VERSION "ae3c"

NS_ :

BS_:

BU_: Brightloop_Can_Loader ECU HVHV DCDC

BO_ 2147487747 BL1_Node3Status: 8 HVHV
 SG_ BPath1AcModeActivated m0 : 63|1@1+ (1,0) [0|1] ""  ECU
 SG_ BPath1AcUfpError m0 : 62|1@1+ (1,0) [0|1] ""  ECU
 SG_ BPath1AcOfpError m0 : 61|1@1+ (1,0) [0|1] ""  ECU
 SG_ NPath1AcFunctionMode m0 : 58|3@1+ (1,0) [0|7] ""  ECU
 SG_ BPath1FlgCapaError m0 : 57|1@1+ (1,0) [0|1] ""  ECU
 SG_ BPath2FlgCapaError m1 : 57|1@1+ (1,0) [0|1] ""  ECU
 SG_ BPath1ErrVAuxCell m0 : 56|1@1+ (1,0) [0|1] ""  ECU
 SG_ BPath2ErrVAuxCell m1 : 56|1@1+ (1,0) [0|1] ""  ECU
 SG_ IPath1Unbalance m0 : 48|8@1+ (0.25,0) [0|63.75] "A"  ECU
 SG_ IPath2Unbalance m1 : 48|8@1+ (0.25,0) [0|63.75] "A"  ECU
 SG_ BPath1RcpWarning m0 : 47|1@1+ (1,0) [0|1] ""  ECU
 SG_ BPath2RcpWarning m1 : 47|1@1+ (1,0) [0|1] ""  ECU
 SG_ BPath1OcpError m0 : 46|1@1+ (1,0) [0|1] ""  ECU
 SG_ BPath2OcpError m1 : 46|1@1+ (1,0) [0|1] ""  ECU
 SG_ BPath1OtpError m0 : 45|1@1+ (1,0) [0|1] ""  ECU
 SG_ BPath2OtpError m1 : 45|1@1+ (1,0) [0|1] ""  ECU
 SG_ BPath1SideBUvpError m0 : 44|1@1+ (1,0) [0|1] ""  ECU
 SG_ BPath2SideBUvpError m1 : 44|1@1+ (1,0) [0|1] ""  ECU
 SG_ BPath1SideAUvpError m0 : 43|1@1+ (1,0) [0|1] ""  ECU
 SG_ BPath2SideAUvpError m1 : 43|1@1+ (1,0) [0|1] ""  ECU
 SG_ BPath1SideBOvpError m0 : 42|1@1+ (1,0) [0|1] ""  ECU
 SG_ BPath2SideBOvpError m1 : 42|1@1+ (1,0) [0|1] ""  ECU
 SG_ BPath1SideAOvpError m0 : 41|1@1+ (1,0) [0|1] ""  ECU
 SG_ BPath2SideAOvpError m1 : 41|1@1+ (1,0) [0|1] ""  ECU
 SG_ BPath1Requested m0 : 40|1@1+ (1,0) [0|1] ""  ECU
 SG_ BPath2Requested m1 : 40|1@1+ (1,0) [0|1] ""  ECU
 SG_ NPath1CurrentSideSelected m0 : 38|2@1+ (1,0) [0|3] ""  ECU
 SG_ NPath2CurrentSideSelected m1 : 38|2@1+ (1,0) [0|3] ""  ECU
 SG_ NPath1VoltageSideSelected m0 : 36|2@1+ (1,0) [0|3] ""  ECU
 SG_ NPath2VoltageSideSelected m1 : 36|2@1+ (1,0) [0|3] ""  ECU
 SG_ NPath1State m0 : 32|4@1+ (1,0) [0|15] ""  ECU
 SG_ NPath2State m1 : 32|4@1+ (1,0) [0|15] ""  ECU
 SG_ NMultiplexer M : 29|3@1+ (1,0) [0|7] ""  ECU
 SG_ BXcpError : 28|1@1+ (1,0) [0|1] ""  ECU
 SG_ NCellHwErrorFlags : 20|8@1+ (1,0) [0|255] ""  ECU
 SG_ BSyncInputSignal : 18|1@1+ (1,0) [0|0] ""  ECU
 SG_ BSyncRequested : 17|1@1+ (1,0) [0|0] ""  ECU
 SG_ BInternalTemperatureError : 16|1@1+ (1,0) [0|1] ""  ECU
 SG_ BConfigSettingsError : 15|1@1+ (1,0) [0|1] ""  ECU
 SG_ BAuxSupplyError : 14|1@1+ (1,0) [0|1] ""  ECU
 SG_ BCanTimeoutError : 13|1@1+ (1,0) [0|1] ""  ECU
 SG_ BAuxIsoEnabled : 12|1@1+ (1,0) [0|1] ""  ECU
 SG_ BSafetyDischargeEnabled : 11|1@1+ (1,0) [0|1] ""  ECU
 SG_ BFaultSignal : 10|1@1+ (1,0) [0|1] ""  ECU
 SG_ BEnableSignal : 9|1@1+ (1,0) [0|1] ""  ECU
 SG_ BSafetyDischargeStatus : 8|1@1+ (1,0) [0|1] ""  ECU
 SG_ BSyncStatus : 7|1@1+ (1,0) [0|1] ""  ECU
 SG_ BReadConfigAndSettingsRequested : 6|1@1+ (1,0) [0|1] ""  ECU
 SG_ BSwResetModuleRequested : 5|1@1+ (1,0) [0|1] ""  ECU
 SG_ BSafetyDischargeRequested : 4|1@1+ (1,0) [0|1] ""  ECU
 SG_ NModuleState : 0|4@1+ (1,0) [0|15] ""  ECU

BO_ 2147489411 BL1_Node3Setpoints2Value: 6 HVHV
 SG_ IqPath1AcLimitLo m9 : 38|10@1+ (0.5,-256) [-256|255.5] "A"  ECU
 SG_ IqPath1AcLimitHi m9 : 28|10@1+ (0.5,-256) [-256|255.5] "A"  ECU
 SG_ PPath2LimitLo m2 : 24|16@1+ (100,-3000000) [-3000000|3553500] "W"  ECU
 SG_ IqPath1AcSetpoint m13 : 18|10@1+ (0.5,-256) [-256|255.5] "A"  ECU
 SG_ IdPath1AcLimitLo m9 : 18|10@1+ (0.5,-256) [-256|255.5] "A"  ECU
 SG_ IdPath1AcSetpoint m13 : 8|10@1+ (0.5,-256) [-256|255.5] "A"  ECU
 SG_ IdPath1AcLimitHi m9 : 8|10@1+ (0.5,-256) [-256|255.5] "A"  ECU
 SG_ PPath2LimitHi m2 : 8|16@1+ (100,-3000000) [-3000000|3553500] "W"  ECU
 SG_ NMultiplexer M : 0|5@1+ (1,0) [0|31] ""  ECU

BO_ 2147489347 BL1_Node3Setpoints1Value: 7 HVHV
 SG_ NPath1AcFunctionMode m9 : 50|3@1+ (1,0) [0|7] ""  ECU
 SG_ NPath2CurrentSideSelected m2 : 42|2@1+ (1,0) [0|3] ""  ECU
 SG_ NPath2VoltageSideSelected m2 : 40|2@1+ (1,0) [0|3] ""  ECU
 SG_ NPath1AcFrequencySetpoint m9 : 38|12@1+ (0.25,0) [0|1023.75] "Hz"  ECU
 SG_ IPath2LimitLo m2 : 28|12@1+ (0.5,-1000) [-1000|1047.5] "A"  ECU
 SG_ VqPath1AcSetpoint m9 : 27|11@1+ (1,-1024) [-1024|1023] "V"  ECU
 SG_ VdPath1AcSetpoint m9 : 16|11@1+ (1,-1024) [-1024|1023] "V"  ECU
 SG_ IPath2LimitHi m2 : 16|12@1+ (0.5,-1000) [-1000|1047.5] "A"  ECU
 SG_ VDcPath1AcSetpoint m9 : 4|12@1+ (1,0) [0|4095] "V"  ECU
 SG_ VPath2Setpoint m2 : 4|12@1+ (1,0) [0|4095] "V"  ECU
 SG_ NMultiplexer M : 0|4@1+ (1,0) [0|15] ""  ECU

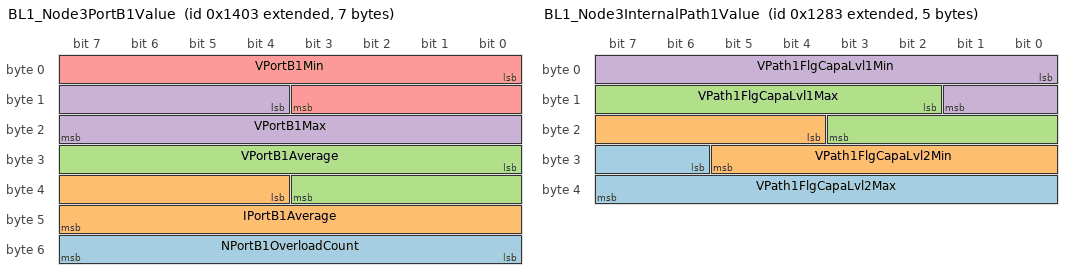
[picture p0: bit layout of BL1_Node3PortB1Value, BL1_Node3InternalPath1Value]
BO_ 2147488771 BL1_Node3PortB1Value: 7 HVHV
 SG_ NPortB1OverloadCount : 48|8@1+ (1,0) [0|255] ""  ECU
 SG_ IPortB1Average : 36|12@1+ (0.25,-500) [-500|523.75] "A"  ECU
 SG_ VPortB1Average : 24|12@1+ (1,0) [0|4095] "V"  ECU
 SG_ VPortB1Max : 12|12@1+ (1,0) [0|4095] "V"  ECU
 SG_ VPortB1Min : 0|12@1+ (1,0) [0|4095] "V"  ECU

BO_ 2147487875 BL1_Node3PortA1Value: 8 HVHV
 SG_ NMultiplexer M : 56|8@1+ (1,0) [0|255] ""  ECU
 SG_ IqPhAPortA1RMS m3 : 42|12@1+ (0.125,-256) [-256|255.875] "A"  ECU
 SG_ IqPortA1RMS m1 : 36|12@1+ (0.125,-256) [-256|255.875] "A"  ECU
 SG_ NFrequencyPortA1 m2 : 36|16@1+ (0.0125,0) [0|819.1875] "Hz"  ECU
 SG_ IqPhCPortA1RMS m4 : 36|12@1+ (0.125,-256) [-256|255.875] "A"  ECU
 SG_ IdPhAPortA1RMS m3 : 30|12@1+ (0.125,-256) [-256|255.875] "A"  ECU
 SG_ IdPortA1RMS m1 : 24|12@1+ (0.125,-256) [-256|255.875] "A"  ECU
 SG_ VphCPortA1Peak m2 : 24|12@1+ (0.5,0) [0|2047.5] "V"  ECU
 SG_ IdPhCPortA1RMS m4 : 24|12@1+ (0.125,-256) [-256|255.875] "A"  ECU
 SG_ IphCPortA1Peak m3 : 20|10@1+ (0.25,0) [0|255.75] "A"  ECU
 SG_ VqPortA1RMS m1 : 12|12@1+ (0.5,-1024) [-1024|1023.5] "V"  ECU
 SG_ VphBPortA1Peak m2 : 12|12@1+ (0.5,0) [0|2047.5] "V"  ECU
 SG_ IqPhBPortA1RMS m4 : 12|12@1+ (0.125,-256) [-256|255.875] "A"  ECU
 SG_ IphBPortA1Peak m3 : 10|10@1+ (0.25,0) [0|255.75] "A"  ECU
 SG_ VdPortA1RMS m1 : 0|12@1+ (0.5,-1024) [-1024|1023.5] "V"  ECU
 SG_ VphAPortA1Peak m2 : 0|12@1+ (0.5,0) [0|2047.5] "V"  ECU
 SG_ IphAPortA1Peak m3 : 0|10@1+ (0.25,0) [0|255.75] "A"  ECU
 SG_ IdPhBPortA1RMS m4 : 0|12@1+ (0.125,-256) [-256|255.875] "A"  ECU

BO_ 2147487939 BL1_Node3PortA2Value: 8 HVHV
 SG_ NMultiplexer M : 56|8@1+ (1,0) [0|255] ""  ECU
 SG_ NPortA2OverloadCount m0 : 48|8@1+ (1,0) [0|255] ""  ECU
 SG_ IPortA2Average m0 : 36|12@1+ (0.25,-500) [-500|523.75] "A"  ECU
 SG_ VPortA2Average m0 : 24|12@1+ (1,0) [0|4095] "V"  ECU
 SG_ VPortA2Max m0 : 12|12@1+ (1,0) [0|4095] "V"  ECU
 SG_ VPortA2Min m0 : 0|12@1+ (1,0) [0|4095] "V"  ECU

BO_ 2147488387 BL1_Node3InternalPath1Value: 5 HVHV
 SG_ VPath1FlgCapaLvl2Max : 30|10@1+ (2,0) [0|2046] "V"  ECU
 SG_ VPath1FlgCapaLvl2Min : 20|10@1+ (2,0) [0|2046] "V"  ECU
 SG_ VPath1FlgCapaLvl1Max : 10|10@1+ (2,0) [0|2046] "V"  ECU
 SG_ VPath1FlgCapaLvl1Min : 0|10@1+ (2,0) [0|2046] "V"  ECU

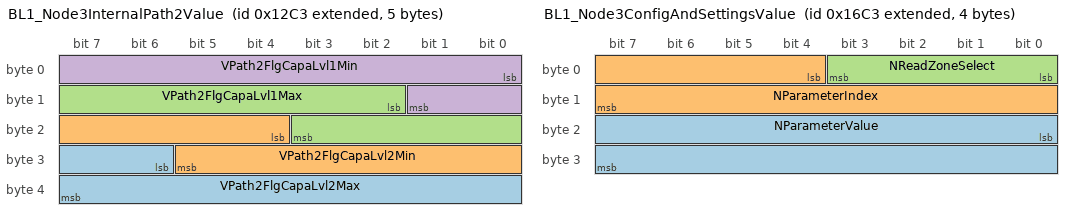
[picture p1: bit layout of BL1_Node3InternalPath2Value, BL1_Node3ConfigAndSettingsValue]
BO_ 2147488451 BL1_Node3InternalPath2Value: 5 HVHV
 SG_ VPath2FlgCapaLvl2Max : 30|10@1+ (2,0) [0|2046] "V"  ECU
 SG_ VPath2FlgCapaLvl2Min : 20|10@1+ (2,0) [0|2046] "V"  ECU
 SG_ VPath2FlgCapaLvl1Max : 10|10@1+ (2,0) [0|2046] "V"  ECU
 SG_ VPath2FlgCapaLvl1Min : 0|10@1+ (2,0) [0|2046] "V"  ECU

BO_ 2147487811 BL1_Node3GlobalValue: 7 HVHV
 SG_ NCellOtpErrorFlags m0 : 48|8@1+ (1,0) [0|255] ""  ECU
 SG_ TCell3N2 m1 : 48|8@1+ (1,-40) [-40|215] "°C"  ECU
 SG_ VAuxCell4N2 m9 : 48|8@1+ (0.15,0) [0|38.25] "V"  ECU
 SG_ TCell3N1 m1 : 40|8@1+ (1,-40) [-40|215] "°C"  ECU
 SG_ TInternal m3 : 40|8@1+ (1,-40) [-40|215] "°C"  ECU
 SG_ NBootloaderId m4 : 40|16@1+ (1,0) [0|65535] ""  ECU
 SG_ NApplicationId m5 : 40|16@1+ (1,0) [0|65535] ""  ECU
 SG_ VAuxCell3N2 m9 : 40|8@1+ (0.15,0) [0|38.25] "V"  ECU
 SG_ NSyncNodeCount m0 : 39|5@1+ (1,0) [0|31] ""  ECU
 SG_ NSyncNodeRank m0 : 34|5@1+ (1,0) [0|31] ""  ECU
 SG_ NReleaseMode m0 : 32|2@1+ (1,0) [0|3] ""  ECU
 SG_ TCell2N2 m1 : 32|8@1+ (1,-40) [-40|215] "°C"  ECU
 SG_ NCellVAuxErrorFlags m7 : 32|8@1+ (1,0) [0|65535] ""  ECU
 SG_ VAuxCell4N1 m8 : 32|8@1+ (0.15,0) [0|38.25] "V"  ECU
 SG_ VAuxCell2N2 m9 : 32|8@1+ (0.15,0) [0|38.25] "V"  ECU
 SG_ VAuxCell4N3 m10 : 32|8@1+ (0.15,0) [0|38.25] "V"  ECU
 SG_ TCell4N3 m11 : 32|8@1+ (1,-40) [-40|215] "°C"  ECU
 SG_ VAux3Measured m0 : 24|8@1+ (0.01,0) [0|2.55] "V"  ECU
 SG_ TCell2N1 m1 : 24|8@1+ (1,-40) [-40|215] "°C"  ECU
 SG_ NConfigCrc m4 : 24|16@1+ (1,0) [0|65535] ""  ECU
 SG_ NSettingsCrc m5 : 24|16@1+ (1,0) [0|65535] ""  ECU
 SG_ NSerial m6 : 24|32@1+ (1,0) [0|4294967295] ""  ECU
 SG_ VAuxCell3N1 m8 : 24|8@1+ (0.15,0) [0|38.25] "V"  ECU
 SG_ VAuxCell1N2 m9 : 24|8@1+ (0.15,0) [0|38.25] "V"  ECU
 SG_ VAuxCell3N3 m10 : 24|8@1+ (0.15,0) [0|38.25] "V"  ECU
 SG_ TCell3N3 m11 : 24|8@1+ (1,-40) [-40|215] "°C"  ECU
 SG_ VAux2Measured m0 : 16|8@1+ (0.02,0) [0|5.1] "V"  ECU
 SG_ TCell1N2 m1 : 16|8@1+ (1,-40) [-40|215] "°C"  ECU
 SG_ TCell4N2 m2 : 16|8@1+ (1,-40) [-40|215] "°C"  ECU
 SG_ NCellXcpErrorFlags m7 : 16|16@1+ (1,0) [0|65535] ""  ECU
 SG_ VAuxCell2N1 m8 : 16|8@1+ (0.15,0) [0|38.25] "V"  ECU
 SG_ VAuxCell2N3 m10 : 16|8@1+ (0.15,0) [0|38.25] "V"  ECU
 SG_ TCell2N3 m11 : 16|8@1+ (1,-40) [-40|215] "°C"  ECU
 SG_ VAux1Measured m0 : 8|8@1+ (0.15,0) [0|38.25] "V"  ECU
 SG_ TCell1N1 m1 : 8|8@1+ (1,-40) [-40|215] "°C"  ECU
 SG_ TCell4N1 m2 : 8|8@1+ (1,-40) [-40|215] "°C"  ECU
 SG_ NConfigVersion m4 : 8|16@1+ (1,0) [0|65535] ""  ECU
 SG_ NSettingsVersion m5 : 8|16@1+ (1,0) [0|65535] ""  ECU
 SG_ NChecksum m6 : 8|16@1+ (1,0) [0|65535] ""  ECU
 SG_ NCellSwOcpErrorFlags m7 : 8|8@1+ (1,0) [0|255] ""  ECU
 SG_ VAuxCell1N1 m8 : 8|8@1+ (0.15,0) [0|38.25] "V"  ECU
 SG_ VAuxCell1N3 m10 : 8|8@1+ (0.15,0) [0|38.25] "V"  ECU
 SG_ TCell1N3 m11 : 8|8@1+ (1,-40) [-40|215] "°C"  ECU
 SG_ NMultiplexer M : 0|8@1+ (1,0) [0|255] ""  ECU

BO_ 2147489475 BL1_Node3ConfigAndSettingsValue: 4 HVHV
 SG_ NParameterValue : 16|16@1+ (1,0) [0|0] ""  ECU
 SG_ NParameterIndex : 4|12@1+ (1,0) [0|0] ""  ECU
 SG_ NReadZoneSelect : 0|4@1+ (1,0) [0|0] ""  ECU

BO_ 2147489410 BL1_Node2Setpoints2Value: 6 HVHV
 SG_ PPath2LimitLo m2 : 24|16@1+ (100,-3000000) [-3000000|3553500] "W"  ECU
 SG_ PPath2LimitHi m2 : 8|16@1+ (100,-3000000) [-3000000|3553500] "W"  ECU
 SG_ NMultiplexer M : 0|5@1+ (1,0) [0|31] ""  ECU

BO_ 2147489346 BL1_Node2Setpoints1Value: 7 HVHV
 SG_ NPath2CurrentSideSelected m2 : 42|2@1+ (1,0) [0|3] ""  ECU
 SG_ NPath2VoltageSideSelected m2 : 40|2@1+ (1,0) [0|3] ""  ECU
 SG_ IPath2LimitLo m2 : 28|12@1+ (0.5,-1000) [-1000|1047.5] "A"  ECU
 SG_ IPath2LimitHi m2 : 16|12@1+ (0.5,-1000) [-1000|1047.5] "A"  ECU
 SG_ VPath2Setpoint m2 : 4|12@1+ (1,0) [0|4095] "V"  ECU
 SG_ NMultiplexer M : 0|4@1+ (1,0) [0|15] ""  ECU

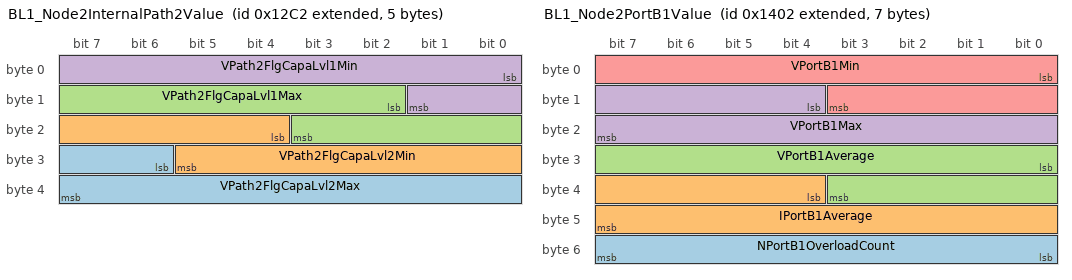
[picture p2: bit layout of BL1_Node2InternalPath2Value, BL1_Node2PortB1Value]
BO_ 2147488450 BL1_Node2InternalPath2Value: 5 HVHV
 SG_ VPath2FlgCapaLvl2Max : 30|10@1+ (2,0) [0|2046] "V"  ECU
 SG_ VPath2FlgCapaLvl2Min : 20|10@1+ (2,0) [0|2046] "V"  ECU
 SG_ VPath2FlgCapaLvl1Max : 10|10@1+ (2,0) [0|2046] "V"  ECU
 SG_ VPath2FlgCapaLvl1Min : 0|10@1+ (2,0) [0|2046] "V"  ECU

BO_ 2147488770 BL1_Node2PortB1Value: 7 HVHV
 SG_ NPortB1OverloadCount : 48|8@1+ (1,0) [0|255] ""  ECU
 SG_ IPortB1Average : 36|12@1+ (0.25,-500) [-500|523.75] "A"  ECU
 SG_ VPortB1Average : 24|12@1+ (1,0) [0|4095] "V"  ECU
 SG_ VPortB1Max : 12|12@1+ (1,0) [0|4095] "V"  ECU
 SG_ VPortB1Min : 0|12@1+ (1,0) [0|4095] "V"  ECU

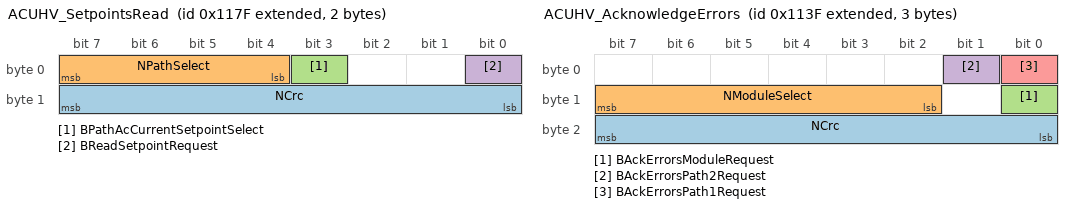
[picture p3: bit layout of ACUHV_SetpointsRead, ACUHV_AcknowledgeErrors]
BO_ 2147488127 ACUHV_SetpointsRead: 2 ECU
 SG_ NCrc : 8|8@1+ (1,0) [0|255] ""  HVHV
 SG_ NPathSelect : 4|4@1+ (1,0) [0|15] ""  HVHV
 SG_ BPathAcCurrentSetpointSelect : 3|1@1+ (1,0) [0|1] ""  HVHV
 SG_ BReadSetpointRequest : 0|1@1+ (1,0) [0|1] ""  HVHV

BO_ 2147488063 ACUHV_AcknowledgeErrors: 3 ECU
 SG_ NCrc : 16|8@1+ (1,0) [0|255] ""  HVHV
 SG_ NModuleSelect M : 10|6@1+ (1,0) [0|63] ""  HVHV
 SG_ BAckErrorsModuleRequest : 8|1@1+ (1,0) [0|1] ""  HVHV
 SG_ BAckErrorsPath2Request : 1|1@1+ (1,0) [0|1] ""  HVHV
 SG_ BAckErrorsPath1Request : 0|1@1+ (1,0) [0|1] ""  HVHV

BO_ 2147487999 ACUHV_DcSetpoints2Write: 7 ECU
 SG_ NCrc : 48|8@1+ (1,0) [0|255] ""  HVHV
 SG_ NModuleSelect M : 40|6@1+ (1,0) [0|63] ""  HVHV
 SG_ BL1_PPath2LimitLo m2 : 24|16@1+ (100,-3000000) [-3000000|3553500] "W"  HVHV
 SG_ BL2_PPath2LimitLo m2 : 24|16@1+ (100,-3000000) [-3000000|3553500] "W"  HVHV
 SG_ BL3_PPath2LimitLo m2 : 24|16@1+ (100,-3000000) [-3000000|3553500] "W"  HVHV
 SG_ BL4_PPath2LimitLo m2 : 24|16@1+ (100,-3000000) [-3000000|3553500] "W"  HVHV
 SG_ BL1_PPath2LimitHi m2 : 8|16@1+ (100,-3000000) [-3000000|3553500] "W"  HVHV
 SG_ BL2_PPath2LimitHi m2 : 8|16@1+ (100,-3000000) [-3000000|3553500] "W"  HVHV
 SG_ BL3_PPath2LimitHi m2 : 8|16@1+ (100,-3000000) [-3000000|3553500] "W"  HVHV
 SG_ BL4_PPath2LimitHi m2 : 8|16@1+ (100,-3000000) [-3000000|3553500] "W"  HVHV
 SG_ BL1_NMultiplexer m1M : 0|4@1+ (1,0) [0|15] ""  HVHV
 SG_ BL2_NMultiplexer m2M : 0|4@1+ (1,0) [0|15] ""  HVHV
 SG_ BL3_NMultiplexer m3M : 0|4@1+ (1,0) [0|15] ""  HVHV
 SG_ BL4_NMultiplexer m4M : 0|4@1+ (1,0) [0|15] ""  HVHV

BO_ 2147488191 ACUHV_AcSetpoints1Write: 8 ECU
 SG_ NCrc : 56|8@1+ (1,0) [0|255] ""  HVHV
 SG_ NModuleSelect M : 50|6@1+ (1,0) [0|63] ""  HVHV
 SG_ BL1_NPath1AcFrequencySetpoint m1 : 38|12@1+ (0.25,0) [0|1023.75] "Hz"  HVHV
 SG_ BL2_NPath1AcFrequencySetpoint m1 : 38|12@1+ (0.25,0) [0|1023.75] "Hz"  HVHV
 SG_ BL3_NPath1AcFrequencySetpoint m1 : 38|12@1+ (0.25,0) [0|1023.75] "Hz"  HVHV
 SG_ BL4_NPath1AcFrequencySetpoint m1 : 38|12@1+ (0.25,0) [0|1023.75] "Hz"  HVHV
 SG_ BL1_VqPath1AcSetpoint m1 : 27|11@1+ (1,-1024) [-1024|1023] "V"  HVHV
 SG_ BL2_VqPath1AcSetpoint m1 : 27|11@1+ (1,-1024) [-1024|1023] "V"  HVHV
 SG_ BL3_VqPath1AcSetpoint m1 : 27|11@1+ (1,-1024) [-1024|1023] "V"  HVHV
 SG_ BL4_VqPath1AcSetpoint m1 : 27|11@1+ (1,-1024) [-1024|1023] "V"  HVHV
 SG_ BL1_VdPath1AcSetpoint m1 : 16|11@1+ (1,-1024) [-1024|1023] "V"  HVHV
 SG_ BL2_VdPath1AcSetpoint m1 : 16|11@1+ (1,-1024) [-1024|1023] "V"  HVHV
 SG_ BL3_VdPath1AcSetpoint m1 : 16|11@1+ (1,-1024) [-1024|1023] "V"  HVHV
 SG_ BL4_VdPath1AcSetpoint m1 : 16|11@1+ (1,-1024) [-1024|1023] "V"  HVHV
 SG_ BL1_VDcPath1AcSetpoint m1 : 4|12@1+ (1,0) [0|4095] "V"  HVHV
 SG_ BL2_VDcPath1AcSetpoint m1 : 4|12@1+ (1,0) [0|4095] "V"  HVHV
 SG_ BL3_VDcPath1AcSetpoint m1 : 4|12@1+ (1,0) [0|4095] "V"  HVHV
 SG_ BL4_VDcPath1AcSetpoint m1 : 4|12@1+ (1,0) [0|4095] "V"  HVHV
 SG_ BL1_NMultiplexer m1M : 0|4@1+ (1,0) [0|15] ""  HVHV
 SG_ BL2_NMultiplexer m2M : 0|4@1+ (1,0) [0|15] ""  HVHV
 SG_ BL3_NMultiplexer m3M : 0|4@1+ (1,0) [0|15] ""  HVHV
 SG_ BL4_NMultiplexer m4M : 0|4@1+ (1,0) [0|15] ""  HVHV

BO_ 2147488255 ACUHV_AcSetpoints2Write: 8 ECU
 SG_ NCrc : 56|8@1+ (1,0) [0|255] ""  HVHV
 SG_ NModuleSelect M : 48|6@1+ (1,0) [0|63] ""  HVHV
 SG_ BL1_IqPath1AcLimitLo m1 : 38|10@1+ (0.5,-256) [-256|255.5] "A"  HVHV
 SG_ BL2_IqPath1AcLimitLo m1 : 38|10@1+ (0.5,-256) [-256|255.5] "A"  HVHV
 SG_ BL3_IqPath1AcLimitLo m1 : 38|10@1+ (0.5,-256) [-256|255.5] "A"  HVHV
 SG_ BL4_IqPath1AcLimitLo m1 : 38|10@1+ (0.5,-256) [-256|255.5] "A"  HVHV
 SG_ BL1_IqPath1AcLimitHi m1 : 28|10@1+ (0.5,-256) [-256|255.5] "A"  HVHV
 SG_ BL2_IqPath1AcLimitHi m1 : 28|10@1+ (0.5,-256) [-256|255.5] "A"  HVHV
 SG_ BL3_IqPath1AcLimitHi m1 : 28|10@1+ (0.5,-256) [-256|255.5] "A"  HVHV
 SG_ BL4_IqPath1AcLimitHi m1 : 28|10@1+ (0.5,-256) [-256|255.5] "A"  HVHV
 SG_ BL1_IqPath1AcSetpoint m5 : 18|10@1+ (0.5,-256) [-256|255.5] "A"  HVHV
 SG_ BL1_IdPath1AcLimitLo m1 : 18|10@1+ (0.5,-256) [-256|255.5] "A"  HVHV
 SG_ BL2_IdPath1AcLimitLo m1 : 18|10@1+ (0.5,-256) [-256|255.5] "A"  HVHV
 SG_ BL2_IqPath1AcSetpoint m5 : 18|10@1+ (0.5,-256) [-256|255.5] "A"  HVHV
 SG_ BL3_IqPath1AcSetpoint m5 : 18|10@1+ (0.5,-256) [-256|255.5] "A"  HVHV
 SG_ BL3_IdPath1AcLimitLo m1 : 18|10@1+ (0.5,-256) [-256|255.5] "A"  HVHV
 SG_ BL4_IqPath1AcSetpoint m5 : 18|10@1+ (0.5,-256) [-256|255.5] "A"  HVHV
 SG_ BL4_IdPath1AcLimitLo m1 : 18|10@1+ (0.5,-256) [-256|255.5] "A"  HVHV
 SG_ BL1_IdPath1AcSetpoint m5 : 8|10@1+ (0.5,-256) [-256|255.5] "A"  HVHV
 SG_ BL1_IdPath1AcLimitHi m1 : 8|10@1+ (0.5,-256) [-256|255.5] "A"  HVHV
 SG_ BL2_IdPath1AcLimitHi m1 : 8|10@1+ (0.5,-256) [-256|255.5] "A"  HVHV
 SG_ BL2_IdPath1AcSetpoint m5 : 8|10@1+ (0.5,-256) [-256|255.5] "A"  HVHV
 SG_ BL3_IdPath1AcSetpoint m5 : 8|10@1+ (0.5,-256) [-256|255.5] "A"  HVHV
 SG_ BL3_IdPath1AcLimitHi m1 : 8|10@1+ (0.5,-256) [-256|255.5] "A"  HVHV
 SG_ BL4_IdPath1AcSetpoint m5 : 8|10@1+ (0.5,-256) [-256|255.5] "A"  HVHV
 SG_ BL4_IdPath1AcLimitHi m1 : 8|10@1+ (0.5,-256) [-256|255.5] "A"  HVHV
 SG_ BL1_NPath1AcFunctionMode m1 : 4|3@1+ (1,0) [0|7] ""  HVHV
 SG_ BL2_NPath1AcFunctionMode m1 : 4|3@1+ (1,0) [0|7] ""  HVHV
 SG_ BL3_NPath1AcFunctionMode m1 : 4|3@1+ (1,0) [0|7] ""  HVHV
 SG_ BL4_NPath1AcFunctionMode m1 : 4|3@1+ (1,0) [0|7] ""  HVHV
 SG_ BL1_NMultiplexer m1M : 0|4@1+ (1,0) [0|15] ""  HVHV
 SG_ BL2_NMultiplexer m2M : 0|4@1+ (1,0) [0|15] ""  HVHV
 SG_ BL3_NMultiplexer m3M : 0|4@1+ (1,0) [0|15] ""  HVHV
 SG_ BL4_NMultiplexer m4M : 0|4@1+ (1,0) [0|15] ""  HVHV

BO_ 2147487938 BL1_Node2PortA2Value: 8 HVHV
 SG_ NMultiplexer M : 56|8@1+ (1,0) [0|255] ""  ECU
 SG_ NPortA2OverloadCount m0 : 48|8@1+ (1,0) [0|255] ""  ECU
 SG_ IPortA2Average m0 : 36|12@1+ (0.25,-500) [-500|523.75] "A"  ECU
 SG_ VPortA2Average m0 : 24|12@1+ (1,0) [0|4095] "V"  ECU
 SG_ VPortA2Max m0 : 12|12@1+ (1,0) [0|4095] "V"  ECU
 SG_ VPortA2Min m0 : 0|12@1+ (1,0) [0|4095] "V"  ECU

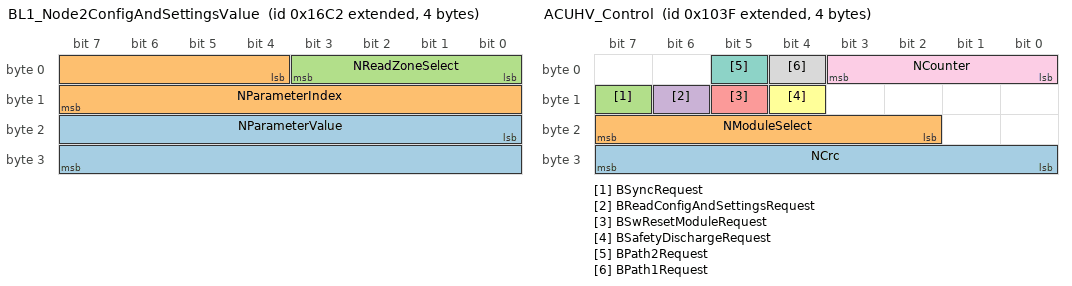
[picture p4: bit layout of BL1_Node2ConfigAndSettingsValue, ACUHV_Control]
BO_ 2147489474 BL1_Node2ConfigAndSettingsValue: 4 HVHV
 SG_ NParameterValue : 16|16@1+ (1,0) [0|0] ""  ECU
 SG_ NParameterIndex : 4|12@1+ (1,0) [0|0] ""  ECU
 SG_ NReadZoneSelect : 0|4@1+ (1,0) [0|0] ""  ECU

BO_ 2147487810 BL1_Node2GlobalValue: 7 HVHV
 SG_ NCellOtpErrorFlags m0 : 48|8@1+ (1,0) [0|255] ""  ECU
 SG_ TCell3N2 m1 : 48|8@1+ (1,-40) [-40|215] "°C"  ECU
 SG_ VAuxCell4N2 m9 : 48|8@1+ (0.15,0) [0|38.25] "V"  ECU
 SG_ TCell3N1 m1 : 40|8@1+ (1,-40) [-40|215] "°C"  ECU
 SG_ TInternal m3 : 40|8@1+ (1,-40) [-40|215] "°C"  ECU
 SG_ NBootloaderId m4 : 40|16@1+ (1,0) [0|65535] ""  ECU
 SG_ NApplicationId m5 : 40|16@1+ (1,0) [0|65535] ""  ECU
 SG_ VAuxCell3N2 m9 : 40|8@1+ (0.15,0) [0|38.25] "V"  ECU
 SG_ NSyncNodeCount m0 : 39|5@1+ (1,0) [0|31] ""  ECU
 SG_ NSyncNodeRank m0 : 34|5@1+ (1,0) [0|31] ""  ECU
 SG_ NReleaseMode m0 : 32|2@1+ (1,0) [0|3] ""  ECU
 SG_ TCell2N2 m1 : 32|8@1+ (1,-40) [-40|215] "°C"  ECU
 SG_ NCellVAuxErrorFlags m7 : 32|8@1+ (1,0) [0|65535] ""  ECU
 SG_ VAuxCell4N1 m8 : 32|8@1+ (0.15,0) [0|38.25] "V"  ECU
 SG_ VAuxCell2N2 m9 : 32|8@1+ (0.15,0) [0|38.25] "V"  ECU
 SG_ VAuxCell4N3 m10 : 32|8@1+ (0.15,0) [0|38.25] "V"  ECU
 SG_ TCell4N3 m11 : 32|8@1+ (1,-40) [-40|215] "°C"  ECU
 SG_ VAux3Measured m0 : 24|8@1+ (0.01,0) [0|2.55] "V"  ECU
 SG_ TCell2N1 m1 : 24|8@1+ (1,-40) [-40|215] "°C"  ECU
 SG_ NConfigCrc m4 : 24|16@1+ (1,0) [0|65535] ""  ECU
 SG_ NSettingsCrc m5 : 24|16@1+ (1,0) [0|65535] ""  ECU
 SG_ NSerial m6 : 24|32@1+ (1,0) [0|4294967295] ""  ECU
 SG_ VAuxCell3N1 m8 : 24|8@1+ (0.15,0) [0|38.25] "V"  ECU
 SG_ VAuxCell1N2 m9 : 24|8@1+ (0.15,0) [0|38.25] "V"  ECU
 SG_ VAuxCell3N3 m10 : 24|8@1+ (0.15,0) [0|38.25] "V"  ECU
 SG_ TCell3N3 m11 : 24|8@1+ (1,-40) [-40|215] "°C"  ECU
 SG_ VAux2Measured m0 : 16|8@1+ (0.02,0) [0|5.1] "V"  ECU
 SG_ TCell1N2 m1 : 16|8@1+ (1,-40) [-40|215] "°C"  ECU
 SG_ TCell4N2 m2 : 16|8@1+ (1,-40) [-40|215] "°C"  ECU
 SG_ NCellXcpErrorFlags m7 : 16|16@1+ (1,0) [0|65535] ""  ECU
 SG_ VAuxCell2N1 m8 : 16|8@1+ (0.15,0) [0|38.25] "V"  ECU
 SG_ VAuxCell2N3 m10 : 16|8@1+ (0.15,0) [0|38.25] "V"  ECU
 SG_ TCell2N3 m11 : 16|8@1+ (1,-40) [-40|215] "°C"  ECU
 SG_ VAux1Measured m0 : 8|8@1+ (0.15,0) [0|38.25] "V"  ECU
 SG_ TCell1N1 m1 : 8|8@1+ (1,-40) [-40|215] "°C"  ECU
 SG_ TCell4N1 m2 : 8|8@1+ (1,-40) [-40|215] "°C"  ECU
 SG_ NConfigVersion m4 : 8|16@1+ (1,0) [0|65535] ""  ECU
 SG_ NSettingsVersion m5 : 8|16@1+ (1,0) [0|65535] ""  ECU
 SG_ NChecksum m6 : 8|16@1+ (1,0) [0|65535] ""  ECU
 SG_ NCellSwOcpErrorFlags m7 : 8|8@1+ (1,0) [0|255] ""  ECU
 SG_ VAuxCell1N1 m8 : 8|8@1+ (0.15,0) [0|38.25] "V"  ECU
 SG_ VAuxCell1N3 m10 : 8|8@1+ (0.15,0) [0|38.25] "V"  ECU
 SG_ TCell1N3 m11 : 8|8@1+ (1,-40) [-40|215] "°C"  ECU
 SG_ NMultiplexer M : 0|8@1+ (1,0) [0|255] ""  ECU

BO_ 2147487746 BL1_Node2Status: 8 HVHV
 SG_ BPath2FlgCapaError m1 : 57|1@1+ (1,0) [0|1] ""  ECU
 SG_ BPath2ErrVAuxCell m1 : 56|1@1+ (1,0) [0|1] ""  ECU
 SG_ IPath2Unbalance m1 : 48|8@1+ (0.25,0) [0|63.75] "A"  ECU
 SG_ BPath2RcpWarning m1 : 47|1@1+ (1,0) [0|1] ""  ECU
 SG_ BPath2OcpError m1 : 46|1@1+ (1,0) [0|1] ""  ECU
 SG_ BPath2OtpError m1 : 45|1@1+ (1,0) [0|1] ""  ECU
 SG_ BPath2SideBUvpError m1 : 44|1@1+ (1,0) [0|1] ""  ECU
 SG_ BPath2SideAUvpError m1 : 43|1@1+ (1,0) [0|1] ""  ECU
 SG_ BPath2SideBOvpError m1 : 42|1@1+ (1,0) [0|1] ""  ECU
 SG_ BPath2SideAOvpError m1 : 41|1@1+ (1,0) [0|1] ""  ECU
 SG_ BPath2Requested m1 : 40|1@1+ (1,0) [0|1] ""  ECU
 SG_ NPath2CurrentSideSelected m1 : 38|2@1+ (1,0) [0|3] ""  ECU
 SG_ NPath2VoltageSideSelected m1 : 36|2@1+ (1,0) [0|3] ""  ECU
 SG_ NPath2State m1 : 32|4@1+ (1,0) [0|15] ""  ECU
 SG_ NMultiplexer M : 29|3@1+ (1,0) [0|7] ""  ECU
 SG_ BXcpError : 28|1@1+ (1,0) [0|1] ""  ECU
 SG_ NCellHwErrorFlags : 20|8@1+ (1,0) [0|255] ""  ECU
 SG_ BSyncInputSignal : 18|1@1+ (1,0) [0|0] ""  ECU
 SG_ BSyncRequested : 17|1@1+ (1,0) [0|0] ""  ECU
 SG_ BInternalTemperatureError : 16|1@1+ (1,0) [0|1] ""  ECU
 SG_ BConfigSettingsError : 15|1@1+ (1,0) [0|1] ""  ECU
 SG_ BAuxSupplyError : 14|1@1+ (1,0) [0|1] ""  ECU
 SG_ BCanTimeoutError : 13|1@1+ (1,0) [0|1] ""  ECU
 SG_ BAuxIsoEnabled : 12|1@1+ (1,0) [0|1] ""  ECU
 SG_ BSafetyDischargeEnabled : 11|1@1+ (1,0) [0|1] ""  ECU
 SG_ BFaultSignal : 10|1@1+ (1,0) [0|1] ""  ECU
 SG_ BEnableSignal : 9|1@1+ (1,0) [0|1] ""  ECU
 SG_ BSafetyDischargeStatus : 8|1@1+ (1,0) [0|1] ""  ECU
 SG_ BSyncStatus : 7|1@1+ (1,0) [0|1] ""  ECU
 SG_ BReadConfigAndSettingsRequested : 6|1@1+ (1,0) [0|1] ""  ECU
 SG_ BSwResetModuleRequested : 5|1@1+ (1,0) [0|1] ""  ECU
 SG_ BSafetyDischargeRequested : 4|1@1+ (1,0) [0|1] ""  ECU
 SG_ NModuleState : 0|4@1+ (1,0) [0|15] ""  ECU

BO_ 2147487935 ACUHV_DcSetpoints1Write: 8 ECU
 SG_ NCrc : 56|8@1+ (1,0) [0|255] ""  HVHV
 SG_ NModuleSelect M : 48|6@1+ (1,0) [0|63] ""  HVHV
 SG_ BL1_NPath2CurrentSideSelect m2 : 42|2@1+ (1,0) [0|3] ""  HVHV
 SG_ BL2_NPath2CurrentSideSelect m2 : 42|2@1+ (1,0) [0|3] ""  HVHV
 SG_ BL3_NPath2CurrentSideSelect m2 : 42|2@1+ (1,0) [0|3] ""  HVHV
 SG_ BL4_NPath2CurrentSideSelect m2 : 42|2@1+ (1,0) [0|3] ""  HVHV
 SG_ BL1_NPath2VoltageSideSelect m2 : 40|2@1+ (1,0) [0|3] ""  HVHV
 SG_ BL2_NPath2VoltageSideSelect m2 : 40|2@1+ (1,0) [0|3] ""  HVHV
 SG_ BL3_NPath2VoltageSideSelect m2 : 40|2@1+ (1,0) [0|3] ""  HVHV
 SG_ BL4_NPath2VoltageSideSelect m2 : 40|2@1+ (1,0) [0|3] ""  HVHV
 SG_ BL1_IPath2LimitLo m2 : 28|12@1+ (0.5,-1000) [-1000|1047.5] "A"  HVHV
 SG_ BL2_IPath2LimitLo m2 : 28|12@1+ (0.5,-1000) [-1000|1047.5] "A"  HVHV
 SG_ BL3_IPath2LimitLo m2 : 28|12@1+ (0.5,-1000) [-1000|1047.5] "A"  HVHV
 SG_ BL4_IPath2LimitLo m2 : 28|12@1+ (0.5,-1000) [-1000|1047.5] "A"  HVHV
 SG_ BL1_IPath2LimitHi m2 : 16|12@1+ (0.5,-1000) [-1000|1047.5] "A"  HVHV
 SG_ BL2_IPath2LimitHi m2 : 16|12@1+ (0.5,-1000) [-1000|1047.5] "A"  HVHV
 SG_ BL3_IPath2LimitHi m2 : 16|12@1+ (0.5,-1000) [-1000|1047.5] "A"  HVHV
 SG_ BL4_IPath2LimitHi m2 : 16|12@1+ (0.5,-1000) [-1000|1047.5] "A"  HVHV
 SG_ BL1_VPath2Setpoint m2 : 4|12@1+ (1,0) [0|4095] "V"  HVHV
 SG_ BL2_VPath2Setpoint m2 : 4|12@1+ (1,0) [0|4095] "V"  HVHV
 SG_ BL3_VPath2Setpoint m2 : 4|12@1+ (1,0) [0|4095] "V"  HVHV
 SG_ BL4_VPath2Setpoint m2 : 4|12@1+ (1,0) [0|4095] "V"  HVHV
 SG_ BL1_NMultiplexer m1M : 0|4@1+ (1,0) [0|15] ""  HVHV
 SG_ BL2_NMultiplexer m2M : 0|4@1+ (1,0) [0|15] ""  HVHV
 SG_ BL3_NMultiplexer m3M : 0|4@1+ (1,0) [0|15] ""  HVHV
 SG_ BL4_NMultiplexer m4M : 0|4@1+ (1,0) [0|15] ""  HVHV

BO_ 2147487807 ACUHV_Control: 4 ECU
 SG_ NCrc : 24|8@1+ (1,0) [0|255] ""  HVHV
 SG_ NModuleSelect M : 18|6@1+ (1,0) [0|63] ""  HVHV
 SG_ BSyncRequest : 15|1@1+ (1,0) [0|1] ""  HVHV
 SG_ BReadConfigAndSettingsRequest : 14|1@1+ (1,0) [0|1] ""  HVHV
 SG_ BSwResetModuleRequest : 13|1@1+ (1,0) [0|1] ""  HVHV
 SG_ BSafetyDischargeRequest : 12|1@1+ (1,0) [0|1] ""  HVHV
 SG_ BPath2Request : 5|1@1+ (1,0) [0|1] ""  HVHV
 SG_ BPath1Request : 4|1@1+ (1,0) [0|1] ""  HVHV
 SG_ NCounter : 0|4@1+ (1,0) [0|15] ""  HVHV

BO_ 2147487749 BL2_Node5Status: 8 HVHV
 SG_ BPath1AcModeActivated m0 : 63|1@1+ (1,0) [0|1] ""  ECU
 SG_ BPath1AcUfpError m0 : 62|1@1+ (1,0) [0|1] ""  ECU
 SG_ BPath1AcOfpError m0 : 61|1@1+ (1,0) [0|1] ""  ECU
 SG_ NPath1AcFunctionMode m0 : 58|3@1+ (1,0) [0|7] ""  ECU
 SG_ BPath2FlgCapaError m1 : 57|1@1+ (1,0) [0|1] ""  ECU
 SG_ BPath1FlgCapaError m0 : 57|1@1+ (1,0) [0|1] ""  ECU
 SG_ BPath2ErrVAuxCell m1 : 56|1@1+ (1,0) [0|1] ""  ECU
 SG_ BPath1ErrVAuxCell m0 : 56|1@1+ (1,0) [0|1] ""  ECU
 SG_ IPath2Unbalance m1 : 48|8@1+ (0.25,0) [0|63.75] "A"  ECU
 SG_ IPath1Unbalance m0 : 48|8@1+ (0.25,0) [0|63.75] "A"  ECU
 SG_ BPath2RcpWarning m1 : 47|1@1+ (1,0) [0|1] ""  ECU
 SG_ BPath1RcpWarning m0 : 47|1@1+ (1,0) [0|1] ""  ECU
 SG_ BPath2OcpError m1 : 46|1@1+ (1,0) [0|1] ""  ECU
 SG_ BPath1OcpError m0 : 46|1@1+ (1,0) [0|1] ""  ECU
 SG_ BPath2OtpError m1 : 45|1@1+ (1,0) [0|1] ""  ECU
 SG_ BPath1OtpError m0 : 45|1@1+ (1,0) [0|1] ""  ECU
 SG_ BPath2SideBUvpError m1 : 44|1@1+ (1,0) [0|1] ""  ECU
 SG_ BPath1SideBUvpError m0 : 44|1@1+ (1,0) [0|1] ""  ECU
 SG_ BPath2SideAUvpError m1 : 43|1@1+ (1,0) [0|1] ""  ECU
 SG_ BPath1SideAUvpError m0 : 43|1@1+ (1,0) [0|1] ""  ECU
 SG_ BPath2SideBOvpError m1 : 42|1@1+ (1,0) [0|1] ""  ECU
 SG_ BPath1SideBOvpError m0 : 42|1@1+ (1,0) [0|1] ""  ECU
 SG_ BPath2SideAOvpError m1 : 41|1@1+ (1,0) [0|1] ""  ECU
 SG_ BPath1SideAOvpError m0 : 41|1@1+ (1,0) [0|1] ""  ECU
 SG_ BPath2Requested m1 : 40|1@1+ (1,0) [0|1] ""  ECU
 SG_ BPath1Requested m0 : 40|1@1+ (1,0) [0|1] ""  ECU
 SG_ NPath2CurrentSideSelected m1 : 38|2@1+ (1,0) [0|3] ""  ECU
 SG_ NPath1CurrentSideSelected m0 : 38|2@1+ (1,0) [0|3] ""  ECU
 SG_ NPath2VoltageSideSelected m1 : 36|2@1+ (1,0) [0|3] ""  ECU
 SG_ NPath1VoltageSideSelected m0 : 36|2@1+ (1,0) [0|3] ""  ECU
 SG_ NPath2State m1 : 32|4@1+ (1,0) [0|15] ""  ECU
 SG_ NPath1State m0 : 32|4@1+ (1,0) [0|15] ""  ECU
 SG_ NMultiplexer M : 29|3@1+ (1,0) [0|7] ""  ECU
 SG_ BXcpError : 28|1@1+ (1,0) [0|1] ""  ECU
 SG_ NCellHwErrorFlags : 20|8@1+ (1,0) [0|255] ""  ECU
 SG_ BSyncInputSignal : 18|1@1+ (1,0) [0|0] ""  ECU
 SG_ BSyncRequested : 17|1@1+ (1,0) [0|0] ""  ECU
 SG_ BInternalTemperatureError : 16|1@1+ (1,0) [0|1] ""  ECU
 SG_ BConfigSettingsError : 15|1@1+ (1,0) [0|1] ""  ECU
 SG_ BAuxSupplyError : 14|1@1+ (1,0) [0|1] ""  ECU
 SG_ BCanTimeoutError : 13|1@1+ (1,0) [0|1] ""  ECU
 SG_ BAuxIsoEnabled : 12|1@1+ (1,0) [0|1] ""  ECU
 SG_ BSafetyDischargeEnabled : 11|1@1+ (1,0) [0|1] ""  ECU
 SG_ BFaultSignal : 10|1@1+ (1,0) [0|1] ""  ECU
 SG_ BEnableSignal : 9|1@1+ (1,0) [0|1] ""  ECU
 SG_ BSafetyDischargeStatus : 8|1@1+ (1,0) [0|1] ""  ECU
 SG_ BSyncStatus : 7|1@1+ (1,0) [0|1] ""  ECU
 SG_ BReadConfigAndSettingsRequested : 6|1@1+ (1,0) [0|1] ""  ECU
 SG_ BSwResetModuleRequested : 5|1@1+ (1,0) [0|1] ""  ECU
 SG_ BSafetyDischargeRequested : 4|1@1+ (1,0) [0|1] ""  ECU
 SG_ NModuleState : 0|4@1+ (1,0) [0|15] ""  ECU

BO_ 2147489413 BL2_Node5Setpoints2Value: 6 HVHV
 SG_ IqPath1AcLimitLo m9 : 38|10@1+ (0.5,-256) [-256|255.5] "A"  ECU
 SG_ IqPath1AcLimitHi m9 : 28|10@1+ (0.5,-256) [-256|255.5] "A"  ECU
 SG_ PPath2LimitLo m2 : 24|16@1+ (100,-3000000) [-3000000|3553500] "W"  ECU
 SG_ IdPath1AcLimitLo m9 : 18|10@1+ (0.5,-256) [-256|255.5] "A"  ECU
 SG_ IqPath1AcSetpoint m13 : 18|10@1+ (0.5,-256) [-256|255.5] "A"  ECU
 SG_ PPath2LimitHi m2 : 8|16@1+ (100,-3000000) [-3000000|3553500] "W"  ECU
 SG_ IdPath1AcLimitHi m9 : 8|10@1+ (0.5,-256) [-256|255.5] "A"  ECU
 SG_ IdPath1AcSetpoint m13 : 8|10@1+ (0.5,-256) [-256|255.5] "A"  ECU
 SG_ NMultiplexer M : 0|5@1+ (1,0) [0|31] ""  ECU

BO_ 2147489349 BL2_Node5Setpoints1Value: 7 HVHV
 SG_ NPath1AcFunctionMode m9 : 50|3@1+ (1,0) [0|7] ""  ECU
 SG_ NPath2CurrentSideSelected m2 : 42|2@1+ (1,0) [0|3] ""  ECU
 SG_ NPath2VoltageSideSelected m2 : 40|2@1+ (1,0) [0|3] ""  ECU
 SG_ NPath1AcFrequencySetpoint m9 : 38|12@1+ (0.25,0) [0|1023.75] "Hz"  ECU
 SG_ IPath2LimitLo m2 : 28|12@1+ (0.5,-1000) [-1000|1047.5] "A"  ECU
 SG_ VqPath1AcSetpoint m9 : 27|11@1+ (1,-1024) [-1024|1023] "V"  ECU
 SG_ IPath2LimitHi m2 : 16|12@1+ (0.5,-1000) [-1000|1047.5] "A"  ECU
 SG_ VdPath1AcSetpoint m9 : 16|11@1+ (1,-1024) [-1024|1023] "V"  ECU
 SG_ VPath2Setpoint m2 : 4|12@1+ (1,0) [0|4095] "V"  ECU
 SG_ VDcPath1AcSetpoint m9 : 4|12@1+ (1,0) [0|4095] "V"  ECU
 SG_ NMultiplexer M : 0|4@1+ (1,0) [0|15] ""  ECU

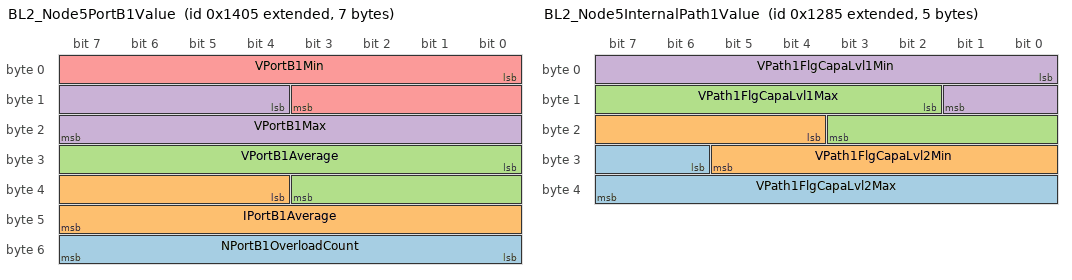
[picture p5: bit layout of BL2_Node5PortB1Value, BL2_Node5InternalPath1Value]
BO_ 2147488773 BL2_Node5PortB1Value: 7 HVHV
 SG_ NPortB1OverloadCount : 48|8@1+ (1,0) [0|255] ""  ECU
 SG_ IPortB1Average : 36|12@1+ (0.25,-500) [-500|523.75] "A"  ECU
 SG_ VPortB1Average : 24|12@1+ (1,0) [0|4095] "V"  ECU
 SG_ VPortB1Max : 12|12@1+ (1,0) [0|4095] "V"  ECU
 SG_ VPortB1Min : 0|12@1+ (1,0) [0|4095] "V"  ECU

BO_ 2147487877 BL2_Node5PortA1Value: 8 HVHV
 SG_ NMultiplexer M : 56|8@1+ (1,0) [0|255] ""  ECU
 SG_ IqPhAPortA1RMS m3 : 42|12@1+ (0.125,-256) [-256|255.875] "A"  ECU
 SG_ IqPhCPortA1RMS m4 : 36|12@1+ (0.125,-256) [-256|255.875] "A"  ECU
 SG_ NFrequencyPortA1 m2 : 36|16@1+ (0.0125,0) [0|819.1875] "Hz"  ECU
 SG_ IqPortA1RMS m1 : 36|12@1+ (0.125,-256) [-256|255.875] "A"  ECU
 SG_ IdPhAPortA1RMS m3 : 30|12@1+ (0.125,-256) [-256|255.875] "A"  ECU
 SG_ IdPhCPortA1RMS m4 : 24|12@1+ (0.125,-256) [-256|255.875] "A"  ECU
 SG_ VphCPortA1Peak m2 : 24|12@1+ (0.5,0) [0|2047.5] "V"  ECU
 SG_ IdPortA1RMS m1 : 24|12@1+ (0.125,-256) [-256|255.875] "A"  ECU
 SG_ IphCPortA1Peak m3 : 20|10@1+ (0.25,0) [0|255.75] "A"  ECU
 SG_ IqPhBPortA1RMS m4 : 12|12@1+ (0.125,-256) [-256|255.875] "A"  ECU
 SG_ VphBPortA1Peak m2 : 12|12@1+ (0.5,0) [0|2047.5] "V"  ECU
 SG_ VqPortA1RMS m1 : 12|12@1+ (0.5,-1024) [-1024|1023.5] "V"  ECU
 SG_ IphBPortA1Peak m3 : 10|10@1+ (0.25,0) [0|255.75] "A"  ECU
 SG_ IdPhBPortA1RMS m4 : 0|12@1+ (0.125,-256) [-256|255.875] "A"  ECU
 SG_ IphAPortA1Peak m3 : 0|10@1+ (0.25,0) [0|255.75] "A"  ECU
 SG_ VphAPortA1Peak m2 : 0|12@1+ (0.5,0) [0|2047.5] "V"  ECU
 SG_ VdPortA1RMS m1 : 0|12@1+ (0.5,-1024) [-1024|1023.5] "V"  ECU

BO_ 2147487941 BL2_Node5PortA2Value: 8 HVHV
 SG_ NMultiplexer M : 56|8@1+ (1,0) [0|255] ""  ECU
 SG_ NPortA2OverloadCount m0 : 48|8@1+ (1,0) [0|255] ""  ECU
 SG_ IPortA2Average m0 : 36|12@1+ (0.25,-500) [-500|523.75] "A"  ECU
 SG_ VPortA2Average m0 : 24|12@1+ (1,0) [0|4095] "V"  ECU
 SG_ VPortA2Max m0 : 12|12@1+ (1,0) [0|4095] "V"  ECU
 SG_ VPortA2Min m0 : 0|12@1+ (1,0) [0|4095] "V"  ECU

BO_ 2147488389 BL2_Node5InternalPath1Value: 5 HVHV
 SG_ VPath1FlgCapaLvl2Max : 30|10@1+ (2,0) [0|2046] "V"  ECU
 SG_ VPath1FlgCapaLvl2Min : 20|10@1+ (2,0) [0|2046] "V"  ECU
 SG_ VPath1FlgCapaLvl1Max : 10|10@1+ (2,0) [0|2046] "V"  ECU
 SG_ VPath1FlgCapaLvl1Min : 0|10@1+ (2,0) [0|2046] "V"  ECU

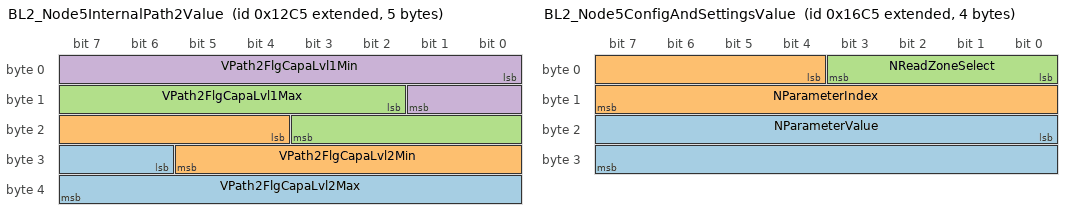
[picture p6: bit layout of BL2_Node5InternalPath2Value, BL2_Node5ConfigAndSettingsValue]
BO_ 2147488453 BL2_Node5InternalPath2Value: 5 HVHV
 SG_ VPath2FlgCapaLvl2Max : 30|10@1+ (2,0) [0|2046] "V"  ECU
 SG_ VPath2FlgCapaLvl2Min : 20|10@1+ (2,0) [0|2046] "V"  ECU
 SG_ VPath2FlgCapaLvl1Max : 10|10@1+ (2,0) [0|2046] "V"  ECU
 SG_ VPath2FlgCapaLvl1Min : 0|10@1+ (2,0) [0|2046] "V"  ECU

BO_ 2147487813 BL2_Node5GlobalValue: 7 HVHV
 SG_ VAuxCell4N2 m9 : 48|8@1+ (0.15,0) [0|38.25] "V"  ECU
 SG_ TCell3N2 m1 : 48|8@1+ (1,-40) [-40|215] "°C"  ECU
 SG_ NCellOtpErrorFlags m0 : 48|8@1+ (1,0) [0|255] ""  ECU
 SG_ VAuxCell3N2 m9 : 40|8@1+ (0.15,0) [0|38.25] "V"  ECU
 SG_ NApplicationId m5 : 40|16@1+ (1,0) [0|65535] ""  ECU
 SG_ NBootloaderId m4 : 40|16@1+ (1,0) [0|65535] ""  ECU
 SG_ TInternal m3 : 40|8@1+ (1,-40) [-40|215] "°C"  ECU
 SG_ TCell3N1 m1 : 40|8@1+ (1,-40) [-40|215] "°C"  ECU
 SG_ NSyncNodeCount m0 : 39|5@1+ (1,0) [0|31] ""  ECU
 SG_ NSyncNodeRank m0 : 34|5@1+ (1,0) [0|31] ""  ECU
 SG_ TCell4N3 m11 : 32|8@1+ (1,-40) [-40|215] "°C"  ECU
 SG_ VAuxCell4N3 m10 : 32|8@1+ (0.15,0) [0|38.25] "V"  ECU
 SG_ VAuxCell2N2 m9 : 32|8@1+ (0.15,0) [0|38.25] "V"  ECU
 SG_ VAuxCell4N1 m8 : 32|8@1+ (0.15,0) [0|38.25] "V"  ECU
 SG_ NCellVAuxErrorFlags m7 : 32|8@1+ (1,0) [0|65535] ""  ECU
 SG_ TCell2N2 m1 : 32|8@1+ (1,-40) [-40|215] "°C"  ECU
 SG_ NReleaseMode m0 : 32|2@1+ (1,0) [0|3] ""  ECU
 SG_ TCell3N3 m11 : 24|8@1+ (1,-40) [-40|215] "°C"  ECU
 SG_ VAuxCell3N3 m10 : 24|8@1+ (0.15,0) [0|38.25] "V"  ECU
 SG_ VAuxCell1N2 m9 : 24|8@1+ (0.15,0) [0|38.25] "V"  ECU
 SG_ VAuxCell3N1 m8 : 24|8@1+ (0.15,0) [0|38.25] "V"  ECU
 SG_ NSerial m6 : 24|32@1+ (1,0) [0|4294967295] ""  ECU
 SG_ NSettingsCrc m5 : 24|16@1+ (1,0) [0|65535] ""  ECU
 SG_ NConfigCrc m4 : 24|16@1+ (1,0) [0|65535] ""  ECU
 SG_ TCell2N1 m1 : 24|8@1+ (1,-40) [-40|215] "°C"  ECU
 SG_ VAux3Measured m0 : 24|8@1+ (0.01,0) [0|2.55] "V"  ECU
 SG_ TCell2N3 m11 : 16|8@1+ (1,-40) [-40|215] "°C"  ECU
 SG_ VAuxCell2N3 m10 : 16|8@1+ (0.15,0) [0|38.25] "V"  ECU
 SG_ VAuxCell2N1 m8 : 16|8@1+ (0.15,0) [0|38.25] "V"  ECU
 SG_ NCellXcpErrorFlags m7 : 16|16@1+ (1,0) [0|65535] ""  ECU
 SG_ TCell4N2 m2 : 16|8@1+ (1,-40) [-40|215] "°C"  ECU
 SG_ TCell1N2 m1 : 16|8@1+ (1,-40) [-40|215] "°C"  ECU
 SG_ VAux2Measured m0 : 16|8@1+ (0.02,0) [0|5.1] "V"  ECU
 SG_ TCell1N3 m11 : 8|8@1+ (1,-40) [-40|215] "°C"  ECU
 SG_ VAuxCell1N3 m10 : 8|8@1+ (0.15,0) [0|38.25] "V"  ECU
 SG_ VAuxCell1N1 m8 : 8|8@1+ (0.15,0) [0|38.25] "V"  ECU
 SG_ NCellSwOcpErrorFlags m7 : 8|8@1+ (1,0) [0|255] ""  ECU
 SG_ NChecksum m6 : 8|16@1+ (1,0) [0|65535] ""  ECU
 SG_ NSettingsVersion m5 : 8|16@1+ (1,0) [0|65535] ""  ECU
 SG_ NConfigVersion m4 : 8|16@1+ (1,0) [0|65535] ""  ECU
 SG_ TCell4N1 m2 : 8|8@1+ (1,-40) [-40|215] "°C"  ECU
 SG_ TCell1N1 m1 : 8|8@1+ (1,-40) [-40|215] "°C"  ECU
 SG_ VAux1Measured m0 : 8|8@1+ (0.15,0) [0|38.25] "V"  ECU
 SG_ NMultiplexer M : 0|8@1+ (1,0) [0|255] ""  ECU

BO_ 2147489477 BL2_Node5ConfigAndSettingsValue: 4 HVHV
 SG_ NParameterValue : 16|16@1+ (1,0) [0|0] ""  ECU
 SG_ NParameterIndex : 4|12@1+ (1,0) [0|0] ""  ECU
 SG_ NReadZoneSelect : 0|4@1+ (1,0) [0|0] ""  ECU

BO_ 2147489412 BL2_Node4Setpoints2Value: 6 HVHV
 SG_ IqPath1AcLimitLo m9 : 38|10@1+ (0.5,-256) [-256|255.5] "A"  ECU
 SG_ IqPath1AcLimitHi m9 : 28|10@1+ (0.5,-256) [-256|255.5] "A"  ECU
 SG_ PPath2LimitLo m2 : 24|16@1+ (100,-3000000) [-3000000|3553500] "W"  ECU
 SG_ IdPath1AcLimitLo m9 : 18|10@1+ (0.5,-256) [-256|255.5] "A"  ECU
 SG_ IqPath1AcSetpoint m13 : 18|10@1+ (0.5,-256) [-256|255.5] "A"  ECU
 SG_ PPath2LimitHi m2 : 8|16@1+ (100,-3000000) [-3000000|3553500] "W"  ECU
 SG_ IdPath1AcLimitHi m9 : 8|10@1+ (0.5,-256) [-256|255.5] "A"  ECU
 SG_ IdPath1AcSetpoint m13 : 8|10@1+ (0.5,-256) [-256|255.5] "A"  ECU
 SG_ NMultiplexer M : 0|5@1+ (1,0) [0|31] ""  ECU

BO_ 2147489348 BL2_Node4Setpoints1Value: 7 HVHV
 SG_ NPath1AcFunctionMode m9 : 50|3@1+ (1,0) [0|7] ""  ECU
 SG_ NPath2CurrentSideSelected m2 : 42|2@1+ (1,0) [0|3] ""  ECU
 SG_ NPath2VoltageSideSelected m2 : 40|2@1+ (1,0) [0|3] ""  ECU
 SG_ NPath1AcFrequencySetpoint m9 : 38|12@1+ (0.25,0) [0|1023.75] "Hz"  ECU
 SG_ IPath2LimitLo m2 : 28|12@1+ (0.5,-1000) [-1000|1047.5] "A"  ECU
 SG_ VqPath1AcSetpoint m9 : 27|11@1+ (1,-1024) [-1024|1023] "V"  ECU
 SG_ IPath2LimitHi m2 : 16|12@1+ (0.5,-1000) [-1000|1047.5] "A"  ECU
 SG_ VdPath1AcSetpoint m9 : 16|11@1+ (1,-1024) [-1024|1023] "V"  ECU
 SG_ VPath2Setpoint m2 : 4|12@1+ (1,0) [0|4095] "V"  ECU
 SG_ VDcPath1AcSetpoint m9 : 4|12@1+ (1,0) [0|4095] "V"  ECU
 SG_ NMultiplexer M : 0|4@1+ (1,0) [0|15] ""  ECU

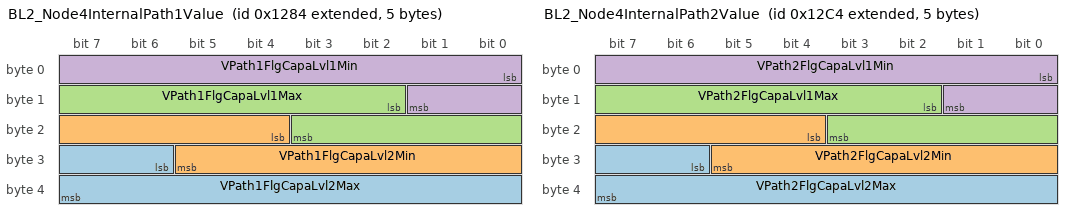
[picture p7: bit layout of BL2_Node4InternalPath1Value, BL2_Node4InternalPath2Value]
BO_ 2147488388 BL2_Node4InternalPath1Value: 5 HVHV
 SG_ VPath1FlgCapaLvl2Max : 30|10@1+ (2,0) [0|2046] "V"  ECU
 SG_ VPath1FlgCapaLvl2Min : 20|10@1+ (2,0) [0|2046] "V"  ECU
 SG_ VPath1FlgCapaLvl1Max : 10|10@1+ (2,0) [0|2046] "V"  ECU
 SG_ VPath1FlgCapaLvl1Min : 0|10@1+ (2,0) [0|2046] "V"  ECU

BO_ 2147488452 BL2_Node4InternalPath2Value: 5 HVHV
 SG_ VPath2FlgCapaLvl2Max : 30|10@1+ (2,0) [0|2046] "V"  ECU
 SG_ VPath2FlgCapaLvl2Min : 20|10@1+ (2,0) [0|2046] "V"  ECU
 SG_ VPath2FlgCapaLvl1Max : 10|10@1+ (2,0) [0|2046] "V"  ECU
 SG_ VPath2FlgCapaLvl1Min : 0|10@1+ (2,0) [0|2046] "V"  ECU

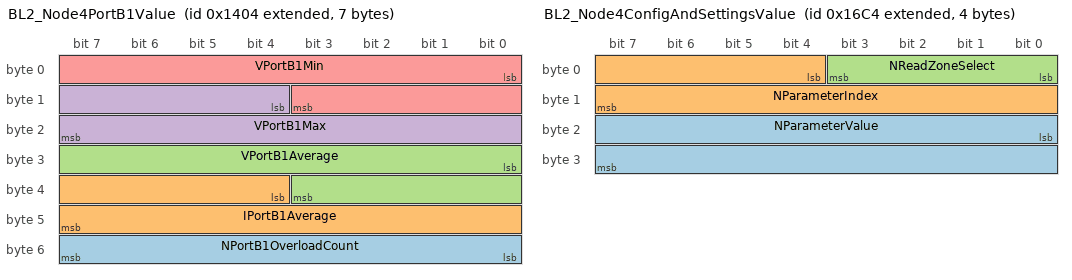
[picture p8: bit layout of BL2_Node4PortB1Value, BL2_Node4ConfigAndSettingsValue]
BO_ 2147488772 BL2_Node4PortB1Value: 7 HVHV
 SG_ NPortB1OverloadCount : 48|8@1+ (1,0) [0|255] ""  ECU
 SG_ IPortB1Average : 36|12@1+ (0.25,-500) [-500|523.75] "A"  ECU
 SG_ VPortB1Average : 24|12@1+ (1,0) [0|4095] "V"  ECU
 SG_ VPortB1Max : 12|12@1+ (1,0) [0|4095] "V"  ECU
 SG_ VPortB1Min : 0|12@1+ (1,0) [0|4095] "V"  ECU

BO_ 2147487876 BL2_Node4PortA1Value: 8 HVHV
 SG_ NMultiplexer M : 56|8@1+ (1,0) [0|255] ""  ECU
 SG_ IqPhAPortA1RMS m3 : 42|12@1+ (0.125,-256) [-256|255.875] "A"  ECU
 SG_ IqPhCPortA1RMS m4 : 36|12@1+ (0.125,-256) [-256|255.875] "A"  ECU
 SG_ NFrequencyPortA1 m2 : 36|16@1+ (0.0125,0) [0|819.1875] "Hz"  ECU
 SG_ IqPortA1RMS m1 : 36|12@1+ (0.125,-256) [-256|255.875] "A"  ECU
 SG_ IdPhAPortA1RMS m3 : 30|12@1+ (0.125,-256) [-256|255.875] "A"  ECU
 SG_ IdPhCPortA1RMS m4 : 24|12@1+ (0.125,-256) [-256|255.875] "A"  ECU
 SG_ VphCPortA1Peak m2 : 24|12@1+ (0.5,0) [0|2047.5] "V"  ECU
 SG_ IdPortA1RMS m1 : 24|12@1+ (0.125,-256) [-256|255.875] "A"  ECU
 SG_ IphCPortA1Peak m3 : 20|10@1+ (0.25,0) [0|255.75] "A"  ECU
 SG_ IqPhBPortA1RMS m4 : 12|12@1+ (0.125,-256) [-256|255.875] "A"  ECU
 SG_ VphBPortA1Peak m2 : 12|12@1+ (0.5,0) [0|2047.5] "V"  ECU
 SG_ VqPortA1RMS m1 : 12|12@1+ (0.5,-1024) [-1024|1023.5] "V"  ECU
 SG_ IphBPortA1Peak m3 : 10|10@1+ (0.25,0) [0|255.75] "A"  ECU
 SG_ IdPhBPortA1RMS m4 : 0|12@1+ (0.125,-256) [-256|255.875] "A"  ECU
 SG_ IphAPortA1Peak m3 : 0|10@1+ (0.25,0) [0|255.75] "A"  ECU
 SG_ VphAPortA1Peak m2 : 0|12@1+ (0.5,0) [0|2047.5] "V"  ECU
 SG_ VdPortA1RMS m1 : 0|12@1+ (0.5,-1024) [-1024|1023.5] "V"  ECU

BO_ 2147487940 BL2_Node4PortA2Value: 8 HVHV
 SG_ NMultiplexer M : 56|8@1+ (1,0) [0|255] ""  ECU
 SG_ NPortA2OverloadCount m0 : 48|8@1+ (1,0) [0|255] ""  ECU
 SG_ IPortA2Average m0 : 36|12@1+ (0.25,-500) [-500|523.75] "A"  ECU
 SG_ VPortA2Average m0 : 24|12@1+ (1,0) [0|4095] "V"  ECU
 SG_ VPortA2Max m0 : 12|12@1+ (1,0) [0|4095] "V"  ECU
 SG_ VPortA2Min m0 : 0|12@1+ (1,0) [0|4095] "V"  ECU

BO_ 2147489476 BL2_Node4ConfigAndSettingsValue: 4 HVHV
 SG_ NParameterValue : 16|16@1+ (1,0) [0|0] ""  ECU
 SG_ NParameterIndex : 4|12@1+ (1,0) [0|0] ""  ECU
 SG_ NReadZoneSelect : 0|4@1+ (1,0) [0|0] ""  ECU

BO_ 2147487812 BL2_Node4GlobalValue: 7 HVHV
 SG_ VAuxCell4N2 m9 : 48|8@1+ (0.15,0) [0|38.25] "V"  ECU
 SG_ TCell3N2 m1 : 48|8@1+ (1,-40) [-40|215] "°C"  ECU
 SG_ NCellOtpErrorFlags m0 : 48|8@1+ (1,0) [0|255] ""  ECU
 SG_ VAuxCell3N2 m9 : 40|8@1+ (0.15,0) [0|38.25] "V"  ECU
 SG_ NApplicationId m5 : 40|16@1+ (1,0) [0|65535] ""  ECU
 SG_ NBootloaderId m4 : 40|16@1+ (1,0) [0|65535] ""  ECU
 SG_ TInternal m3 : 40|8@1+ (1,-40) [-40|215] "°C"  ECU
 SG_ TCell3N1 m1 : 40|8@1+ (1,-40) [-40|215] "°C"  ECU
 SG_ NSyncNodeCount m0 : 39|5@1+ (1,0) [0|31] ""  ECU
 SG_ NSyncNodeRank m0 : 34|5@1+ (1,0) [0|31] ""  ECU
 SG_ TCell4N3 m11 : 32|8@1+ (1,-40) [-40|215] "°C"  ECU
 SG_ VAuxCell4N3 m10 : 32|8@1+ (0.15,0) [0|38.25] "V"  ECU
 SG_ VAuxCell2N2 m9 : 32|8@1+ (0.15,0) [0|38.25] "V"  ECU
 SG_ VAuxCell4N1 m8 : 32|8@1+ (0.15,0) [0|38.25] "V"  ECU
 SG_ NCellVAuxErrorFlags m7 : 32|8@1+ (1,0) [0|65535] ""  ECU
 SG_ TCell2N2 m1 : 32|8@1+ (1,-40) [-40|215] "°C"  ECU
 SG_ NReleaseMode m0 : 32|2@1+ (1,0) [0|3] ""  ECU
 SG_ TCell3N3 m11 : 24|8@1+ (1,-40) [-40|215] "°C"  ECU
 SG_ VAuxCell3N3 m10 : 24|8@1+ (0.15,0) [0|38.25] "V"  ECU
 SG_ VAuxCell1N2 m9 : 24|8@1+ (0.15,0) [0|38.25] "V"  ECU
 SG_ VAuxCell3N1 m8 : 24|8@1+ (0.15,0) [0|38.25] "V"  ECU
 SG_ NSerial m6 : 24|32@1+ (1,0) [0|4294967295] ""  ECU
 SG_ NSettingsCrc m5 : 24|16@1+ (1,0) [0|65535] ""  ECU
 SG_ NConfigCrc m4 : 24|16@1+ (1,0) [0|65535] ""  ECU
 SG_ TCell2N1 m1 : 24|8@1+ (1,-40) [-40|215] "°C"  ECU
 SG_ VAux3Measured m0 : 24|8@1+ (0.01,0) [0|2.55] "V"  ECU
 SG_ TCell2N3 m11 : 16|8@1+ (1,-40) [-40|215] "°C"  ECU
 SG_ VAuxCell2N3 m10 : 16|8@1+ (0.15,0) [0|38.25] "V"  ECU
 SG_ VAuxCell2N1 m8 : 16|8@1+ (0.15,0) [0|38.25] "V"  ECU
 SG_ NCellXcpErrorFlags m7 : 16|16@1+ (1,0) [0|65535] ""  ECU
 SG_ TCell4N2 m2 : 16|8@1+ (1,-40) [-40|215] "°C"  ECU
 SG_ TCell1N2 m1 : 16|8@1+ (1,-40) [-40|215] "°C"  ECU
 SG_ VAux2Measured m0 : 16|8@1+ (0.02,0) [0|5.1] "V"  ECU
 SG_ TCell1N3 m11 : 8|8@1+ (1,-40) [-40|215] "°C"  ECU
 SG_ VAuxCell1N3 m10 : 8|8@1+ (0.15,0) [0|38.25] "V"  ECU
 SG_ VAuxCell1N1 m8 : 8|8@1+ (0.15,0) [0|38.25] "V"  ECU
 SG_ NCellSwOcpErrorFlags m7 : 8|8@1+ (1,0) [0|255] ""  ECU
 SG_ NChecksum m6 : 8|16@1+ (1,0) [0|65535] ""  ECU
 SG_ NSettingsVersion m5 : 8|16@1+ (1,0) [0|65535] ""  ECU
 SG_ NConfigVersion m4 : 8|16@1+ (1,0) [0|65535] ""  ECU
 SG_ TCell4N1 m2 : 8|8@1+ (1,-40) [-40|215] "°C"  ECU
 SG_ TCell1N1 m1 : 8|8@1+ (1,-40) [-40|215] "°C"  ECU
 SG_ VAux1Measured m0 : 8|8@1+ (0.15,0) [0|38.25] "V"  ECU
 SG_ NMultiplexer M : 0|8@1+ (1,0) [0|255] ""  ECU

BO_ 2147487748 BL2_Node4Status: 8 HVHV
 SG_ BPath1AcModeActivated m0 : 63|1@1+ (1,0) [0|1] ""  ECU
 SG_ BPath1AcUfpError m0 : 62|1@1+ (1,0) [0|1] ""  ECU
 SG_ BPath1AcOfpError m0 : 61|1@1+ (1,0) [0|1] ""  ECU
 SG_ NPath1AcFunctionMode m0 : 58|3@1+ (1,0) [0|7] ""  ECU
 SG_ BPath2FlgCapaError m1 : 57|1@1+ (1,0) [0|1] ""  ECU
 SG_ BPath1FlgCapaError m0 : 57|1@1+ (1,0) [0|1] ""  ECU
 SG_ BPath2ErrVAuxCell m1 : 56|1@1+ (1,0) [0|1] ""  ECU
 SG_ BPath1ErrVAuxCell m0 : 56|1@1+ (1,0) [0|1] ""  ECU
 SG_ IPath2Unbalance m1 : 48|8@1+ (0.25,0) [0|63.75] "A"  ECU
 SG_ IPath1Unbalance m0 : 48|8@1+ (0.25,0) [0|63.75] "A"  ECU
 SG_ BPath2RcpWarning m1 : 47|1@1+ (1,0) [0|1] ""  ECU
 SG_ BPath1RcpWarning m0 : 47|1@1+ (1,0) [0|1] ""  ECU
 SG_ BPath2OcpError m1 : 46|1@1+ (1,0) [0|1] ""  ECU
 SG_ BPath1OcpError m0 : 46|1@1+ (1,0) [0|1] ""  ECU
 SG_ BPath2OtpError m1 : 45|1@1+ (1,0) [0|1] ""  ECU
 SG_ BPath1OtpError m0 : 45|1@1+ (1,0) [0|1] ""  ECU
 SG_ BPath2SideBUvpError m1 : 44|1@1+ (1,0) [0|1] ""  ECU
 SG_ BPath1SideBUvpError m0 : 44|1@1+ (1,0) [0|1] ""  ECU
 SG_ BPath2SideAUvpError m1 : 43|1@1+ (1,0) [0|1] ""  ECU
 SG_ BPath1SideAUvpError m0 : 43|1@1+ (1,0) [0|1] ""  ECU
 SG_ BPath2SideBOvpError m1 : 42|1@1+ (1,0) [0|1] ""  ECU
 SG_ BPath1SideBOvpError m0 : 42|1@1+ (1,0) [0|1] ""  ECU
 SG_ BPath2SideAOvpError m1 : 41|1@1+ (1,0) [0|1] ""  ECU
 SG_ BPath1SideAOvpError m0 : 41|1@1+ (1,0) [0|1] ""  ECU
 SG_ BPath2Requested m1 : 40|1@1+ (1,0) [0|1] ""  ECU
 SG_ BPath1Requested m0 : 40|1@1+ (1,0) [0|1] ""  ECU
 SG_ NPath2CurrentSideSelected m1 : 38|2@1+ (1,0) [0|3] ""  ECU
 SG_ NPath1CurrentSideSelected m0 : 38|2@1+ (1,0) [0|3] ""  ECU
 SG_ NPath2VoltageSideSelected m1 : 36|2@1+ (1,0) [0|3] ""  ECU
 SG_ NPath1VoltageSideSelected m0 : 36|2@1+ (1,0) [0|3] ""  ECU
 SG_ NPath2State m1 : 32|4@1+ (1,0) [0|15] ""  ECU
 SG_ NPath1State m0 : 32|4@1+ (1,0) [0|15] ""  ECU
 SG_ NMultiplexer M : 29|3@1+ (1,0) [0|7] ""  ECU
 SG_ BXcpError : 28|1@1+ (1,0) [0|1] ""  ECU
 SG_ NCellHwErrorFlags : 20|8@1+ (1,0) [0|255] ""  ECU
 SG_ BSyncInputSignal : 18|1@1+ (1,0) [0|0] ""  ECU
 SG_ BSyncRequested : 17|1@1+ (1,0) [0|0] ""  ECU
 SG_ BInternalTemperatureError : 16|1@1+ (1,0) [0|1] ""  ECU
 SG_ BConfigSettingsError : 15|1@1+ (1,0) [0|1] ""  ECU
 SG_ BAuxSupplyError : 14|1@1+ (1,0) [0|1] ""  ECU
 SG_ BCanTimeoutError : 13|1@1+ (1,0) [0|1] ""  ECU
 SG_ BAuxIsoEnabled : 12|1@1+ (1,0) [0|1] ""  ECU
 SG_ BSafetyDischargeEnabled : 11|1@1+ (1,0) [0|1] ""  ECU
 SG_ BFaultSignal : 10|1@1+ (1,0) [0|1] ""  ECU
 SG_ BEnableSignal : 9|1@1+ (1,0) [0|1] ""  ECU
 SG_ BSafetyDischargeStatus : 8|1@1+ (1,0) [0|1] ""  ECU
 SG_ BSyncStatus : 7|1@1+ (1,0) [0|1] ""  ECU
 SG_ BReadConfigAndSettingsRequested : 6|1@1+ (1,0) [0|1] ""  ECU
 SG_ BSwResetModuleRequested : 5|1@1+ (1,0) [0|1] ""  ECU
 SG_ BSafetyDischargeRequested : 4|1@1+ (1,0) [0|1] ""  ECU
 SG_ NModuleState : 0|4@1+ (1,0) [0|15] ""  ECU

BO_ 2147487751 BL3_Node7Status: 8 HVHV
 SG_ BPath1AcModeActivated m0 : 63|1@1+ (1,0) [0|1] ""  ECU
 SG_ BPath1AcUfpError m0 : 62|1@1+ (1,0) [0|1] ""  ECU
 SG_ BPath1AcOfpError m0 : 61|1@1+ (1,0) [0|1] ""  ECU
 SG_ NPath1AcFunctionMode m0 : 58|3@1+ (1,0) [0|7] ""  ECU
 SG_ BPath1FlgCapaError m0 : 57|1@1+ (1,0) [0|1] ""  ECU
 SG_ BPath2FlgCapaError m1 : 57|1@1+ (1,0) [0|1] ""  ECU
 SG_ BPath1ErrVAuxCell m0 : 56|1@1+ (1,0) [0|1] ""  ECU
 SG_ BPath2ErrVAuxCell m1 : 56|1@1+ (1,0) [0|1] ""  ECU
 SG_ IPath1Unbalance m0 : 48|8@1+ (0.25,0) [0|63.75] "A"  ECU
 SG_ IPath2Unbalance m1 : 48|8@1+ (0.25,0) [0|63.75] "A"  ECU
 SG_ BPath1RcpWarning m0 : 47|1@1+ (1,0) [0|1] ""  ECU
 SG_ BPath2RcpWarning m1 : 47|1@1+ (1,0) [0|1] ""  ECU
 SG_ BPath1OcpError m0 : 46|1@1+ (1,0) [0|1] ""  ECU
 SG_ BPath2OcpError m1 : 46|1@1+ (1,0) [0|1] ""  ECU
 SG_ BPath1OtpError m0 : 45|1@1+ (1,0) [0|1] ""  ECU
 SG_ BPath2OtpError m1 : 45|1@1+ (1,0) [0|1] ""  ECU
 SG_ BPath1SideBUvpError m0 : 44|1@1+ (1,0) [0|1] ""  ECU
 SG_ BPath2SideBUvpError m1 : 44|1@1+ (1,0) [0|1] ""  ECU
 SG_ BPath1SideAUvpError m0 : 43|1@1+ (1,0) [0|1] ""  ECU
 SG_ BPath2SideAUvpError m1 : 43|1@1+ (1,0) [0|1] ""  ECU
 SG_ BPath1SideBOvpError m0 : 42|1@1+ (1,0) [0|1] ""  ECU
 SG_ BPath2SideBOvpError m1 : 42|1@1+ (1,0) [0|1] ""  ECU
 SG_ BPath1SideAOvpError m0 : 41|1@1+ (1,0) [0|1] ""  ECU
 SG_ BPath2SideAOvpError m1 : 41|1@1+ (1,0) [0|1] ""  ECU
 SG_ BPath1Requested m0 : 40|1@1+ (1,0) [0|1] ""  ECU
 SG_ BPath2Requested m1 : 40|1@1+ (1,0) [0|1] ""  ECU
 SG_ NPath1CurrentSideSelected m0 : 38|2@1+ (1,0) [0|3] ""  ECU
 SG_ NPath2CurrentSideSelected m1 : 38|2@1+ (1,0) [0|3] ""  ECU
 SG_ NPath1VoltageSideSelected m0 : 36|2@1+ (1,0) [0|3] ""  ECU
 SG_ NPath2VoltageSideSelected m1 : 36|2@1+ (1,0) [0|3] ""  ECU
 SG_ NPath1State m0 : 32|4@1+ (1,0) [0|15] ""  ECU
 SG_ NPath2State m1 : 32|4@1+ (1,0) [0|15] ""  ECU
 SG_ NMultiplexer M : 29|3@1+ (1,0) [0|7] ""  ECU
 SG_ BXcpError : 28|1@1+ (1,0) [0|1] ""  ECU
 SG_ NCellHwErrorFlags : 20|8@1+ (1,0) [0|255] ""  ECU
 SG_ BSyncInputSignal : 18|1@1+ (1,0) [0|0] ""  ECU
 SG_ BSyncRequested : 17|1@1+ (1,0) [0|0] ""  ECU
 SG_ BInternalTemperatureError : 16|1@1+ (1,0) [0|1] ""  ECU
 SG_ BConfigSettingsError : 15|1@1+ (1,0) [0|1] ""  ECU
 SG_ BAuxSupplyError : 14|1@1+ (1,0) [0|1] ""  ECU
 SG_ BCanTimeoutError : 13|1@1+ (1,0) [0|1] ""  ECU
 SG_ BAuxIsoEnabled : 12|1@1+ (1,0) [0|1] ""  ECU
 SG_ BSafetyDischargeEnabled : 11|1@1+ (1,0) [0|1] ""  ECU
 SG_ BFaultSignal : 10|1@1+ (1,0) [0|1] ""  ECU
 SG_ BEnableSignal : 9|1@1+ (1,0) [0|1] ""  ECU
 SG_ BSafetyDischargeStatus : 8|1@1+ (1,0) [0|1] ""  ECU
 SG_ BSyncStatus : 7|1@1+ (1,0) [0|1] ""  ECU
 SG_ BReadConfigAndSettingsRequested : 6|1@1+ (1,0) [0|1] ""  ECU
 SG_ BSwResetModuleRequested : 5|1@1+ (1,0) [0|1] ""  ECU
 SG_ BSafetyDischargeRequested : 4|1@1+ (1,0) [0|1] ""  ECU
 SG_ NModuleState : 0|4@1+ (1,0) [0|15] ""  ECU

BO_ 2147489415 BL3_Node7Setpoints2Value: 6 HVHV
 SG_ IqPath1AcLimitLo m9 : 38|10@1+ (0.5,-256) [-256|255.5] "A"  ECU
 SG_ IqPath1AcLimitHi m9 : 28|10@1+ (0.5,-256) [-256|255.5] "A"  ECU
 SG_ PPath2LimitLo m2 : 24|16@1+ (100,-3000000) [-3000000|3553500] "W"  ECU
 SG_ IqPath1AcSetpoint m13 : 18|10@1+ (0.5,-256) [-256|255.5] "A"  ECU
 SG_ IdPath1AcLimitLo m9 : 18|10@1+ (0.5,-256) [-256|255.5] "A"  ECU
 SG_ IdPath1AcSetpoint m13 : 8|10@1+ (0.5,-256) [-256|255.5] "A"  ECU
 SG_ IdPath1AcLimitHi m9 : 8|10@1+ (0.5,-256) [-256|255.5] "A"  ECU
 SG_ PPath2LimitHi m2 : 8|16@1+ (100,-3000000) [-3000000|3553500] "W"  ECU
 SG_ NMultiplexer M : 0|5@1+ (1,0) [0|31] ""  ECU

BO_ 2147489351 BL3_Node7Setpoints1Value: 7 HVHV
 SG_ NPath1AcFunctionMode m9 : 50|3@1+ (1,0) [0|7] ""  ECU
 SG_ NPath2CurrentSideSelected m2 : 42|2@1+ (1,0) [0|3] ""  ECU
 SG_ NPath2VoltageSideSelected m2 : 40|2@1+ (1,0) [0|3] ""  ECU
 SG_ NPath1AcFrequencySetpoint m9 : 38|12@1+ (0.25,0) [0|1023.75] "Hz"  ECU
 SG_ IPath2LimitLo m2 : 28|12@1+ (0.5,-1000) [-1000|1047.5] "A"  ECU
 SG_ VqPath1AcSetpoint m9 : 27|11@1+ (1,-1024) [-1024|1023] "V"  ECU
 SG_ VdPath1AcSetpoint m9 : 16|11@1+ (1,-1024) [-1024|1023] "V"  ECU
 SG_ IPath2LimitHi m2 : 16|12@1+ (0.5,-1000) [-1000|1047.5] "A"  ECU
 SG_ VDcPath1AcSetpoint m9 : 4|12@1+ (1,0) [0|4095] "V"  ECU
 SG_ VPath2Setpoint m2 : 4|12@1+ (1,0) [0|4095] "V"  ECU
 SG_ NMultiplexer M : 0|4@1+ (1,0) [0|15] ""  ECU

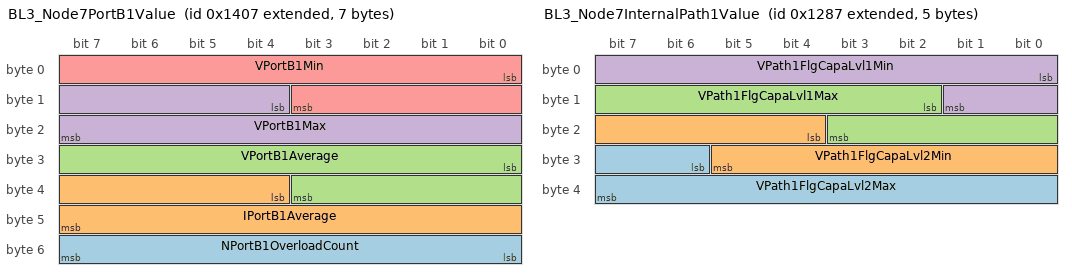
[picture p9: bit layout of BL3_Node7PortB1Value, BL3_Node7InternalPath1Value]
BO_ 2147488775 BL3_Node7PortB1Value: 7 HVHV
 SG_ NPortB1OverloadCount : 48|8@1+ (1,0) [0|255] ""  ECU
 SG_ IPortB1Average : 36|12@1+ (0.25,-500) [-500|523.75] "A"  ECU
 SG_ VPortB1Average : 24|12@1+ (1,0) [0|4095] "V"  ECU
 SG_ VPortB1Max : 12|12@1+ (1,0) [0|4095] "V"  ECU
 SG_ VPortB1Min : 0|12@1+ (1,0) [0|4095] "V"  ECU

BO_ 2147487879 BL3_Node7PortA1Value: 8 HVHV
 SG_ NMultiplexer M : 56|8@1+ (1,0) [0|255] ""  ECU
 SG_ IqPhAPortA1RMS m3 : 42|12@1+ (0.125,-256) [-256|255.875] "A"  ECU
 SG_ IqPortA1RMS m1 : 36|12@1+ (0.125,-256) [-256|255.875] "A"  ECU
 SG_ NFrequencyPortA1 m2 : 36|16@1+ (0.0125,0) [0|819.1875] "Hz"  ECU
 SG_ IqPhCPortA1RMS m4 : 36|12@1+ (0.125,-256) [-256|255.875] "A"  ECU
 SG_ IdPhAPortA1RMS m3 : 30|12@1+ (0.125,-256) [-256|255.875] "A"  ECU
 SG_ IdPortA1RMS m1 : 24|12@1+ (0.125,-256) [-256|255.875] "A"  ECU
 SG_ VphCPortA1Peak m2 : 24|12@1+ (0.5,0) [0|2047.5] "V"  ECU
 SG_ IdPhCPortA1RMS m4 : 24|12@1+ (0.125,-256) [-256|255.875] "A"  ECU
 SG_ IphCPortA1Peak m3 : 20|10@1+ (0.25,0) [0|255.75] "A"  ECU
 SG_ VqPortA1RMS m1 : 12|12@1+ (0.5,-1024) [-1024|1023.5] "V"  ECU
 SG_ VphBPortA1Peak m2 : 12|12@1+ (0.5,0) [0|2047.5] "V"  ECU
 SG_ IqPhBPortA1RMS m4 : 12|12@1+ (0.125,-256) [-256|255.875] "A"  ECU
 SG_ IphBPortA1Peak m3 : 10|10@1+ (0.25,0) [0|255.75] "A"  ECU
 SG_ VdPortA1RMS m1 : 0|12@1+ (0.5,-1024) [-1024|1023.5] "V"  ECU
 SG_ VphAPortA1Peak m2 : 0|12@1+ (0.5,0) [0|2047.5] "V"  ECU
 SG_ IphAPortA1Peak m3 : 0|10@1+ (0.25,0) [0|255.75] "A"  ECU
 SG_ IdPhBPortA1RMS m4 : 0|12@1+ (0.125,-256) [-256|255.875] "A"  ECU

BO_ 2147487943 BL3_Node7PortA2Value: 8 HVHV
 SG_ NMultiplexer M : 56|8@1+ (1,0) [0|255] ""  ECU
 SG_ NPortA2OverloadCount m0 : 48|8@1+ (1,0) [0|255] ""  ECU
 SG_ IPortA2Average m0 : 36|12@1+ (0.25,-500) [-500|523.75] "A"  ECU
 SG_ VPortA2Average m0 : 24|12@1+ (1,0) [0|4095] "V"  ECU
 SG_ VPortA2Max m0 : 12|12@1+ (1,0) [0|4095] "V"  ECU
 SG_ VPortA2Min m0 : 0|12@1+ (1,0) [0|4095] "V"  ECU

BO_ 2147488391 BL3_Node7InternalPath1Value: 5 HVHV
 SG_ VPath1FlgCapaLvl2Max : 30|10@1+ (2,0) [0|2046] "V"  ECU
 SG_ VPath1FlgCapaLvl2Min : 20|10@1+ (2,0) [0|2046] "V"  ECU
 SG_ VPath1FlgCapaLvl1Max : 10|10@1+ (2,0) [0|2046] "V"  ECU
 SG_ VPath1FlgCapaLvl1Min : 0|10@1+ (2,0) [0|2046] "V"  ECU

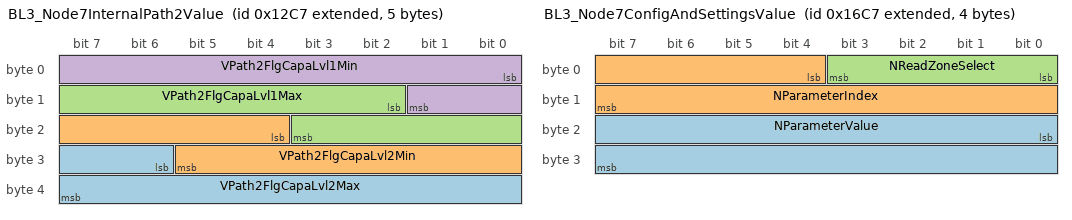
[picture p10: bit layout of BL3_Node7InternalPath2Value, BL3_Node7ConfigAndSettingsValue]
BO_ 2147488455 BL3_Node7InternalPath2Value: 5 HVHV
 SG_ VPath2FlgCapaLvl2Max : 30|10@1+ (2,0) [0|2046] "V"  ECU
 SG_ VPath2FlgCapaLvl2Min : 20|10@1+ (2,0) [0|2046] "V"  ECU
 SG_ VPath2FlgCapaLvl1Max : 10|10@1+ (2,0) [0|2046] "V"  ECU
 SG_ VPath2FlgCapaLvl1Min : 0|10@1+ (2,0) [0|2046] "V"  ECU

BO_ 2147487815 BL3_Node7GlobalValue: 7 HVHV
 SG_ NCellOtpErrorFlags m0 : 48|8@1+ (1,0) [0|255] ""  ECU
 SG_ TCell3N2 m1 : 48|8@1+ (1,-40) [-40|215] "°C"  ECU
 SG_ VAuxCell4N2 m9 : 48|8@1+ (0.15,0) [0|38.25] "V"  ECU
 SG_ TCell3N1 m1 : 40|8@1+ (1,-40) [-40|215] "°C"  ECU
 SG_ TInternal m3 : 40|8@1+ (1,-40) [-40|215] "°C"  ECU
 SG_ NBootloaderId m4 : 40|16@1+ (1,0) [0|65535] ""  ECU
 SG_ NApplicationId m5 : 40|16@1+ (1,0) [0|65535] ""  ECU
 SG_ VAuxCell3N2 m9 : 40|8@1+ (0.15,0) [0|38.25] "V"  ECU
 SG_ NSyncNodeCount m0 : 39|5@1+ (1,0) [0|31] ""  ECU
 SG_ NSyncNodeRank m0 : 34|5@1+ (1,0) [0|31] ""  ECU
 SG_ NReleaseMode m0 : 32|2@1+ (1,0) [0|3] ""  ECU
 SG_ TCell2N2 m1 : 32|8@1+ (1,-40) [-40|215] "°C"  ECU
 SG_ NCellVAuxErrorFlags m7 : 32|8@1+ (1,0) [0|65535] ""  ECU
 SG_ VAuxCell4N1 m8 : 32|8@1+ (0.15,0) [0|38.25] "V"  ECU
 SG_ VAuxCell2N2 m9 : 32|8@1+ (0.15,0) [0|38.25] "V"  ECU
 SG_ VAuxCell4N3 m10 : 32|8@1+ (0.15,0) [0|38.25] "V"  ECU
 SG_ TCell4N3 m11 : 32|8@1+ (1,-40) [-40|215] "°C"  ECU
 SG_ VAux3Measured m0 : 24|8@1+ (0.01,0) [0|2.55] "V"  ECU
 SG_ TCell2N1 m1 : 24|8@1+ (1,-40) [-40|215] "°C"  ECU
 SG_ NConfigCrc m4 : 24|16@1+ (1,0) [0|65535] ""  ECU
 SG_ NSettingsCrc m5 : 24|16@1+ (1,0) [0|65535] ""  ECU
 SG_ NSerial m6 : 24|32@1+ (1,0) [0|4294967295] ""  ECU
 SG_ VAuxCell3N1 m8 : 24|8@1+ (0.15,0) [0|38.25] "V"  ECU
 SG_ VAuxCell1N2 m9 : 24|8@1+ (0.15,0) [0|38.25] "V"  ECU
 SG_ VAuxCell3N3 m10 : 24|8@1+ (0.15,0) [0|38.25] "V"  ECU
 SG_ TCell3N3 m11 : 24|8@1+ (1,-40) [-40|215] "°C"  ECU
 SG_ VAux2Measured m0 : 16|8@1+ (0.02,0) [0|5.1] "V"  ECU
 SG_ TCell1N2 m1 : 16|8@1+ (1,-40) [-40|215] "°C"  ECU
 SG_ TCell4N2 m2 : 16|8@1+ (1,-40) [-40|215] "°C"  ECU
 SG_ NCellXcpErrorFlags m7 : 16|16@1+ (1,0) [0|65535] ""  ECU
 SG_ VAuxCell2N1 m8 : 16|8@1+ (0.15,0) [0|38.25] "V"  ECU
 SG_ VAuxCell2N3 m10 : 16|8@1+ (0.15,0) [0|38.25] "V"  ECU
 SG_ TCell2N3 m11 : 16|8@1+ (1,-40) [-40|215] "°C"  ECU
 SG_ VAux1Measured m0 : 8|8@1+ (0.15,0) [0|38.25] "V"  ECU
 SG_ TCell1N1 m1 : 8|8@1+ (1,-40) [-40|215] "°C"  ECU
 SG_ TCell4N1 m2 : 8|8@1+ (1,-40) [-40|215] "°C"  ECU
 SG_ NConfigVersion m4 : 8|16@1+ (1,0) [0|65535] ""  ECU
 SG_ NSettingsVersion m5 : 8|16@1+ (1,0) [0|65535] ""  ECU
 SG_ NChecksum m6 : 8|16@1+ (1,0) [0|65535] ""  ECU
 SG_ NCellSwOcpErrorFlags m7 : 8|8@1+ (1,0) [0|255] ""  ECU
 SG_ VAuxCell1N1 m8 : 8|8@1+ (0.15,0) [0|38.25] "V"  ECU
 SG_ VAuxCell1N3 m10 : 8|8@1+ (0.15,0) [0|38.25] "V"  ECU
 SG_ TCell1N3 m11 : 8|8@1+ (1,-40) [-40|215] "°C"  ECU
 SG_ NMultiplexer M : 0|8@1+ (1,0) [0|255] ""  ECU

BO_ 2147489479 BL3_Node7ConfigAndSettingsValue: 4 HVHV
 SG_ NParameterValue : 16|16@1+ (1,0) [0|0] ""  ECU
 SG_ NParameterIndex : 4|12@1+ (1,0) [0|0] ""  ECU
 SG_ NReadZoneSelect : 0|4@1+ (1,0) [0|0] ""  ECU

BO_ 2147489414 BL3_Node6Setpoints2Value: 6 HVHV
 SG_ IqPath1AcLimitLo m9 : 38|10@1+ (0.5,-256) [-256|255.5] "A"  ECU
 SG_ IqPath1AcLimitHi m9 : 28|10@1+ (0.5,-256) [-256|255.5] "A"  ECU
 SG_ PPath2LimitLo m2 : 24|16@1+ (100,-3000000) [-3000000|3553500] "W"  ECU
 SG_ IqPath1AcSetpoint m13 : 18|10@1+ (0.5,-256) [-256|255.5] "A"  ECU
 SG_ IdPath1AcLimitLo m9 : 18|10@1+ (0.5,-256) [-256|255.5] "A"  ECU
 SG_ IdPath1AcSetpoint m13 : 8|10@1+ (0.5,-256) [-256|255.5] "A"  ECU
 SG_ IdPath1AcLimitHi m9 : 8|10@1+ (0.5,-256) [-256|255.5] "A"  ECU
 SG_ PPath2LimitHi m2 : 8|16@1+ (100,-3000000) [-3000000|3553500] "W"  ECU
 SG_ NMultiplexer M : 0|5@1+ (1,0) [0|31] ""  ECU

BO_ 2147489350 BL3_Node6Setpoints1Value: 7 HVHV
 SG_ NPath1AcFunctionMode m9 : 50|3@1+ (1,0) [0|7] ""  ECU
 SG_ NPath2CurrentSideSelected m2 : 42|2@1+ (1,0) [0|3] ""  ECU
 SG_ NPath2VoltageSideSelected m2 : 40|2@1+ (1,0) [0|3] ""  ECU
 SG_ NPath1AcFrequencySetpoint m9 : 38|12@1+ (0.25,0) [0|1023.75] "Hz"  ECU
 SG_ IPath2LimitLo m2 : 28|12@1+ (0.5,-1000) [-1000|1047.5] "A"  ECU
 SG_ VqPath1AcSetpoint m9 : 27|11@1+ (1,-1024) [-1024|1023] "V"  ECU
 SG_ VdPath1AcSetpoint m9 : 16|11@1+ (1,-1024) [-1024|1023] "V"  ECU
 SG_ IPath2LimitHi m2 : 16|12@1+ (0.5,-1000) [-1000|1047.5] "A"  ECU
 SG_ VDcPath1AcSetpoint m9 : 4|12@1+ (1,0) [0|4095] "V"  ECU
 SG_ VPath2Setpoint m2 : 4|12@1+ (1,0) [0|4095] "V"  ECU
 SG_ NMultiplexer M : 0|4@1+ (1,0) [0|15] ""  ECU

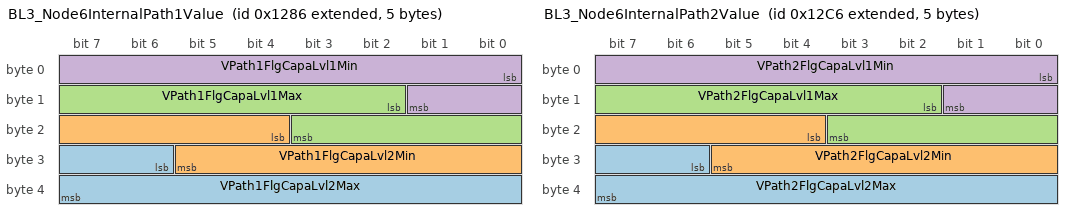
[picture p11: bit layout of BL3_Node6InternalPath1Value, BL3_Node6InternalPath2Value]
BO_ 2147488390 BL3_Node6InternalPath1Value: 5 HVHV
 SG_ VPath1FlgCapaLvl2Max : 30|10@1+ (2,0) [0|2046] "V"  ECU
 SG_ VPath1FlgCapaLvl2Min : 20|10@1+ (2,0) [0|2046] "V"  ECU
 SG_ VPath1FlgCapaLvl1Max : 10|10@1+ (2,0) [0|2046] "V"  ECU
 SG_ VPath1FlgCapaLvl1Min : 0|10@1+ (2,0) [0|2046] "V"  ECU

BO_ 2147488454 BL3_Node6InternalPath2Value: 5 HVHV
 SG_ VPath2FlgCapaLvl2Max : 30|10@1+ (2,0) [0|2046] "V"  ECU
 SG_ VPath2FlgCapaLvl2Min : 20|10@1+ (2,0) [0|2046] "V"  ECU
 SG_ VPath2FlgCapaLvl1Max : 10|10@1+ (2,0) [0|2046] "V"  ECU
 SG_ VPath2FlgCapaLvl1Min : 0|10@1+ (2,0) [0|2046] "V"  ECU

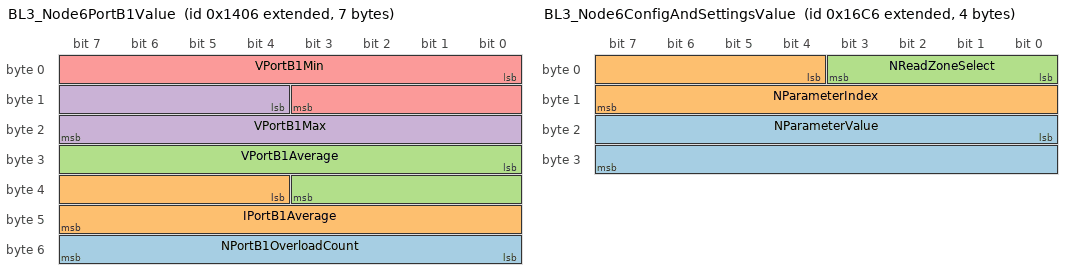
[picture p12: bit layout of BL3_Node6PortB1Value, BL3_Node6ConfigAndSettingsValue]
BO_ 2147488774 BL3_Node6PortB1Value: 7 HVHV
 SG_ NPortB1OverloadCount : 48|8@1+ (1,0) [0|255] ""  ECU
 SG_ IPortB1Average : 36|12@1+ (0.25,-500) [-500|523.75] "A"  ECU
 SG_ VPortB1Average : 24|12@1+ (1,0) [0|4095] "V"  ECU
 SG_ VPortB1Max : 12|12@1+ (1,0) [0|4095] "V"  ECU
 SG_ VPortB1Min : 0|12@1+ (1,0) [0|4095] "V"  ECU

BO_ 2147487878 BL3_Node6PortA1Value: 8 HVHV
 SG_ NMultiplexer M : 56|8@1+ (1,0) [0|255] ""  ECU
 SG_ IqPhAPortA1RMS m3 : 42|12@1+ (0.125,-256) [-256|255.875] "A"  ECU
 SG_ IqPortA1RMS m1 : 36|12@1+ (0.125,-256) [-256|255.875] "A"  ECU
 SG_ NFrequencyPortA1 m2 : 36|16@1+ (0.0125,0) [0|819.1875] "Hz"  ECU
 SG_ IqPhCPortA1RMS m4 : 36|12@1+ (0.125,-256) [-256|255.875] "A"  ECU
 SG_ IdPhAPortA1RMS m3 : 30|12@1+ (0.125,-256) [-256|255.875] "A"  ECU
 SG_ IdPortA1RMS m1 : 24|12@1+ (0.125,-256) [-256|255.875] "A"  ECU
 SG_ VphCPortA1Peak m2 : 24|12@1+ (0.5,0) [0|2047.5] "V"  ECU
 SG_ IdPhCPortA1RMS m4 : 24|12@1+ (0.125,-256) [-256|255.875] "A"  ECU
 SG_ IphCPortA1Peak m3 : 20|10@1+ (0.25,0) [0|255.75] "A"  ECU
 SG_ VqPortA1RMS m1 : 12|12@1+ (0.5,-1024) [-1024|1023.5] "V"  ECU
 SG_ VphBPortA1Peak m2 : 12|12@1+ (0.5,0) [0|2047.5] "V"  ECU
 SG_ IqPhBPortA1RMS m4 : 12|12@1+ (0.125,-256) [-256|255.875] "A"  ECU
 SG_ IphBPortA1Peak m3 : 10|10@1+ (0.25,0) [0|255.75] "A"  ECU
 SG_ VdPortA1RMS m1 : 0|12@1+ (0.5,-1024) [-1024|1023.5] "V"  ECU
 SG_ VphAPortA1Peak m2 : 0|12@1+ (0.5,0) [0|2047.5] "V"  ECU
 SG_ IphAPortA1Peak m3 : 0|10@1+ (0.25,0) [0|255.75] "A"  ECU
 SG_ IdPhBPortA1RMS m4 : 0|12@1+ (0.125,-256) [-256|255.875] "A"  ECU

BO_ 2147487942 BL3_Node6PortA2Value: 8 HVHV
 SG_ NMultiplexer M : 56|8@1+ (1,0) [0|255] ""  ECU
 SG_ NPortA2OverloadCount m0 : 48|8@1+ (1,0) [0|255] ""  ECU
 SG_ IPortA2Average m0 : 36|12@1+ (0.25,-500) [-500|523.75] "A"  ECU
 SG_ VPortA2Average m0 : 24|12@1+ (1,0) [0|4095] "V"  ECU
 SG_ VPortA2Max m0 : 12|12@1+ (1,0) [0|4095] "V"  ECU
 SG_ VPortA2Min m0 : 0|12@1+ (1,0) [0|4095] "V"  ECU

BO_ 2147489478 BL3_Node6ConfigAndSettingsValue: 4 HVHV
 SG_ NParameterValue : 16|16@1+ (1,0) [0|0] ""  ECU
 SG_ NParameterIndex : 4|12@1+ (1,0) [0|0] ""  ECU
 SG_ NReadZoneSelect : 0|4@1+ (1,0) [0|0] ""  ECU

CM_ "The CAN baudrate can be set by the user according to the following choices: 125Kbps, 250Kbps, 500Kbps and 1Mbps.
The default value of the CAN bus speed is 500Kbps.";
CM_ BU_ Brightloop_Can_Loader "Brightloop Can Loader";
CM_ BU_ ECU "Client Control Unit";
CM_ BU_ HVHV "HVHV Unit";
CM_ BO_ 2147487747 "Overal HVHV Status & Diagnostic";
CM_ SG_ 2147487747 BPath1AcModeActivated "Indicates that the Power Path 1 is working in AC mode";
CM_ SG_ 2147487747 BPath1AcUfpError "Power path 1 underfrequency fault";
CM_ SG_ 2147487747 BPath1AcOfpError "Power path 1 overfrequency fault";
CM_ SG_ 2147487747 NPath1AcFunctionMode "Power path 1 AC Function mode select";
CM_ SG_ 2147487747 BPath1FlgCapaError "Indicates a flying capa voltage error on power path 1";
CM_ SG_ 2147487747 BPath2FlgCapaError "Indicates a flying capa voltage error on power path 2";
CM_ SG_ 2147487747 BPath1ErrVAuxCell "Indicates a driver auxiliary voltage error on power path 1";
CM_ SG_ 2147487747 BPath2ErrVAuxCell "Indicates a driver auxiliary voltage error on power path 2";
CM_ SG_ 2147487747 IPath1Unbalance "Unbalanced current between cells on power path 1";
CM_ SG_ 2147487747 IPath2Unbalance "Unbalanced current between cells on power path 2";
CM_ SG_ 2147487747 BPath1RcpWarning "Warns the user of a potential reverse current problem";
CM_ SG_ 2147487747 BPath2RcpWarning "Warns the user of a potential reverse current problem";
CM_ SG_ 2147487747 BPath1OcpError "Power path 1 overcurrent fault";
CM_ SG_ 2147487747 BPath2OcpError "Power path 2 overcurrent fault";
CM_ SG_ 2147487747 BPath1OtpError "Power path 1 overtemperature fault";
CM_ SG_ 2147487747 BPath2OtpError "Power path 2 overtemperature fault";
CM_ SG_ 2147487747 BPath1SideBUvpError "Power path 1 side B undervoltage fault";
CM_ SG_ 2147487747 BPath2SideBUvpError "Power path 2 side B undervoltage fault";
CM_ SG_ 2147487747 BPath1SideAUvpError "Power path 1 side A undervoltage fault";
CM_ SG_ 2147487747 BPath2SideAUvpError "Power path 2 side A undervoltage fault";
CM_ SG_ 2147487747 BPath1SideBOvpError "Power path 1 side B overvoltage fault";
CM_ SG_ 2147487747 BPath2SideBOvpError "Power path 2 side B overvoltage fault";
CM_ SG_ 2147487747 BPath1SideAOvpError "Power path 1 side A overvoltage fault";
CM_ SG_ 2147487747 BPath2SideAOvpError "Power path 2 side A overvoltage fault";
CM_ SG_ 2147487747 BPath1Requested "Indicates that the power path 1 start command has been received";
CM_ SG_ 2147487747 BPath2Requested "Indicates that the power path 2 start command has been received";
CM_ SG_ 2147487747 NPath1CurrentSideSelected "Point of current limitation of Power path 1";
CM_ SG_ 2147487747 NPath2CurrentSideSelected "Point of current limitation of Power path 2";
CM_ SG_ 2147487747 NPath1VoltageSideSelected "Point of voltage regulation of Power path 1";
CM_ SG_ 2147487747 NPath2VoltageSideSelected "Point of voltage regulation of Power path 2";
CM_ SG_ 2147487747 NPath1State "Indicates the power path 1 status";
CM_ SG_ 2147487747 NPath2State "Indicates the power path 2 status";
CM_ SG_ 2147487747 NMultiplexer "Multiplexer ID";
CM_ SG_ 2147487747 BXcpError "Indicates a power switches command?s integrity fault";
CM_ SG_ 2147487747 NCellHwErrorFlags "Indicates HW errors triggered on CELL";
CM_ SG_ 2147487747 BSyncInputSignal "Indicates if a correct synchronization signal is detected on the input synchronization pin";
CM_ SG_ 2147487747 BSyncRequested "Indicates the synchronization command has been received";
CM_ SG_ 2147487747 BInternalTemperatureError "Indicates an overtemperature error on the internal temperature";
CM_ SG_ 2147487747 BConfigSettingsError "Indicates that the Config and/or Settings data is corrupted";
CM_ SG_ 2147487747 BAuxSupplyError "Indicates a fault on one of the auxiliary power supplies";
CM_ SG_ 2147487747 BCanTimeoutError "Indicates an error on the CAN bus";
CM_ SG_ 2147487747 BAuxIsoEnabled "Indicates that isolated auxiliary supplies are activated";
CM_ SG_ 2147487747 BSafetyDischargeEnabled "Indicates the safety discharge is activated";
CM_ SG_ 2147487747 BFaultSignal "Indicates the signal Fault status";
CM_ SG_ 2147487747 BEnableSignal "Indicates the external hardware ENABLE status";
CM_ SG_ 2147487747 BSafetyDischargeStatus "Indicates the safety discharge status";
CM_ SG_ 2147487747 BSyncStatus "Indicates the synchronization has been done successfully";
CM_ SG_ 2147487747 BReadConfigAndSettingsRequested "Indicates that the Read config and settings command has been received";
CM_ SG_ 2147487747 BSwResetModuleRequested "Indicates that the Software reset command has been received";
CM_ SG_ 2147487747 BSafetyDischargeRequested "Indicates that the safety discharge command has been received";
CM_ SG_ 2147487747 NModuleState "Indicates the overall module status";
CM_ BO_ 2147489411 "Response message giving the present values of the setpoints ";
CM_ SG_ 2147489411 IqPath1AcLimitLo "Power path 1 AC Iq lower limitation";
CM_ SG_ 2147489411 IqPath1AcLimitHi "Power path 1 AC Iq upper limitation";
CM_ SG_ 2147489411 PPath2LimitLo "Power path 2 power lower limitation";
CM_ SG_ 2147489411 IqPath1AcSetpoint "Power path 1 AC Iq setpoint";
CM_ SG_ 2147489411 IdPath1AcLimitLo "Power path 1 AC Id lower limitation";
CM_ SG_ 2147489411 IdPath1AcSetpoint "Power path 1 AC Id setpoint";
CM_ SG_ 2147489411 IdPath1AcLimitHi "Power path 1 AC Id upper limitation";
CM_ SG_ 2147489411 PPath2LimitHi "Power path 2 power upper limitation";
CM_ SG_ 2147489411 NMultiplexer "Multiplexer ID:  the power path's number of the setpoints";
CM_ BO_ 2147489347 "Response message giving the present values of the setpoints ";
CM_ SG_ 2147489347 NPath1AcFunctionMode "Power path 1 AC Function mode select";
CM_ SG_ 2147489347 NPath2CurrentSideSelected "Point of current limitation of Power path 2";
CM_ SG_ 2147489347 NPath2VoltageSideSelected "Point of voltage regulation of Power path 2";
CM_ SG_ 2147489347 NPath1AcFrequencySetpoint "Power path 1 AC frequency setpoint";
CM_ SG_ 2147489347 IPath2LimitLo "Power path 2 current lower limitation";
CM_ SG_ 2147489347 VqPath1AcSetpoint "Power path 1 AC Vq setpoint";
CM_ SG_ 2147489347 VdPath1AcSetpoint "Power path 1 AC Vd setpoint";
CM_ SG_ 2147489347 IPath2LimitHi "Power path 2 current upper limitation";
CM_ SG_ 2147489347 VDcPath1AcSetpoint "Power path 1 AC Vdc setpoint";
CM_ SG_ 2147489347 VPath2Setpoint "Power path 2 voltage setpoint";
CM_ SG_ 2147489347 NMultiplexer "Multiplexer ID:  the power path's number of the setpoints";
CM_ BO_ 2147488771 "Values of port B1";
CM_ SG_ 2147488771 NPortB1OverloadCount "Counter indicating the number of times an overload is detected on port B1";
CM_ SG_ 2147488771 IPortB1Average "Average value of the port B1 current";
CM_ SG_ 2147488771 VPortB1Average "Average value of the port B1 voltage";
CM_ SG_ 2147488771 VPortB1Max "Maximum value of the  port B1 voltage seen since the last message sent";
CM_ SG_ 2147488771 VPortB1Min "Minimum value of the port B1 voltage seen since the last message sent";
CM_ BO_ 2147487875 "Values of port A1 ";
CM_ SG_ 2147487875 NMultiplexer "Multiplexer ID";
CM_ SG_ 2147487875 IqPhAPortA1RMS "RMS value of the Iq on phase A";
CM_ SG_ 2147487875 IqPortA1RMS "RMS value of the Iq on Port";
CM_ SG_ 2147487875 NFrequencyPortA1 "Frequency of the AC network";
CM_ SG_ 2147487875 IqPhCPortA1RMS "RMS value of the Iq on phase C";
CM_ SG_ 2147487875 IdPhAPortA1RMS "RMS value of the Id on phase A";
CM_ SG_ 2147487875 IdPortA1RMS "RMS value of the Id on Port";
CM_ SG_ 2147487875 VphCPortA1Peak "Peak value of the voltage on phase C";
CM_ SG_ 2147487875 IdPhCPortA1RMS "RMS value of the Id on phase C";
CM_ SG_ 2147487875 IphCPortA1Peak "Peak value of the current on phase C";
CM_ SG_ 2147487875 VqPortA1RMS "RMS value of the Vq";
CM_ SG_ 2147487875 VphBPortA1Peak "Peak value of the voltage on phase B";
CM_ SG_ 2147487875 IqPhBPortA1RMS "RMS value of the Iq on phase B";
CM_ SG_ 2147487875 IphBPortA1Peak "Peak value of the current on phase B";
CM_ SG_ 2147487875 VdPortA1RMS "RMS value of the Vd";
CM_ SG_ 2147487875 VphAPortA1Peak "Peak value of the voltage on phase A";
CM_ SG_ 2147487875 IphAPortA1Peak "Peak value of the current on phase A";
CM_ SG_ 2147487875 IdPhBPortA1RMS "RMS value of the Id on phase B";
CM_ BO_ 2147487939 "Values of port A2 ";
CM_ SG_ 2147487939 NMultiplexer "Multiplexer ID";
CM_ SG_ 2147487939 NPortA2OverloadCount "Counter indicating the number of times an overload is detected on port A2";
CM_ SG_ 2147487939 IPortA2Average "Average value of the port A2 current";
CM_ SG_ 2147487939 VPortA2Average "Average value of the port A2 voltage";
CM_ SG_ 2147487939 VPortA2Max "Maximum value of the  port A2 voltage seen since the last message sent";
CM_ SG_ 2147487939 VPortA2Min "Minimum value of the port A2 voltage seen since the last message sent";
CM_ BO_ 2147488387 "Values of internal parameters on PowerPath1";
CM_ SG_ 2147488387 VPath1FlgCapaLvl2Max "Maximum value of the flying capa level 2 voltage of the power path 1 seen since the last message sent";
CM_ SG_ 2147488387 VPath1FlgCapaLvl2Min "Minimum value of the flying capa level 2 voltage of the power path 1 seen since the last message sent";
CM_ SG_ 2147488387 VPath1FlgCapaLvl1Max "Maximum value of the flying capa level 1 voltage of the power path 1 seen since the last message sent";
CM_ SG_ 2147488387 VPath1FlgCapaLvl1Min "Minimum value of the flying capa level 1 voltage of the power path 1 seen since the last message sent";
CM_ BO_ 2147488451 "Values of internal parameters on PowerPath2";
CM_ SG_ 2147488451 VPath2FlgCapaLvl2Max "Maximum value of the flying capa level 2 voltage of the power path 2 seen since the last message sent";
CM_ SG_ 2147488451 VPath2FlgCapaLvl2Min "Minimum value of the flying capa level 2 voltage of the power path 2 seen since the last message sent";
CM_ SG_ 2147488451 VPath2FlgCapaLvl1Max "Maximum value of the flying capa level 1 voltage of the power path 2 seen since the last message sent";
CM_ SG_ 2147488451 VPath2FlgCapaLvl1Min "Minimum value of the flying capa level 1 voltage of the power path 2 seen since the last message sent";
CM_ BO_ 2147487811 "Global values";
CM_ SG_ 2147487811 NCellOtpErrorFlags "Indicates overtemperature protection of cells";
CM_ SG_ 2147487811 TCell3N2 "Temperature number 2 of cell 3";
CM_ SG_ 2147487811 VAuxCell4N2 "Auxiliary voltage number 2 of cell 4";
CM_ SG_ 2147487811 TCell3N1 "Temperature number 1 of cell 3";
CM_ SG_ 2147487811 TInternal "Global product temperature";
CM_ SG_ 2147487811 NBootloaderId "Version number of the bootloader program";
CM_ SG_ 2147487811 NApplicationId "Version number of the application program";
CM_ SG_ 2147487811 VAuxCell3N2 "Auxiliary voltage number 2 of cell 3";
CM_ SG_ 2147487811 NSyncNodeCount "Number of node on the network";
CM_ SG_ 2147487811 NSyncNodeRank "Rank of the node on the network";
CM_ SG_ 2147487811 NReleaseMode "Reserved";
CM_ SG_ 2147487811 TCell2N2 "Temperature number 2 of cell 2";
CM_ SG_ 2147487811 NCellVAuxErrorFlags "Indicates Auxiliary voltage error on cells";
CM_ SG_ 2147487811 VAuxCell4N1 "Auxiliary voltage number 1 of cell 4";
CM_ SG_ 2147487811 VAuxCell2N2 "Auxiliary voltage number 2 of cell 2";
CM_ SG_ 2147487811 VAuxCell4N3 "Auxiliary voltage number 3 of cell 4";
CM_ SG_ 2147487811 TCell4N3 "Temperature number 3 of cell 4";
CM_ SG_ 2147487811 VAux3Measured "Auxiliary voltage used for offset of current and voltage measurement";
CM_ SG_ 2147487811 TCell2N1 "Temperature number 1 of cell 2";
CM_ SG_ 2147487811 NConfigCrc "CRC of the CONFIG";
CM_ SG_ 2147487811 NSettingsCrc "CRC of the SETTINGS";
CM_ SG_ 2147487811 NSerial "Product Serial Number";
CM_ SG_ 2147487811 VAuxCell3N1 "Auxiliary voltage number 1 of cell 3";
CM_ SG_ 2147487811 VAuxCell1N2 "Auxiliary voltage number 2 of cell 1";
CM_ SG_ 2147487811 VAuxCell3N3 "Auxiliary voltage number 3 of cell 3";
CM_ SG_ 2147487811 TCell3N3 "Temperature number 3 of cell 3";
CM_ SG_ 2147487811 VAux2Measured "Auxiliary voltage 3V3 value";
CM_ SG_ 2147487811 TCell1N2 "Temperature number 2 of cell 1";
CM_ SG_ 2147487811 TCell4N2 "Temperature number 2 of cell 4";
CM_ SG_ 2147487811 NCellXcpErrorFlags "Indicates Xcp error on cells";
CM_ SG_ 2147487811 VAuxCell2N1 "Auxiliary voltage number 1 of cell 2";
CM_ SG_ 2147487811 VAuxCell2N3 "Auxiliary voltage number 3 of cell 2";
CM_ SG_ 2147487811 TCell2N3 "Temperature number 3 of cell 2";
CM_ SG_ 2147487811 VAux1Measured "Auxiliary voltage LV value";
CM_ SG_ 2147487811 TCell1N1 "Temperature number 1 of cell 1";
CM_ SG_ 2147487811 TCell4N1 "Temperature number 1 of cell 4";
CM_ SG_ 2147487811 NConfigVersion "Version number of the CONFIG";
CM_ SG_ 2147487811 NSettingsVersion "Version number of the SETTINGS";
CM_ SG_ 2147487811 NChecksum "Checksum of the application program";
CM_ SG_ 2147487811 NCellSwOcpErrorFlags "Indicates Sw overcurrent protection ";
CM_ SG_ 2147487811 VAuxCell1N1 "Auxiliary voltage number 1 of cell 1";
CM_ SG_ 2147487811 VAuxCell1N3 "Auxiliary voltage number 3 of cell 1";
CM_ SG_ 2147487811 TCell1N3 "Temperature number 3 of cell 1";
CM_ SG_ 2147487811 NMultiplexer "Multiplexer ID";
CM_ BO_ 2147489475 "Value of all parameters of the configuration and settings";
CM_ SG_ 2147489475 NParameterValue "Value of the 16bits word";
CM_ SG_ 2147489475 NParameterIndex "Index at which the word is read in the selected zone";
CM_ SG_ 2147489475 NReadZoneSelect "Zone in which to read the parameters";
CM_ BO_ 2147489410 "Response message giving the present values of the setpoints ";
CM_ SG_ 2147489410 PPath2LimitLo "Power path 2 power lower limitation";
CM_ SG_ 2147489410 PPath2LimitHi "Power path 2 power upper limitation";
CM_ SG_ 2147489410 NMultiplexer "Multiplexer ID:  the power path's number of the setpoints";
CM_ BO_ 2147489346 "Response message giving the present values of the setpoints ";
CM_ SG_ 2147489346 NPath2CurrentSideSelected "Point of current limitation of Power path 2";
CM_ SG_ 2147489346 NPath2VoltageSideSelected "Point of voltage regulation of Power path 2";
CM_ SG_ 2147489346 IPath2LimitLo "Power path 2 current lower limitation";
CM_ SG_ 2147489346 IPath2LimitHi "Power path 2 current upper limitation";
CM_ SG_ 2147489346 VPath2Setpoint "Power path 2 voltage setpoint";
CM_ SG_ 2147489346 NMultiplexer "Multiplexer ID:  the power path's number of the setpoints";
CM_ BO_ 2147488450 "Values of internal parameters on PowerPath2";
CM_ SG_ 2147488450 VPath2FlgCapaLvl2Max "Maximum value of the flying capa level 2 voltage of the power path 2 seen since the last message sent";
CM_ SG_ 2147488450 VPath2FlgCapaLvl2Min "Minimum value of the flying capa level 2 voltage of the power path 2 seen since the last message sent";
CM_ SG_ 2147488450 VPath2FlgCapaLvl1Max "Maximum value of the flying capa level 1 voltage of the power path 2 seen since the last message sent";
CM_ SG_ 2147488450 VPath2FlgCapaLvl1Min "Minimum value of the flying capa level 1 voltage of the power path 2 seen since the last message sent";
CM_ BO_ 2147488770 "Values of port B1";
CM_ SG_ 2147488770 NPortB1OverloadCount "Counter indicating the number of times an overload is detected on port B1";
CM_ SG_ 2147488770 IPortB1Average "Average value of the port B1 current";
CM_ SG_ 2147488770 VPortB1Average "Average value of the port B1 voltage";
CM_ SG_ 2147488770 VPortB1Max "Maximum value of the  port B1 voltage seen since the last message sent";
CM_ SG_ 2147488770 VPortB1Min "Minimum value of the port B1 voltage seen since the last message sent";
CM_ BO_ 2147488127 "Command message to read the setpoints";
CM_ SG_ 2147488127 NCrc "CRC of the message. The module accepts this message only when a correct CRC is verified";
CM_ SG_ 2147488127 NPathSelect "The number of the power path to apply the setpoint read command to";
CM_ SG_ 2147488127 BPathAcCurrentSetpointSelect "Indicate whether the current setpoint should be returned instead of the current limit for the AC power path. Set this parameter to 1 to ensure the current setpoint is returned in the HVHV_Setpoints2Value message";
CM_ SG_ 2147488127 BReadSetpointRequest "Setpoint read command";
CM_ BO_ 2147488063 "Control of error acknowledgement commands";
CM_ SG_ 2147488063 NCrc "CRC of the message. The module accepts this message only when a correct CRC is verified";
CM_ SG_ 2147488063 NModuleSelect "Module ID on which to apply error acknowledge : 1-32 for module 1 to module 32, 63 for all modules";
CM_ SG_ 2147488063 BAckErrorsModuleRequest "Acknowledgement of all errors on module ";
CM_ SG_ 2147488063 BAckErrorsPath2Request "Acknowledgement of errors on power path 2";
CM_ SG_ 2147488063 BAckErrorsPath1Request "Acknowledgement of errors on power path 1";
CM_ BO_ 2147487999 "Control  of Setpoints 2 DC";
CM_ SG_ 2147487999 NCrc "CRC of the message. The module accepts this message only when a correct CRC is verified";
CM_ SG_ 2147487999 NModuleSelect "Module ID on which to apply the setpoints";
CM_ SG_ 2147487999 BL1_PPath2LimitLo "Power path 2 power lower limitation";
CM_ SG_ 2147487999 BL2_PPath2LimitLo "Power path 2 power lower limitation";
CM_ SG_ 2147487999 BL3_PPath2LimitLo "Power path 2 power lower limitation";
CM_ SG_ 2147487999 BL4_PPath2LimitLo "Power path 2 power lower limitation";
CM_ SG_ 2147487999 BL1_PPath2LimitHi "Power path 2 power upper limitation";
CM_ SG_ 2147487999 BL2_PPath2LimitHi "Power path 2 power upper limitation";
CM_ SG_ 2147487999 BL3_PPath2LimitHi "Power path 2 power upper limitation";
CM_ SG_ 2147487999 BL4_PPath2LimitHi "Power path 2 power upper limitation";
CM_ SG_ 2147487999 BL1_NMultiplexer "Multiplexer ID: allows to select the power path to apply the setpoints";
CM_ SG_ 2147487999 BL2_NMultiplexer "Multiplexer ID: allows to select the power path to apply the setpoints";
CM_ SG_ 2147487999 BL3_NMultiplexer "Multiplexer ID: allows to select the power path to apply the setpoints";
CM_ SG_ 2147487999 BL4_NMultiplexer "Multiplexer ID: allows to select the power path to apply the setpoints";
CM_ BO_ 2147488191 "Control  of Setpoints 1 AC";
CM_ SG_ 2147488191 NCrc "CRC of the message. The module accepts this message only when a correct CRC is verified";
CM_ SG_ 2147488191 NModuleSelect "Module ID on which to apply the setpoints";
CM_ SG_ 2147488191 BL1_NPath1AcFrequencySetpoint "Power path 1 AC frequency setpoint";
CM_ SG_ 2147488191 BL2_NPath1AcFrequencySetpoint "Power path 1 AC frequency setpoint";
CM_ SG_ 2147488191 BL3_NPath1AcFrequencySetpoint "Power path 1 AC frequency setpoint";
CM_ SG_ 2147488191 BL4_NPath1AcFrequencySetpoint "Power path 1 AC frequency setpoint";
CM_ SG_ 2147488191 BL1_VqPath1AcSetpoint "Power path 1 AC Vq setpoint";
CM_ SG_ 2147488191 BL2_VqPath1AcSetpoint "Power path 1 AC Vq setpoint";
CM_ SG_ 2147488191 BL3_VqPath1AcSetpoint "Power path 1 AC Vq setpoint";
CM_ SG_ 2147488191 BL4_VqPath1AcSetpoint "Power path 1 AC Vq setpoint";
CM_ SG_ 2147488191 BL1_VdPath1AcSetpoint "Power path 1 AC Vd setpoint";
CM_ SG_ 2147488191 BL2_VdPath1AcSetpoint "Power path 1 AC Vd setpoint";
CM_ SG_ 2147488191 BL3_VdPath1AcSetpoint "Power path 1 AC Vd setpoint";
CM_ SG_ 2147488191 BL4_VdPath1AcSetpoint "Power path 1 AC Vd setpoint";
CM_ SG_ 2147488191 BL1_VDcPath1AcSetpoint "Power path 1 AC Vdc setpoint";
CM_ SG_ 2147488191 BL2_VDcPath1AcSetpoint "Power path 1 AC Vdc setpoint";
CM_ SG_ 2147488191 BL3_VDcPath1AcSetpoint "Power path 1 AC Vdc setpoint";
CM_ SG_ 2147488191 BL4_VDcPath1AcSetpoint "Power path 1 AC Vdc setpoint";
CM_ SG_ 2147488191 BL1_NMultiplexer "Multiplexer ID: allows to select the power path to apply the setpoints";
CM_ SG_ 2147488191 BL2_NMultiplexer "Multiplexer ID: allows to select the power path to apply the setpoints";
CM_ SG_ 2147488191 BL3_NMultiplexer "Multiplexer ID: allows to select the power path to apply the setpoints";
CM_ SG_ 2147488191 BL4_NMultiplexer "Multiplexer ID: allows to select the power path to apply the setpoints";
CM_ BO_ 2147488255 "Control  of Setpoints 2 AC";
CM_ SG_ 2147488255 NCrc "CRC of the message. The module accepts this message only when a correct CRC is verified";
CM_ SG_ 2147488255 NModuleSelect "Module ID on which to apply the setpoints";
CM_ SG_ 2147488255 BL1_IqPath1AcLimitLo "Power path 1 AC Iq lower limitation";
CM_ SG_ 2147488255 BL2_IqPath1AcLimitLo "Power path 1 AC Iq lower limitation";
CM_ SG_ 2147488255 BL3_IqPath1AcLimitLo "Power path 1 AC Iq lower limitation";
CM_ SG_ 2147488255 BL4_IqPath1AcLimitLo "Power path 1 AC Iq lower limitation";
CM_ SG_ 2147488255 BL1_IqPath1AcLimitHi "Power path 1 AC Iq upper limitation";
CM_ SG_ 2147488255 BL2_IqPath1AcLimitHi "Power path 1 AC Iq upper limitation";
CM_ SG_ 2147488255 BL3_IqPath1AcLimitHi "Power path 1 AC Iq upper limitation";
CM_ SG_ 2147488255 BL4_IqPath1AcLimitHi "Power path 1 AC Iq upper limitation";
CM_ SG_ 2147488255 BL1_IqPath1AcSetpoint "Power path 1 AC Iq setpoint";
CM_ SG_ 2147488255 BL1_IdPath1AcLimitLo "Power path 1 AC Id lower limitation";
CM_ SG_ 2147488255 BL2_IdPath1AcLimitLo "Power path 1 AC Id lower limitation";
CM_ SG_ 2147488255 BL2_IqPath1AcSetpoint "Power path 1 AC Iq setpoint";
CM_ SG_ 2147488255 BL3_IqPath1AcSetpoint "Power path 1 AC Iq setpoint";
CM_ SG_ 2147488255 BL3_IdPath1AcLimitLo "Power path 1 AC Id lower limitation";
CM_ SG_ 2147488255 BL4_IqPath1AcSetpoint "Power path 1 AC Iq setpoint";
CM_ SG_ 2147488255 BL4_IdPath1AcLimitLo "Power path 1 AC Id lower limitation";
CM_ SG_ 2147488255 BL1_IdPath1AcSetpoint "Power path 1 AC Id setpoint";
CM_ SG_ 2147488255 BL1_IdPath1AcLimitHi "Power path 1 AC Id upper limitation";
CM_ SG_ 2147488255 BL2_IdPath1AcLimitHi "Power path 1 AC Id upper limitation";
CM_ SG_ 2147488255 BL2_IdPath1AcSetpoint "Power path 1 AC Id setpoint";
CM_ SG_ 2147488255 BL3_IdPath1AcSetpoint "Power path 1 AC Id setpoint";
CM_ SG_ 2147488255 BL3_IdPath1AcLimitHi "Power path 1 AC Id upper limitation";
CM_ SG_ 2147488255 BL4_IdPath1AcSetpoint "Power path 1 AC Id setpoint";
CM_ SG_ 2147488255 BL4_IdPath1AcLimitHi "Power path 1 AC Id upper limitation";
CM_ SG_ 2147488255 BL1_NPath1AcFunctionMode "Power path 1 AC Function mode select";
CM_ SG_ 2147488255 BL2_NPath1AcFunctionMode "Power path 1 AC Function mode select";
CM_ SG_ 2147488255 BL3_NPath1AcFunctionMode "Power path 1 AC Function mode select";
CM_ SG_ 2147488255 BL4_NPath1AcFunctionMode "Power path 1 AC Function mode select";
CM_ SG_ 2147488255 BL1_NMultiplexer "Multiplexer ID: allows to select the power path to apply the setpoints";
CM_ SG_ 2147488255 BL2_NMultiplexer "Multiplexer ID: allows to select the power path to apply the setpoints";
CM_ SG_ 2147488255 BL3_NMultiplexer "Multiplexer ID: allows to select the power path to apply the setpoints";
CM_ SG_ 2147488255 BL4_NMultiplexer "Multiplexer ID: allows to select the power path to apply the setpoints";
CM_ BO_ 2147487938 "Values of port A2 ";
CM_ SG_ 2147487938 NMultiplexer "Multiplexer ID";
CM_ SG_ 2147487938 NPortA2OverloadCount "Counter indicating the number of times an overload is detected on port A2";
CM_ SG_ 2147487938 IPortA2Average "Average value of the port A2 current";
CM_ SG_ 2147487938 VPortA2Average "Average value of the port A2 voltage";
CM_ SG_ 2147487938 VPortA2Max "Maximum value of the  port A2 voltage seen since the last message sent";
CM_ SG_ 2147487938 VPortA2Min "Minimum value of the port A2 voltage seen since the last message sent";
CM_ BO_ 2147489474 "Value of all parameters of the configuration and settings";
CM_ SG_ 2147489474 NParameterValue "Value of the 16bits word";
CM_ SG_ 2147489474 NParameterIndex "Index at which the word is read in the selected zone";
CM_ SG_ 2147489474 NReadZoneSelect "Zone in which to read the parameters";
CM_ BO_ 2147487810 "Global values";
CM_ SG_ 2147487810 NCellOtpErrorFlags "Indicates overtemperature protection of cells";
CM_ SG_ 2147487810 TCell3N2 "Temperature number 2 of cell 3";
CM_ SG_ 2147487810 VAuxCell4N2 "Auxiliary voltage number 2 of cell 4";
CM_ SG_ 2147487810 TCell3N1 "Temperature number 1 of cell 3";
CM_ SG_ 2147487810 TInternal "Global product temperature";
CM_ SG_ 2147487810 NBootloaderId "Version number of the bootloader program";
CM_ SG_ 2147487810 NApplicationId "Version number of the application program";
CM_ SG_ 2147487810 VAuxCell3N2 "Auxiliary voltage number 2 of cell 3";
CM_ SG_ 2147487810 NSyncNodeCount "Number of node on the network";
CM_ SG_ 2147487810 NSyncNodeRank "Rank of the node on the network";
CM_ SG_ 2147487810 NReleaseMode "Reserved";
CM_ SG_ 2147487810 TCell2N2 "Temperature number 2 of cell 2";
CM_ SG_ 2147487810 NCellVAuxErrorFlags "Indicates Auxiliary voltage error on cells";
CM_ SG_ 2147487810 VAuxCell4N1 "Auxiliary voltage number 1 of cell 4";
CM_ SG_ 2147487810 VAuxCell2N2 "Auxiliary voltage number 2 of cell 2";
CM_ SG_ 2147487810 VAuxCell4N3 "Auxiliary voltage number 3 of cell 4";
CM_ SG_ 2147487810 TCell4N3 "Temperature number 3 of cell 4";
CM_ SG_ 2147487810 VAux3Measured "Auxiliary voltage used for offset of current and voltage measurement";
CM_ SG_ 2147487810 TCell2N1 "Temperature number 1 of cell 2";
CM_ SG_ 2147487810 NConfigCrc "CRC of the CONFIG";
CM_ SG_ 2147487810 NSettingsCrc "CRC of the SETTINGS";
CM_ SG_ 2147487810 NSerial "Product Serial Number";
CM_ SG_ 2147487810 VAuxCell3N1 "Auxiliary voltage number 1 of cell 3";
CM_ SG_ 2147487810 VAuxCell1N2 "Auxiliary voltage number 2 of cell 1";
CM_ SG_ 2147487810 VAuxCell3N3 "Auxiliary voltage number 3 of cell 3";
CM_ SG_ 2147487810 TCell3N3 "Temperature number 3 of cell 3";
CM_ SG_ 2147487810 VAux2Measured "Auxiliary voltage 3V3 value";
CM_ SG_ 2147487810 TCell1N2 "Temperature number 2 of cell 1";
CM_ SG_ 2147487810 TCell4N2 "Temperature number 2 of cell 4";
CM_ SG_ 2147487810 NCellXcpErrorFlags "Indicates Xcp error on cells";
CM_ SG_ 2147487810 VAuxCell2N1 "Auxiliary voltage number 1 of cell 2";
CM_ SG_ 2147487810 VAuxCell2N3 "Auxiliary voltage number 3 of cell 2";
CM_ SG_ 2147487810 TCell2N3 "Temperature number 3 of cell 2";
CM_ SG_ 2147487810 VAux1Measured "Auxiliary voltage LV value";
CM_ SG_ 2147487810 TCell1N1 "Temperature number 1 of cell 1";
CM_ SG_ 2147487810 TCell4N1 "Temperature number 1 of cell 4";
CM_ SG_ 2147487810 NConfigVersion "Version number of the CONFIG";
CM_ SG_ 2147487810 NSettingsVersion "Version number of the SETTINGS";
CM_ SG_ 2147487810 NChecksum "Checksum of the application program";
CM_ SG_ 2147487810 NCellSwOcpErrorFlags "Indicates Sw overcurrent protection ";
CM_ SG_ 2147487810 VAuxCell1N1 "Auxiliary voltage number 1 of cell 1";
CM_ SG_ 2147487810 VAuxCell1N3 "Auxiliary voltage number 3 of cell 1";
CM_ SG_ 2147487810 TCell1N3 "Temperature number 3 of cell 1";
CM_ SG_ 2147487810 NMultiplexer "Multiplexer ID";
CM_ BO_ 2147487746 "Overal HVHV Status & Diagnostic";
CM_ SG_ 2147487746 BPath2FlgCapaError "Indicates a flying capa voltage error on power path 2";
CM_ SG_ 2147487746 BPath2ErrVAuxCell "Indicates a driver auxiliary voltage error on power path 2";
CM_ SG_ 2147487746 IPath2Unbalance "Unbalanced current between cells on power path 2";
CM_ SG_ 2147487746 BPath2RcpWarning "Warns the user of a potential reverse current problem";
CM_ SG_ 2147487746 BPath2OcpError "Power path 2 overcurrent fault";
CM_ SG_ 2147487746 BPath2OtpError "Power path 2 overtemperature fault";
CM_ SG_ 2147487746 BPath2SideBUvpError "Power path 2 side B undervoltage fault";
CM_ SG_ 2147487746 BPath2SideAUvpError "Power path 2 side A undervoltage fault";
CM_ SG_ 2147487746 BPath2SideBOvpError "Power path 2 side B overvoltage fault";
CM_ SG_ 2147487746 BPath2SideAOvpError "Power path 2 side A overvoltage fault";
CM_ SG_ 2147487746 BPath2Requested "Indicates that the power path 2 start command has been received";
CM_ SG_ 2147487746 NPath2CurrentSideSelected "Point of current limitation of Power path 2";
CM_ SG_ 2147487746 NPath2VoltageSideSelected "Point of voltage regulation of Power path 2";
CM_ SG_ 2147487746 NPath2State "Indicates the power path 2 status";
CM_ SG_ 2147487746 NMultiplexer "Multiplexer ID";
CM_ SG_ 2147487746 BXcpError "Indicates a power switches command?s integrity fault";
CM_ SG_ 2147487746 NCellHwErrorFlags "Indicates HW errors triggered on CELL";
CM_ SG_ 2147487746 BSyncInputSignal "Indicates if a correct synchronization signal is detected on the input synchronization pin";
CM_ SG_ 2147487746 BSyncRequested "Indicates the synchronization command has been received";
CM_ SG_ 2147487746 BInternalTemperatureError "Indicates an overtemperature error on the internal temperature";
CM_ SG_ 2147487746 BConfigSettingsError "Indicates that the Config and/or Settings data is corrupted";
CM_ SG_ 2147487746 BAuxSupplyError "Indicates a fault on one of the auxiliary power supplies";
CM_ SG_ 2147487746 BCanTimeoutError "Indicates an error on the CAN bus";
CM_ SG_ 2147487746 BAuxIsoEnabled "Indicates that isolated auxiliary supplies are activated";
CM_ SG_ 2147487746 BSafetyDischargeEnabled "Indicates the safety discharge is activated";
CM_ SG_ 2147487746 BFaultSignal "Indicates the signal Fault status";
CM_ SG_ 2147487746 BEnableSignal "Indicates the external hardware ENABLE status";
CM_ SG_ 2147487746 BSafetyDischargeStatus "Indicates the safety discharge status";
CM_ SG_ 2147487746 BSyncStatus "Indicates the synchronization has been done successfully";
CM_ SG_ 2147487746 BReadConfigAndSettingsRequested "Indicates that the Read config and settings command has been received";
CM_ SG_ 2147487746 BSwResetModuleRequested "Indicates that the Software reset command has been received";
CM_ SG_ 2147487746 BSafetyDischargeRequested "Indicates that the safety discharge command has been received";
CM_ SG_ 2147487746 NModuleState "Indicates the overall module status";
CM_ BO_ 2147487935 "Control  of Setpoints 1 DC";
CM_ SG_ 2147487935 NCrc "CRC of the message. The module accepts this message only when a correct CRC is verified";
CM_ SG_ 2147487935 NModuleSelect "Module ID on which to apply the setpoints";
CM_ SG_ 2147487935 BL1_NPath2CurrentSideSelect "Point of current limitation of Power path 2";
CM_ SG_ 2147487935 BL2_NPath2CurrentSideSelect "Point of current limitation of Power path 2";
CM_ SG_ 2147487935 BL3_NPath2CurrentSideSelect "Point of current limitation of Power path 2";
CM_ SG_ 2147487935 BL4_NPath2CurrentSideSelect "Point of current limitation of Power path 2";
CM_ SG_ 2147487935 BL1_NPath2VoltageSideSelect "Point of voltage regulation of Power path 2";
CM_ SG_ 2147487935 BL2_NPath2VoltageSideSelect "Point of voltage regulation of Power path 2";
CM_ SG_ 2147487935 BL3_NPath2VoltageSideSelect "Point of voltage regulation of Power path 2";
CM_ SG_ 2147487935 BL4_NPath2VoltageSideSelect "Point of voltage regulation of Power path 2";
CM_ SG_ 2147487935 BL1_IPath2LimitLo "Power path 2 current lower limitation";
CM_ SG_ 2147487935 BL2_IPath2LimitLo "Power path 2 current lower limitation";
CM_ SG_ 2147487935 BL3_IPath2LimitLo "Power path 2 current lower limitation";
CM_ SG_ 2147487935 BL4_IPath2LimitLo "Power path 2 current lower limitation";
CM_ SG_ 2147487935 BL1_IPath2LimitHi "Power path 2 current upper limitation";
CM_ SG_ 2147487935 BL2_IPath2LimitHi "Power path 2 current upper limitation";
CM_ SG_ 2147487935 BL3_IPath2LimitHi "Power path 2 current upper limitation";
CM_ SG_ 2147487935 BL4_IPath2LimitHi "Power path 2 current upper limitation";
CM_ SG_ 2147487935 BL1_VPath2Setpoint "Power path 2 voltage setpoint";
CM_ SG_ 2147487935 BL2_VPath2Setpoint "Power path 2 voltage setpoint";
CM_ SG_ 2147487935 BL3_VPath2Setpoint "Power path 2 voltage setpoint";
CM_ SG_ 2147487935 BL4_VPath2Setpoint "Power path 2 voltage setpoint";
CM_ SG_ 2147487935 BL1_NMultiplexer "Multiplexer ID: allows to select the power path to apply the setpoints";
CM_ SG_ 2147487935 BL2_NMultiplexer "Multiplexer ID: allows to select the power path to apply the setpoints";
CM_ SG_ 2147487935 BL3_NMultiplexer "Multiplexer ID: allows to select the power path to apply the setpoints";
CM_ SG_ 2147487935 BL4_NMultiplexer "Multiplexer ID: allows to select the power path to apply the setpoints";
CM_ BO_ 2147487807 "Control message from the ECU";
CM_ SG_ 2147487807 NCrc "CRC of the message. The module accepts this message only when a correct CRC is verified";
CM_ SG_ 2147487807 NModuleSelect "Module ID on which to apply software reset command and/or read config and settings command and/or discharge active command : 1-32 for module 1 to module 32, 63 for all modules";
CM_ SG_ 2147487807 BSyncRequest "Activate synchronization command";
CM_ SG_ 2147487807 BReadConfigAndSettingsRequest "Read config and settings of module command";
CM_ SG_ 2147487807 BSwResetModuleRequest "Software reset module command";
CM_ SG_ 2147487807 BSafetyDischargeRequest "Module safety discharge command";
CM_ SG_ 2147487807 BPath2Request "Start/Stop power path 2 command";
CM_ SG_ 2147487807 BPath1Request "Start/Stop power path 1 command";
CM_ SG_ 2147487807 NCounter "Counter for reception of CAN messages. If it does not change for more than CanTimeOut parameter then an error is detected (CAN error)";
CM_ BO_ 2147487749 "Overal HVHV Status & Diagnostic";
CM_ SG_ 2147487749 BPath1AcModeActivated "Indicates that the Power Path 1 is working in AC mode";
CM_ SG_ 2147487749 BPath1AcUfpError "Power path 1 underfrequency fault";
CM_ SG_ 2147487749 BPath1AcOfpError "Power path 1 overfrequency fault";
CM_ SG_ 2147487749 NPath1AcFunctionMode "Power path 1 AC Function mode select";
CM_ SG_ 2147487749 BPath2FlgCapaError "Indicates a flying capa voltage error on power path 2";
CM_ SG_ 2147487749 BPath1FlgCapaError "Indicates a flying capa voltage error on power path 1";
CM_ SG_ 2147487749 BPath2ErrVAuxCell "Indicates a driver auxiliary voltage error on power path 2";
CM_ SG_ 2147487749 BPath1ErrVAuxCell "Indicates a driver auxiliary voltage error on power path 1";
CM_ SG_ 2147487749 IPath2Unbalance "Unbalanced current between cells on power path 2";
CM_ SG_ 2147487749 IPath1Unbalance "Unbalanced current between cells on power path 1";
CM_ SG_ 2147487749 BPath2RcpWarning "Warns the user of a potential reverse current problem";
CM_ SG_ 2147487749 BPath1RcpWarning "Warns the user of a potential reverse current problem";
CM_ SG_ 2147487749 BPath2OcpError "Power path 2 overcurrent fault";
CM_ SG_ 2147487749 BPath1OcpError "Power path 1 overcurrent fault";
CM_ SG_ 2147487749 BPath2OtpError "Power path 2 overtemperature fault";
CM_ SG_ 2147487749 BPath1OtpError "Power path 1 overtemperature fault";
CM_ SG_ 2147487749 BPath2SideBUvpError "Power path 2 side B undervoltage fault";
CM_ SG_ 2147487749 BPath1SideBUvpError "Power path 1 side B undervoltage fault";
CM_ SG_ 2147487749 BPath2SideAUvpError "Power path 2 side A undervoltage fault";
CM_ SG_ 2147487749 BPath1SideAUvpError "Power path 1 side A undervoltage fault";
CM_ SG_ 2147487749 BPath2SideBOvpError "Power path 2 side B overvoltage fault";
CM_ SG_ 2147487749 BPath1SideBOvpError "Power path 1 side B overvoltage fault";
CM_ SG_ 2147487749 BPath2SideAOvpError "Power path 2 side A overvoltage fault";
CM_ SG_ 2147487749 BPath1SideAOvpError "Power path 1 side A overvoltage fault";
CM_ SG_ 2147487749 BPath2Requested "Indicates that the power path 2 start command has been received";
CM_ SG_ 2147487749 BPath1Requested "Indicates that the power path 1 start command has been received";
CM_ SG_ 2147487749 NPath2CurrentSideSelected "Point of current limitation of Power path 2";
CM_ SG_ 2147487749 NPath1CurrentSideSelected "Point of current limitation of Power path 1";
CM_ SG_ 2147487749 NPath2VoltageSideSelected "Point of voltage regulation of Power path 2";
CM_ SG_ 2147487749 NPath1VoltageSideSelected "Point of voltage regulation of Power path 1";
CM_ SG_ 2147487749 NPath2State "Indicates the power path 2 status";
CM_ SG_ 2147487749 NPath1State "Indicates the power path 1 status";
CM_ SG_ 2147487749 NMultiplexer "Multiplexer ID";
CM_ SG_ 2147487749 BXcpError "Indicates a power switches command?s integrity fault";
CM_ SG_ 2147487749 NCellHwErrorFlags "Indicates HW errors triggered on CELL";
CM_ SG_ 2147487749 BSyncInputSignal "Indicates if a correct synchronization signal is detected on the input synchronization pin";
CM_ SG_ 2147487749 BSyncRequested "Indicates the synchronization command has been received";
CM_ SG_ 2147487749 BInternalTemperatureError "Indicates an overtemperature error on the internal temperature";
CM_ SG_ 2147487749 BConfigSettingsError "Indicates that the Config and/or Settings data is corrupted";
CM_ SG_ 2147487749 BAuxSupplyError "Indicates a fault on one of the auxiliary power supplies";
CM_ SG_ 2147487749 BCanTimeoutError "Indicates an error on the CAN bus";
CM_ SG_ 2147487749 BAuxIsoEnabled "Indicates that isolated auxiliary supplies are activated";
CM_ SG_ 2147487749 BSafetyDischargeEnabled "Indicates the safety discharge is activated";
CM_ SG_ 2147487749 BFaultSignal "Indicates the signal Fault status";
CM_ SG_ 2147487749 BEnableSignal "Indicates the external hardware ENABLE status";
CM_ SG_ 2147487749 BSafetyDischargeStatus "Indicates the safety discharge status";
CM_ SG_ 2147487749 BSyncStatus "Indicates the synchronization has been done successfully";
CM_ SG_ 2147487749 BReadConfigAndSettingsRequested "Indicates that the Read config and settings command has been received";
CM_ SG_ 2147487749 BSwResetModuleRequested "Indicates that the Software reset command has been received";
CM_ SG_ 2147487749 BSafetyDischargeRequested "Indicates that the safety discharge command has been received";
CM_ SG_ 2147487749 NModuleState "Indicates the overall module status";
CM_ BO_ 2147489413 "Response message giving the present values of the setpoints ";
CM_ SG_ 2147489413 IqPath1AcLimitLo "Power path 1 AC Iq lower limitation";
CM_ SG_ 2147489413 IqPath1AcLimitHi "Power path 1 AC Iq upper limitation";
CM_ SG_ 2147489413 PPath2LimitLo "Power path 2 power lower limitation";
CM_ SG_ 2147489413 IdPath1AcLimitLo "Power path 1 AC Id lower limitation";
CM_ SG_ 2147489413 IqPath1AcSetpoint "Power path 1 AC Iq setpoint";
CM_ SG_ 2147489413 PPath2LimitHi "Power path 2 power upper limitation";
CM_ SG_ 2147489413 IdPath1AcLimitHi "Power path 1 AC Id upper limitation";
CM_ SG_ 2147489413 IdPath1AcSetpoint "Power path 1 AC Id setpoint";
CM_ SG_ 2147489413 NMultiplexer "Multiplexer ID:  the power path's number of the setpoints";
CM_ BO_ 2147489349 "Response message giving the present values of the setpoints ";
CM_ SG_ 2147489349 NPath1AcFunctionMode "Power path 1 AC Function mode select";
CM_ SG_ 2147489349 NPath2CurrentSideSelected "Point of current limitation of Power path 2";
CM_ SG_ 2147489349 NPath2VoltageSideSelected "Point of voltage regulation of Power path 2";
CM_ SG_ 2147489349 NPath1AcFrequencySetpoint "Power path 1 AC frequency setpoint";
CM_ SG_ 2147489349 IPath2LimitLo "Power path 2 current lower limitation";
CM_ SG_ 2147489349 VqPath1AcSetpoint "Power path 1 AC Vq setpoint";
CM_ SG_ 2147489349 IPath2LimitHi "Power path 2 current upper limitation";
CM_ SG_ 2147489349 VdPath1AcSetpoint "Power path 1 AC Vd setpoint";
CM_ SG_ 2147489349 VPath2Setpoint "Power path 2 voltage setpoint";
CM_ SG_ 2147489349 VDcPath1AcSetpoint "Power path 1 AC Vdc setpoint";
CM_ SG_ 2147489349 NMultiplexer "Multiplexer ID:  the power path's number of the setpoints";
CM_ BO_ 2147488773 "Values of port B1";
CM_ SG_ 2147488773 NPortB1OverloadCount "Counter indicating the number of times an overload is detected on port B1";
CM_ SG_ 2147488773 IPortB1Average "Average value of the port B1 current";
CM_ SG_ 2147488773 VPortB1Average "Average value of the port B1 voltage";
CM_ SG_ 2147488773 VPortB1Max "Maximum value of the  port B1 voltage seen since the last message sent";
CM_ SG_ 2147488773 VPortB1Min "Minimum value of the port B1 voltage seen since the last message sent";
CM_ BO_ 2147487877 "Values of port A1 ";
CM_ SG_ 2147487877 NMultiplexer "Multiplexer ID";
CM_ SG_ 2147487877 IqPhAPortA1RMS "RMS value of the Iq on phase A";
CM_ SG_ 2147487877 IqPhCPortA1RMS "RMS value of the Iq on phase C";
CM_ SG_ 2147487877 NFrequencyPortA1 "Frequency of the AC network";
CM_ SG_ 2147487877 IqPortA1RMS "RMS value of the Iq on Port";
CM_ SG_ 2147487877 IdPhAPortA1RMS "RMS value of the Id on phase A";
CM_ SG_ 2147487877 IdPhCPortA1RMS "RMS value of the Id on phase C";
CM_ SG_ 2147487877 VphCPortA1Peak "Peak value of the voltage on phase C";
CM_ SG_ 2147487877 IdPortA1RMS "RMS value of the Id on Port";
CM_ SG_ 2147487877 IphCPortA1Peak "Peak value of the current on phase C";
CM_ SG_ 2147487877 IqPhBPortA1RMS "RMS value of the Iq on phase B";
CM_ SG_ 2147487877 VphBPortA1Peak "Peak value of the voltage on phase B";
CM_ SG_ 2147487877 VqPortA1RMS "RMS value of the Vq";
CM_ SG_ 2147487877 IphBPortA1Peak "Peak value of the current on phase B";
CM_ SG_ 2147487877 IdPhBPortA1RMS "RMS value of the Id on phase B";
CM_ SG_ 2147487877 IphAPortA1Peak "Peak value of the current on phase A";
CM_ SG_ 2147487877 VphAPortA1Peak "Peak value of the voltage on phase A";
CM_ SG_ 2147487877 VdPortA1RMS "RMS value of the Vd";
CM_ BO_ 2147487941 "Values of port A2 ";
CM_ SG_ 2147487941 NMultiplexer "Multiplexer ID";
CM_ SG_ 2147487941 NPortA2OverloadCount "Counter indicating the number of times an overload is detected on port A2";
CM_ SG_ 2147487941 IPortA2Average "Average value of the port A2 current";
CM_ SG_ 2147487941 VPortA2Average "Average value of the port A2 voltage";
CM_ SG_ 2147487941 VPortA2Max "Maximum value of the  port A2 voltage seen since the last message sent";
CM_ SG_ 2147487941 VPortA2Min "Minimum value of the port A2 voltage seen since the last message sent";
CM_ BO_ 2147488389 "Values of internal parameters on PowerPath1";
CM_ SG_ 2147488389 VPath1FlgCapaLvl2Max "Maximum value of the flying capa level 2 voltage of the power path 1 seen since the last message sent";
CM_ SG_ 2147488389 VPath1FlgCapaLvl2Min "Minimum value of the flying capa level 2 voltage of the power path 1 seen since the last message sent";
CM_ SG_ 2147488389 VPath1FlgCapaLvl1Max "Maximum value of the flying capa level 1 voltage of the power path 1 seen since the last message sent";
CM_ SG_ 2147488389 VPath1FlgCapaLvl1Min "Minimum value of the flying capa level 1 voltage of the power path 1 seen since the last message sent";
CM_ BO_ 2147488453 "Values of internal parameters on PowerPath2";
CM_ SG_ 2147488453 VPath2FlgCapaLvl2Max "Maximum value of the flying capa level 2 voltage of the power path 2 seen since the last message sent";
CM_ SG_ 2147488453 VPath2FlgCapaLvl2Min "Minimum value of the flying capa level 2 voltage of the power path 2 seen since the last message sent";
CM_ SG_ 2147488453 VPath2FlgCapaLvl1Max "Maximum value of the flying capa level 1 voltage of the power path 2 seen since the last message sent";
CM_ SG_ 2147488453 VPath2FlgCapaLvl1Min "Minimum value of the flying capa level 1 voltage of the power path 2 seen since the last message sent";
CM_ BO_ 2147487813 "Global values";
CM_ SG_ 2147487813 VAuxCell4N2 "Auxiliary voltage number 2 of cell 4";
CM_ SG_ 2147487813 TCell3N2 "Temperature number 2 of cell 3";
CM_ SG_ 2147487813 NCellOtpErrorFlags "Indicates overtemperature protection of cells";
CM_ SG_ 2147487813 VAuxCell3N2 "Auxiliary voltage number 2 of cell 3";
CM_ SG_ 2147487813 NApplicationId "Version number of the application program";
CM_ SG_ 2147487813 NBootloaderId "Version number of the bootloader program";
CM_ SG_ 2147487813 TInternal "Global product temperature";
CM_ SG_ 2147487813 TCell3N1 "Temperature number 1 of cell 3";
CM_ SG_ 2147487813 NSyncNodeCount "Number of node on the network";
CM_ SG_ 2147487813 NSyncNodeRank "Rank of the node on the network";
CM_ SG_ 2147487813 TCell4N3 "Temperature number 3 of cell 4";
CM_ SG_ 2147487813 VAuxCell4N3 "Auxiliary voltage number 3 of cell 4";
CM_ SG_ 2147487813 VAuxCell2N2 "Auxiliary voltage number 2 of cell 2";
CM_ SG_ 2147487813 VAuxCell4N1 "Auxiliary voltage number 1 of cell 4";
CM_ SG_ 2147487813 NCellVAuxErrorFlags "Indicates Auxiliary voltage error on cells";
CM_ SG_ 2147487813 TCell2N2 "Temperature number 2 of cell 2";
CM_ SG_ 2147487813 NReleaseMode "Reserved";
CM_ SG_ 2147487813 TCell3N3 "Temperature number 3 of cell 3";
CM_ SG_ 2147487813 VAuxCell3N3 "Auxiliary voltage number 3 of cell 3";
CM_ SG_ 2147487813 VAuxCell1N2 "Auxiliary voltage number 2 of cell 1";
CM_ SG_ 2147487813 VAuxCell3N1 "Auxiliary voltage number 1 of cell 3";
CM_ SG_ 2147487813 NSerial "Product Serial Number";
CM_ SG_ 2147487813 NSettingsCrc "CRC of the SETTINGS";
CM_ SG_ 2147487813 NConfigCrc "CRC of the CONFIG";
CM_ SG_ 2147487813 TCell2N1 "Temperature number 1 of cell 2";
CM_ SG_ 2147487813 VAux3Measured "Auxiliary voltage used for offset of current and voltage measurement";
CM_ SG_ 2147487813 TCell2N3 "Temperature number 3 of cell 2";
CM_ SG_ 2147487813 VAuxCell2N3 "Auxiliary voltage number 3 of cell 2";
CM_ SG_ 2147487813 VAuxCell2N1 "Auxiliary voltage number 1 of cell 2";
CM_ SG_ 2147487813 NCellXcpErrorFlags "Indicates Xcp error on cells";
CM_ SG_ 2147487813 TCell4N2 "Temperature number 2 of cell 4";
CM_ SG_ 2147487813 TCell1N2 "Temperature number 2 of cell 1";
CM_ SG_ 2147487813 VAux2Measured "Auxiliary voltage 3V3 value";
CM_ SG_ 2147487813 TCell1N3 "Temperature number 3 of cell 1";
CM_ SG_ 2147487813 VAuxCell1N3 "Auxiliary voltage number 3 of cell 1";
CM_ SG_ 2147487813 VAuxCell1N1 "Auxiliary voltage number 1 of cell 1";
CM_ SG_ 2147487813 NCellSwOcpErrorFlags "Indicates Sw overcurrent protection ";
CM_ SG_ 2147487813 NChecksum "Checksum of the application program";
CM_ SG_ 2147487813 NSettingsVersion "Version number of the SETTINGS";
CM_ SG_ 2147487813 NConfigVersion "Version number of the CONFIG";
CM_ SG_ 2147487813 TCell4N1 "Temperature number 1 of cell 4";
CM_ SG_ 2147487813 TCell1N1 "Temperature number 1 of cell 1";
CM_ SG_ 2147487813 VAux1Measured "Auxiliary voltage LV value";
CM_ SG_ 2147487813 NMultiplexer "Multiplexer ID";
CM_ BO_ 2147489477 "Value of all parameters of the configuration and settings";
CM_ SG_ 2147489477 NParameterValue "Value of the 16bits word";
CM_ SG_ 2147489477 NParameterIndex "Index at which the word is read in the selected zone";
CM_ SG_ 2147489477 NReadZoneSelect "Zone in which to read the parameters";
CM_ BO_ 2147489412 "Response message giving the present values of the setpoints ";
CM_ SG_ 2147489412 IqPath1AcLimitLo "Power path 1 AC Iq lower limitation";
CM_ SG_ 2147489412 IqPath1AcLimitHi "Power path 1 AC Iq upper limitation";
CM_ SG_ 2147489412 PPath2LimitLo "Power path 2 power lower limitation";
CM_ SG_ 2147489412 IdPath1AcLimitLo "Power path 1 AC Id lower limitation";
CM_ SG_ 2147489412 IqPath1AcSetpoint "Power path 1 AC Iq setpoint";
CM_ SG_ 2147489412 PPath2LimitHi "Power path 2 power upper limitation";
CM_ SG_ 2147489412 IdPath1AcLimitHi "Power path 1 AC Id upper limitation";
CM_ SG_ 2147489412 IdPath1AcSetpoint "Power path 1 AC Id setpoint";
CM_ SG_ 2147489412 NMultiplexer "Multiplexer ID:  the power path's number of the setpoints";
CM_ BO_ 2147489348 "Response message giving the present values of the setpoints ";
CM_ SG_ 2147489348 NPath1AcFunctionMode "Power path 1 AC Function mode select";
CM_ SG_ 2147489348 NPath2CurrentSideSelected "Point of current limitation of Power path 2";
CM_ SG_ 2147489348 NPath2VoltageSideSelected "Point of voltage regulation of Power path 2";
CM_ SG_ 2147489348 NPath1AcFrequencySetpoint "Power path 1 AC frequency setpoint";
CM_ SG_ 2147489348 IPath2LimitLo "Power path 2 current lower limitation";
CM_ SG_ 2147489348 VqPath1AcSetpoint "Power path 1 AC Vq setpoint";
CM_ SG_ 2147489348 IPath2LimitHi "Power path 2 current upper limitation";
CM_ SG_ 2147489348 VdPath1AcSetpoint "Power path 1 AC Vd setpoint";
CM_ SG_ 2147489348 VPath2Setpoint "Power path 2 voltage setpoint";
CM_ SG_ 2147489348 VDcPath1AcSetpoint "Power path 1 AC Vdc setpoint";
CM_ SG_ 2147489348 NMultiplexer "Multiplexer ID:  the power path's number of the setpoints";
CM_ BO_ 2147488388 "Values of internal parameters on PowerPath1";
CM_ SG_ 2147488388 VPath1FlgCapaLvl2Max "Maximum value of the flying capa level 2 voltage of the power path 1 seen since the last message sent";
CM_ SG_ 2147488388 VPath1FlgCapaLvl2Min "Minimum value of the flying capa level 2 voltage of the power path 1 seen since the last message sent";
CM_ SG_ 2147488388 VPath1FlgCapaLvl1Max "Maximum value of the flying capa level 1 voltage of the power path 1 seen since the last message sent";
CM_ SG_ 2147488388 VPath1FlgCapaLvl1Min "Minimum value of the flying capa level 1 voltage of the power path 1 seen since the last message sent";
CM_ BO_ 2147488452 "Values of internal parameters on PowerPath2";
CM_ SG_ 2147488452 VPath2FlgCapaLvl2Max "Maximum value of the flying capa level 2 voltage of the power path 2 seen since the last message sent";
CM_ SG_ 2147488452 VPath2FlgCapaLvl2Min "Minimum value of the flying capa level 2 voltage of the power path 2 seen since the last message sent";
CM_ SG_ 2147488452 VPath2FlgCapaLvl1Max "Maximum value of the flying capa level 1 voltage of the power path 2 seen since the last message sent";
CM_ SG_ 2147488452 VPath2FlgCapaLvl1Min "Minimum value of the flying capa level 1 voltage of the power path 2 seen since the last message sent";
CM_ BO_ 2147488772 "Values of port B1";
CM_ SG_ 2147488772 NPortB1OverloadCount "Counter indicating the number of times an overload is detected on port B1";
CM_ SG_ 2147488772 IPortB1Average "Average value of the port B1 current";
CM_ SG_ 2147488772 VPortB1Average "Average value of the port B1 voltage";
CM_ SG_ 2147488772 VPortB1Max "Maximum value of the  port B1 voltage seen since the last message sent";
CM_ SG_ 2147488772 VPortB1Min "Minimum value of the port B1 voltage seen since the last message sent";
CM_ BO_ 2147487876 "Values of port A1 ";
CM_ SG_ 2147487876 NMultiplexer "Multiplexer ID";
CM_ SG_ 2147487876 IqPhAPortA1RMS "RMS value of the Iq on phase A";
CM_ SG_ 2147487876 IqPhCPortA1RMS "RMS value of the Iq on phase C";
CM_ SG_ 2147487876 NFrequencyPortA1 "Frequency of the AC network";
CM_ SG_ 2147487876 IqPortA1RMS "RMS value of the Iq on Port";
CM_ SG_ 2147487876 IdPhAPortA1RMS "RMS value of the Id on phase A";
CM_ SG_ 2147487876 IdPhCPortA1RMS "RMS value of the Id on phase C";
CM_ SG_ 2147487876 VphCPortA1Peak "Peak value of the voltage on phase C";
CM_ SG_ 2147487876 IdPortA1RMS "RMS value of the Id on Port";
CM_ SG_ 2147487876 IphCPortA1Peak "Peak value of the current on phase C";
CM_ SG_ 2147487876 IqPhBPortA1RMS "RMS value of the Iq on phase B";
CM_ SG_ 2147487876 VphBPortA1Peak "Peak value of the voltage on phase B";
CM_ SG_ 2147487876 VqPortA1RMS "RMS value of the Vq";
CM_ SG_ 2147487876 IphBPortA1Peak "Peak value of the current on phase B";
CM_ SG_ 2147487876 IdPhBPortA1RMS "RMS value of the Id on phase B";
CM_ SG_ 2147487876 IphAPortA1Peak "Peak value of the current on phase A";
CM_ SG_ 2147487876 VphAPortA1Peak "Peak value of the voltage on phase A";
CM_ SG_ 2147487876 VdPortA1RMS "RMS value of the Vd";
CM_ BO_ 2147487940 "Values of port A2 ";
CM_ SG_ 2147487940 NMultiplexer "Multiplexer ID";
CM_ SG_ 2147487940 NPortA2OverloadCount "Counter indicating the number of times an overload is detected on port A2";
CM_ SG_ 2147487940 IPortA2Average "Average value of the port A2 current";
CM_ SG_ 2147487940 VPortA2Average "Average value of the port A2 voltage";
CM_ SG_ 2147487940 VPortA2Max "Maximum value of the  port A2 voltage seen since the last message sent";
CM_ SG_ 2147487940 VPortA2Min "Minimum value of the port A2 voltage seen since the last message sent";
CM_ BO_ 2147489476 "Value of all parameters of the configuration and settings";
CM_ SG_ 2147489476 NParameterValue "Value of the 16bits word";
CM_ SG_ 2147489476 NParameterIndex "Index at which the word is read in the selected zone";
CM_ SG_ 2147489476 NReadZoneSelect "Zone in which to read the parameters";
CM_ BO_ 2147487812 "Global values";
CM_ SG_ 2147487812 VAuxCell4N2 "Auxiliary voltage number 2 of cell 4";
CM_ SG_ 2147487812 TCell3N2 "Temperature number 2 of cell 3";
CM_ SG_ 2147487812 NCellOtpErrorFlags "Indicates overtemperature protection of cells";
CM_ SG_ 2147487812 VAuxCell3N2 "Auxiliary voltage number 2 of cell 3";
CM_ SG_ 2147487812 NApplicationId "Version number of the application program";
CM_ SG_ 2147487812 NBootloaderId "Version number of the bootloader program";
CM_ SG_ 2147487812 TInternal "Global product temperature";
CM_ SG_ 2147487812 TCell3N1 "Temperature number 1 of cell 3";
CM_ SG_ 2147487812 NSyncNodeCount "Number of node on the network";
CM_ SG_ 2147487812 NSyncNodeRank "Rank of the node on the network";
CM_ SG_ 2147487812 TCell4N3 "Temperature number 3 of cell 4";
CM_ SG_ 2147487812 VAuxCell4N3 "Auxiliary voltage number 3 of cell 4";
CM_ SG_ 2147487812 VAuxCell2N2 "Auxiliary voltage number 2 of cell 2";
CM_ SG_ 2147487812 VAuxCell4N1 "Auxiliary voltage number 1 of cell 4";
CM_ SG_ 2147487812 NCellVAuxErrorFlags "Indicates Auxiliary voltage error on cells";
CM_ SG_ 2147487812 TCell2N2 "Temperature number 2 of cell 2";
CM_ SG_ 2147487812 NReleaseMode "Reserved";
CM_ SG_ 2147487812 TCell3N3 "Temperature number 3 of cell 3";
CM_ SG_ 2147487812 VAuxCell3N3 "Auxiliary voltage number 3 of cell 3";
CM_ SG_ 2147487812 VAuxCell1N2 "Auxiliary voltage number 2 of cell 1";
CM_ SG_ 2147487812 VAuxCell3N1 "Auxiliary voltage number 1 of cell 3";
CM_ SG_ 2147487812 NSerial "Product Serial Number";
CM_ SG_ 2147487812 NSettingsCrc "CRC of the SETTINGS";
CM_ SG_ 2147487812 NConfigCrc "CRC of the CONFIG";
CM_ SG_ 2147487812 TCell2N1 "Temperature number 1 of cell 2";
CM_ SG_ 2147487812 VAux3Measured "Auxiliary voltage used for offset of current and voltage measurement";
CM_ SG_ 2147487812 TCell2N3 "Temperature number 3 of cell 2";
CM_ SG_ 2147487812 VAuxCell2N3 "Auxiliary voltage number 3 of cell 2";
CM_ SG_ 2147487812 VAuxCell2N1 "Auxiliary voltage number 1 of cell 2";
CM_ SG_ 2147487812 NCellXcpErrorFlags "Indicates Xcp error on cells";
CM_ SG_ 2147487812 TCell4N2 "Temperature number 2 of cell 4";
CM_ SG_ 2147487812 TCell1N2 "Temperature number 2 of cell 1";
CM_ SG_ 2147487812 VAux2Measured "Auxiliary voltage 3V3 value";
CM_ SG_ 2147487812 TCell1N3 "Temperature number 3 of cell 1";
CM_ SG_ 2147487812 VAuxCell1N3 "Auxiliary voltage number 3 of cell 1";
CM_ SG_ 2147487812 VAuxCell1N1 "Auxiliary voltage number 1 of cell 1";
CM_ SG_ 2147487812 NCellSwOcpErrorFlags "Indicates Sw overcurrent protection ";
CM_ SG_ 2147487812 NChecksum "Checksum of the application program";
CM_ SG_ 2147487812 NSettingsVersion "Version number of the SETTINGS";
CM_ SG_ 2147487812 NConfigVersion "Version number of the CONFIG";
CM_ SG_ 2147487812 TCell4N1 "Temperature number 1 of cell 4";
CM_ SG_ 2147487812 TCell1N1 "Temperature number 1 of cell 1";
CM_ SG_ 2147487812 VAux1Measured "Auxiliary voltage LV value";
CM_ SG_ 2147487812 NMultiplexer "Multiplexer ID";
CM_ BO_ 2147487748 "Overal HVHV Status & Diagnostic";
CM_ SG_ 2147487748 BPath1AcModeActivated "Indicates that the Power Path 1 is working in AC mode";
CM_ SG_ 2147487748 BPath1AcUfpError "Power path 1 underfrequency fault";
CM_ SG_ 2147487748 BPath1AcOfpError "Power path 1 overfrequency fault";
CM_ SG_ 2147487748 NPath1AcFunctionMode "Power path 1 AC Function mode select";
CM_ SG_ 2147487748 BPath2FlgCapaError "Indicates a flying capa voltage error on power path 2";
CM_ SG_ 2147487748 BPath1FlgCapaError "Indicates a flying capa voltage error on power path 1";
CM_ SG_ 2147487748 BPath2ErrVAuxCell "Indicates a driver auxiliary voltage error on power path 2";
CM_ SG_ 2147487748 BPath1ErrVAuxCell "Indicates a driver auxiliary voltage error on power path 1";
CM_ SG_ 2147487748 IPath2Unbalance "Unbalanced current between cells on power path 2";
CM_ SG_ 2147487748 IPath1Unbalance "Unbalanced current between cells on power path 1";
CM_ SG_ 2147487748 BPath2RcpWarning "Warns the user of a potential reverse current problem";
CM_ SG_ 2147487748 BPath1RcpWarning "Warns the user of a potential reverse current problem";
CM_ SG_ 2147487748 BPath2OcpError "Power path 2 overcurrent fault";
CM_ SG_ 2147487748 BPath1OcpError "Power path 1 overcurrent fault";
CM_ SG_ 2147487748 BPath2OtpError "Power path 2 overtemperature fault";
CM_ SG_ 2147487748 BPath1OtpError "Power path 1 overtemperature fault";
CM_ SG_ 2147487748 BPath2SideBUvpError "Power path 2 side B undervoltage fault";
CM_ SG_ 2147487748 BPath1SideBUvpError "Power path 1 side B undervoltage fault";
CM_ SG_ 2147487748 BPath2SideAUvpError "Power path 2 side A undervoltage fault";
CM_ SG_ 2147487748 BPath1SideAUvpError "Power path 1 side A undervoltage fault";
CM_ SG_ 2147487748 BPath2SideBOvpError "Power path 2 side B overvoltage fault";
CM_ SG_ 2147487748 BPath1SideBOvpError "Power path 1 side B overvoltage fault";
CM_ SG_ 2147487748 BPath2SideAOvpError "Power path 2 side A overvoltage fault";
CM_ SG_ 2147487748 BPath1SideAOvpError "Power path 1 side A overvoltage fault";
CM_ SG_ 2147487748 BPath2Requested "Indicates that the power path 2 start command has been received";
CM_ SG_ 2147487748 BPath1Requested "Indicates that the power path 1 start command has been received";
CM_ SG_ 2147487748 NPath2CurrentSideSelected "Point of current limitation of Power path 2";
CM_ SG_ 2147487748 NPath1CurrentSideSelected "Point of current limitation of Power path 1";
CM_ SG_ 2147487748 NPath2VoltageSideSelected "Point of voltage regulation of Power path 2";
CM_ SG_ 2147487748 NPath1VoltageSideSelected "Point of voltage regulation of Power path 1";
CM_ SG_ 2147487748 NPath2State "Indicates the power path 2 status";
CM_ SG_ 2147487748 NPath1State "Indicates the power path 1 status";
CM_ SG_ 2147487748 NMultiplexer "Multiplexer ID";
CM_ SG_ 2147487748 BXcpError "Indicates a power switches command?s integrity fault";
CM_ SG_ 2147487748 NCellHwErrorFlags "Indicates HW errors triggered on CELL";
CM_ SG_ 2147487748 BSyncInputSignal "Indicates if a correct synchronization signal is detected on the input synchronization pin";
CM_ SG_ 2147487748 BSyncRequested "Indicates the synchronization command has been received";
CM_ SG_ 2147487748 BInternalTemperatureError "Indicates an overtemperature error on the internal temperature";
CM_ SG_ 2147487748 BConfigSettingsError "Indicates that the Config and/or Settings data is corrupted";
CM_ SG_ 2147487748 BAuxSupplyError "Indicates a fault on one of the auxiliary power supplies";
CM_ SG_ 2147487748 BCanTimeoutError "Indicates an error on the CAN bus";
CM_ SG_ 2147487748 BAuxIsoEnabled "Indicates that isolated auxiliary supplies are activated";
CM_ SG_ 2147487748 BSafetyDischargeEnabled "Indicates the safety discharge is activated";
CM_ SG_ 2147487748 BFaultSignal "Indicates the signal Fault status";
CM_ SG_ 2147487748 BEnableSignal "Indicates the external hardware ENABLE status";
CM_ SG_ 2147487748 BSafetyDischargeStatus "Indicates the safety discharge status";
CM_ SG_ 2147487748 BSyncStatus "Indicates the synchronization has been done successfully";
CM_ SG_ 2147487748 BReadConfigAndSettingsRequested "Indicates that the Read config and settings command has been received";
CM_ SG_ 2147487748 BSwResetModuleRequested "Indicates that the Software reset command has been received";
CM_ SG_ 2147487748 BSafetyDischargeRequested "Indicates that the safety discharge command has been received";
CM_ SG_ 2147487748 NModuleState "Indicates the overall module status";
CM_ BO_ 2147487751 "Overal HVHV Status & Diagnostic";
CM_ SG_ 2147487751 BPath1AcModeActivated "Indicates that the Power Path 1 is working in AC mode";
CM_ SG_ 2147487751 BPath1AcUfpError "Power path 1 underfrequency fault";
CM_ SG_ 2147487751 BPath1AcOfpError "Power path 1 overfrequency fault";
CM_ SG_ 2147487751 NPath1AcFunctionMode "Power path 1 AC Function mode select";
CM_ SG_ 2147487751 BPath1FlgCapaError "Indicates a flying capa voltage error on power path 1";
CM_ SG_ 2147487751 BPath2FlgCapaError "Indicates a flying capa voltage error on power path 2";
CM_ SG_ 2147487751 BPath1ErrVAuxCell "Indicates a driver auxiliary voltage error on power path 1";
CM_ SG_ 2147487751 BPath2ErrVAuxCell "Indicates a driver auxiliary voltage error on power path 2";
CM_ SG_ 2147487751 IPath1Unbalance "Unbalanced current between cells on power path 1";
CM_ SG_ 2147487751 IPath2Unbalance "Unbalanced current between cells on power path 2";
CM_ SG_ 2147487751 BPath1RcpWarning "Warns the user of a potential reverse current problem";
CM_ SG_ 2147487751 BPath2RcpWarning "Warns the user of a potential reverse current problem";
CM_ SG_ 2147487751 BPath1OcpError "Power path 1 overcurrent fault";
CM_ SG_ 2147487751 BPath2OcpError "Power path 2 overcurrent fault";
CM_ SG_ 2147487751 BPath1OtpError "Power path 1 overtemperature fault";
CM_ SG_ 2147487751 BPath2OtpError "Power path 2 overtemperature fault";
CM_ SG_ 2147487751 BPath1SideBUvpError "Power path 1 side B undervoltage fault";
CM_ SG_ 2147487751 BPath2SideBUvpError "Power path 2 side B undervoltage fault";
CM_ SG_ 2147487751 BPath1SideAUvpError "Power path 1 side A undervoltage fault";
CM_ SG_ 2147487751 BPath2SideAUvpError "Power path 2 side A undervoltage fault";
CM_ SG_ 2147487751 BPath1SideBOvpError "Power path 1 side B overvoltage fault";
CM_ SG_ 2147487751 BPath2SideBOvpError "Power path 2 side B overvoltage fault";
CM_ SG_ 2147487751 BPath1SideAOvpError "Power path 1 side A overvoltage fault";
CM_ SG_ 2147487751 BPath2SideAOvpError "Power path 2 side A overvoltage fault";
CM_ SG_ 2147487751 BPath1Requested "Indicates that the power path 1 start command has been received";
CM_ SG_ 2147487751 BPath2Requested "Indicates that the power path 2 start command has been received";
CM_ SG_ 2147487751 NPath1CurrentSideSelected "Point of current limitation of Power path 1";
CM_ SG_ 2147487751 NPath2CurrentSideSelected "Point of current limitation of Power path 2";
CM_ SG_ 2147487751 NPath1VoltageSideSelected "Point of voltage regulation of Power path 1";
CM_ SG_ 2147487751 NPath2VoltageSideSelected "Point of voltage regulation of Power path 2";
CM_ SG_ 2147487751 NPath1State "Indicates the power path 1 status";
CM_ SG_ 2147487751 NPath2State "Indicates the power path 2 status";
CM_ SG_ 2147487751 NMultiplexer "Multiplexer ID";
CM_ SG_ 2147487751 BXcpError "Indicates a power switches command?s integrity fault";
CM_ SG_ 2147487751 NCellHwErrorFlags "Indicates HW errors triggered on CELL";
CM_ SG_ 2147487751 BSyncInputSignal "Indicates if a correct synchronization signal is detected on the input synchronization pin";
CM_ SG_ 2147487751 BSyncRequested "Indicates the synchronization command has been received";
CM_ SG_ 2147487751 BInternalTemperatureError "Indicates an overtemperature error on the internal temperature";
CM_ SG_ 2147487751 BConfigSettingsError "Indicates that the Config and/or Settings data is corrupted";
CM_ SG_ 2147487751 BAuxSupplyError "Indicates a fault on one of the auxiliary power supplies";
CM_ SG_ 2147487751 BCanTimeoutError "Indicates an error on the CAN bus";
CM_ SG_ 2147487751 BAuxIsoEnabled "Indicates that isolated auxiliary supplies are activated";
CM_ SG_ 2147487751 BSafetyDischargeEnabled "Indicates the safety discharge is activated";
CM_ SG_ 2147487751 BFaultSignal "Indicates the signal Fault status";
CM_ SG_ 2147487751 BEnableSignal "Indicates the external hardware ENABLE status";
CM_ SG_ 2147487751 BSafetyDischargeStatus "Indicates the safety discharge status";
CM_ SG_ 2147487751 BSyncStatus "Indicates the synchronization has been done successfully";
CM_ SG_ 2147487751 BReadConfigAndSettingsRequested "Indicates that the Read config and settings command has been received";
CM_ SG_ 2147487751 BSwResetModuleRequested "Indicates that the Software reset command has been received";
CM_ SG_ 2147487751 BSafetyDischargeRequested "Indicates that the safety discharge command has been received";
CM_ SG_ 2147487751 NModuleState "Indicates the overall module status";
CM_ BO_ 2147489415 "Response message giving the present values of the setpoints ";
CM_ SG_ 2147489415 IqPath1AcLimitLo "Power path 1 AC Iq lower limitation";
CM_ SG_ 2147489415 IqPath1AcLimitHi "Power path 1 AC Iq upper limitation";
CM_ SG_ 2147489415 PPath2LimitLo "Power path 2 power lower limitation";
CM_ SG_ 2147489415 IqPath1AcSetpoint "Power path 1 AC Iq setpoint";
CM_ SG_ 2147489415 IdPath1AcLimitLo "Power path 1 AC Id lower limitation";
CM_ SG_ 2147489415 IdPath1AcSetpoint "Power path 1 AC Id setpoint";
CM_ SG_ 2147489415 IdPath1AcLimitHi "Power path 1 AC Id upper limitation";
CM_ SG_ 2147489415 PPath2LimitHi "Power path 2 power upper limitation";
CM_ SG_ 2147489415 NMultiplexer "Multiplexer ID:  the power path's number of the setpoints";
CM_ BO_ 2147489351 "Response message giving the present values of the setpoints ";
CM_ SG_ 2147489351 NPath1AcFunctionMode "Power path 1 AC Function mode select";
CM_ SG_ 2147489351 NPath2CurrentSideSelected "Point of current limitation of Power path 2";
CM_ SG_ 2147489351 NPath2VoltageSideSelected "Point of voltage regulation of Power path 2";
CM_ SG_ 2147489351 NPath1AcFrequencySetpoint "Power path 1 AC frequency setpoint";
CM_ SG_ 2147489351 IPath2LimitLo "Power path 2 current lower limitation";
CM_ SG_ 2147489351 VqPath1AcSetpoint "Power path 1 AC Vq setpoint";
CM_ SG_ 2147489351 VdPath1AcSetpoint "Power path 1 AC Vd setpoint";
CM_ SG_ 2147489351 IPath2LimitHi "Power path 2 current upper limitation";
CM_ SG_ 2147489351 VDcPath1AcSetpoint "Power path 1 AC Vdc setpoint";
CM_ SG_ 2147489351 VPath2Setpoint "Power path 2 voltage setpoint";
CM_ SG_ 2147489351 NMultiplexer "Multiplexer ID:  the power path's number of the setpoints";
CM_ BO_ 2147488775 "Values of port B1";
CM_ SG_ 2147488775 NPortB1OverloadCount "Counter indicating the number of times an overload is detected on port B1";
CM_ SG_ 2147488775 IPortB1Average "Average value of the port B1 current";
CM_ SG_ 2147488775 VPortB1Average "Average value of the port B1 voltage";
CM_ SG_ 2147488775 VPortB1Max "Maximum value of the  port B1 voltage seen since the last message sent";
CM_ SG_ 2147488775 VPortB1Min "Minimum value of the port B1 voltage seen since the last message sent";
CM_ BO_ 2147487879 "Values of port A1 ";
CM_ SG_ 2147487879 NMultiplexer "Multiplexer ID";
CM_ SG_ 2147487879 IqPhAPortA1RMS "RMS value of the Iq on phase A";
CM_ SG_ 2147487879 IqPortA1RMS "RMS value of the Iq on Port";
CM_ SG_ 2147487879 NFrequencyPortA1 "Frequency of the AC network";
CM_ SG_ 2147487879 IqPhCPortA1RMS "RMS value of the Iq on phase C";
CM_ SG_ 2147487879 IdPhAPortA1RMS "RMS value of the Id on phase A";
CM_ SG_ 2147487879 IdPortA1RMS "RMS value of the Id on Port";
CM_ SG_ 2147487879 VphCPortA1Peak "Peak value of the voltage on phase C";
CM_ SG_ 2147487879 IdPhCPortA1RMS "RMS value of the Id on phase C";
CM_ SG_ 2147487879 IphCPortA1Peak "Peak value of the current on phase C";
CM_ SG_ 2147487879 VqPortA1RMS "RMS value of the Vq";
CM_ SG_ 2147487879 VphBPortA1Peak "Peak value of the voltage on phase B";
CM_ SG_ 2147487879 IqPhBPortA1RMS "RMS value of the Iq on phase B";
CM_ SG_ 2147487879 IphBPortA1Peak "Peak value of the current on phase B";
CM_ SG_ 2147487879 VdPortA1RMS "RMS value of the Vd";
CM_ SG_ 2147487879 VphAPortA1Peak "Peak value of the voltage on phase A";
CM_ SG_ 2147487879 IphAPortA1Peak "Peak value of the current on phase A";
CM_ SG_ 2147487879 IdPhBPortA1RMS "RMS value of the Id on phase B";
CM_ BO_ 2147487943 "Values of port A2 ";
CM_ SG_ 2147487943 NMultiplexer "Multiplexer ID";
CM_ SG_ 2147487943 NPortA2OverloadCount "Counter indicating the number of times an overload is detected on port A2";
CM_ SG_ 2147487943 IPortA2Average "Average value of the port A2 current";
CM_ SG_ 2147487943 VPortA2Average "Average value of the port A2 voltage";
CM_ SG_ 2147487943 VPortA2Max "Maximum value of the  port A2 voltage seen since the last message sent";
CM_ SG_ 2147487943 VPortA2Min "Minimum value of the port A2 voltage seen since the last message sent";
CM_ BO_ 2147488391 "Values of internal parameters on PowerPath1";
CM_ SG_ 2147488391 VPath1FlgCapaLvl2Max "Maximum value of the flying capa level 2 voltage of the power path 1 seen since the last message sent";
CM_ SG_ 2147488391 VPath1FlgCapaLvl2Min "Minimum value of the flying capa level 2 voltage of the power path 1 seen since the last message sent";
CM_ SG_ 2147488391 VPath1FlgCapaLvl1Max "Maximum value of the flying capa level 1 voltage of the power path 1 seen since the last message sent";
CM_ SG_ 2147488391 VPath1FlgCapaLvl1Min "Minimum value of the flying capa level 1 voltage of the power path 1 seen since the last message sent";
CM_ BO_ 2147488455 "Values of internal parameters on PowerPath2";
CM_ SG_ 2147488455 VPath2FlgCapaLvl2Max "Maximum value of the flying capa level 2 voltage of the power path 2 seen since the last message sent";
CM_ SG_ 2147488455 VPath2FlgCapaLvl2Min "Minimum value of the flying capa level 2 voltage of the power path 2 seen since the last message sent";
CM_ SG_ 2147488455 VPath2FlgCapaLvl1Max "Maximum value of the flying capa level 1 voltage of the power path 2 seen since the last message sent";
CM_ SG_ 2147488455 VPath2FlgCapaLvl1Min "Minimum value of the flying capa level 1 voltage of the power path 2 seen since the last message sent";
CM_ BO_ 2147487815 "Global values";
CM_ SG_ 2147487815 NCellOtpErrorFlags "Indicates overtemperature protection of cells";
CM_ SG_ 2147487815 TCell3N2 "Temperature number 2 of cell 3";
CM_ SG_ 2147487815 VAuxCell4N2 "Auxiliary voltage number 2 of cell 4";
CM_ SG_ 2147487815 TCell3N1 "Temperature number 1 of cell 3";
CM_ SG_ 2147487815 TInternal "Global product temperature";
CM_ SG_ 2147487815 NBootloaderId "Version number of the bootloader program";
CM_ SG_ 2147487815 NApplicationId "Version number of the application program";
CM_ SG_ 2147487815 VAuxCell3N2 "Auxiliary voltage number 2 of cell 3";
CM_ SG_ 2147487815 NSyncNodeCount "Number of node on the network";
CM_ SG_ 2147487815 NSyncNodeRank "Rank of the node on the network";
CM_ SG_ 2147487815 NReleaseMode "Reserved";
CM_ SG_ 2147487815 TCell2N2 "Temperature number 2 of cell 2";
CM_ SG_ 2147487815 NCellVAuxErrorFlags "Indicates Auxiliary voltage error on cells";
CM_ SG_ 2147487815 VAuxCell4N1 "Auxiliary voltage number 1 of cell 4";
CM_ SG_ 2147487815 VAuxCell2N2 "Auxiliary voltage number 2 of cell 2";
CM_ SG_ 2147487815 VAuxCell4N3 "Auxiliary voltage number 3 of cell 4";
CM_ SG_ 2147487815 TCell4N3 "Temperature number 3 of cell 4";
CM_ SG_ 2147487815 VAux3Measured "Auxiliary voltage used for offset of current and voltage measurement";
CM_ SG_ 2147487815 TCell2N1 "Temperature number 1 of cell 2";
CM_ SG_ 2147487815 NConfigCrc "CRC of the CONFIG";
CM_ SG_ 2147487815 NSettingsCrc "CRC of the SETTINGS";
CM_ SG_ 2147487815 NSerial "Product Serial Number";
CM_ SG_ 2147487815 VAuxCell3N1 "Auxiliary voltage number 1 of cell 3";
CM_ SG_ 2147487815 VAuxCell1N2 "Auxiliary voltage number 2 of cell 1";
CM_ SG_ 2147487815 VAuxCell3N3 "Auxiliary voltage number 3 of cell 3";
CM_ SG_ 2147487815 TCell3N3 "Temperature number 3 of cell 3";
CM_ SG_ 2147487815 VAux2Measured "Auxiliary voltage 3V3 value";
CM_ SG_ 2147487815 TCell1N2 "Temperature number 2 of cell 1";
CM_ SG_ 2147487815 TCell4N2 "Temperature number 2 of cell 4";
CM_ SG_ 2147487815 NCellXcpErrorFlags "Indicates Xcp error on cells";
CM_ SG_ 2147487815 VAuxCell2N1 "Auxiliary voltage number 1 of cell 2";
CM_ SG_ 2147487815 VAuxCell2N3 "Auxiliary voltage number 3 of cell 2";
CM_ SG_ 2147487815 TCell2N3 "Temperature number 3 of cell 2";
CM_ SG_ 2147487815 VAux1Measured "Auxiliary voltage LV value";
CM_ SG_ 2147487815 TCell1N1 "Temperature number 1 of cell 1";
CM_ SG_ 2147487815 TCell4N1 "Temperature number 1 of cell 4";
CM_ SG_ 2147487815 NConfigVersion "Version number of the CONFIG";
CM_ SG_ 2147487815 NSettingsVersion "Version number of the SETTINGS";
CM_ SG_ 2147487815 NChecksum "Checksum of the application program";
CM_ SG_ 2147487815 NCellSwOcpErrorFlags "Indicates Sw overcurrent protection ";
CM_ SG_ 2147487815 VAuxCell1N1 "Auxiliary voltage number 1 of cell 1";
CM_ SG_ 2147487815 VAuxCell1N3 "Auxiliary voltage number 3 of cell 1";
CM_ SG_ 2147487815 TCell1N3 "Temperature number 3 of cell 1";
CM_ SG_ 2147487815 NMultiplexer "Multiplexer ID";
CM_ BO_ 2147489479 "Value of all parameters of the configuration and settings";
CM_ SG_ 2147489479 NParameterValue "Value of the 16bits word";
CM_ SG_ 2147489479 NParameterIndex "Index at which the word is read in the selected zone";
CM_ SG_ 2147489479 NReadZoneSelect "Zone in which to read the parameters";
CM_ BO_ 2147489414 "Response message giving the present values of the setpoints ";
CM_ SG_ 2147489414 IqPath1AcLimitLo "Power path 1 AC Iq lower limitation";
CM_ SG_ 2147489414 IqPath1AcLimitHi "Power path 1 AC Iq upper limitation";
CM_ SG_ 2147489414 PPath2LimitLo "Power path 2 power lower limitation";
CM_ SG_ 2147489414 IqPath1AcSetpoint "Power path 1 AC Iq setpoint";
CM_ SG_ 2147489414 IdPath1AcLimitLo "Power path 1 AC Id lower limitation";
CM_ SG_ 2147489414 IdPath1AcSetpoint "Power path 1 AC Id setpoint";
CM_ SG_ 2147489414 IdPath1AcLimitHi "Power path 1 AC Id upper limitation";
CM_ SG_ 2147489414 PPath2LimitHi "Power path 2 power upper limitation";
CM_ SG_ 2147489414 NMultiplexer "Multiplexer ID:  the power path's number of the setpoints";
CM_ BO_ 2147489350 "Response message giving the present values of the setpoints ";
CM_ SG_ 2147489350 NPath1AcFunctionMode "Power path 1 AC Function mode select";
CM_ SG_ 2147489350 NPath2CurrentSideSelected "Point of current limitation of Power path 2";
CM_ SG_ 2147489350 NPath2VoltageSideSelected "Point of voltage regulation of Power path 2";
CM_ SG_ 2147489350 NPath1AcFrequencySetpoint "Power path 1 AC frequency setpoint";
CM_ SG_ 2147489350 IPath2LimitLo "Power path 2 current lower limitation";
CM_ SG_ 2147489350 VqPath1AcSetpoint "Power path 1 AC Vq setpoint";
CM_ SG_ 2147489350 VdPath1AcSetpoint "Power path 1 AC Vd setpoint";
CM_ SG_ 2147489350 IPath2LimitHi "Power path 2 current upper limitation";
CM_ SG_ 2147489350 VDcPath1AcSetpoint "Power path 1 AC Vdc setpoint";
CM_ SG_ 2147489350 VPath2Setpoint "Power path 2 voltage setpoint";
CM_ SG_ 2147489350 NMultiplexer "Multiplexer ID:  the power path's number of the setpoints";
CM_ BO_ 2147488390 "Values of internal parameters on PowerPath1";
CM_ SG_ 2147488390 VPath1FlgCapaLvl2Max "Maximum value of the flying capa level 2 voltage of the power path 1 seen since the last message sent";
CM_ SG_ 2147488390 VPath1FlgCapaLvl2Min "Minimum value of the flying capa level 2 voltage of the power path 1 seen since the last message sent";
CM_ SG_ 2147488390 VPath1FlgCapaLvl1Max "Maximum value of the flying capa level 1 voltage of the power path 1 seen since the last message sent";
CM_ SG_ 2147488390 VPath1FlgCapaLvl1Min "Minimum value of the flying capa level 1 voltage of the power path 1 seen since the last message sent";
CM_ BO_ 2147488454 "Values of internal parameters on PowerPath2";
CM_ SG_ 2147488454 VPath2FlgCapaLvl2Max "Maximum value of the flying capa level 2 voltage of the power path 2 seen since the last message sent";
CM_ SG_ 2147488454 VPath2FlgCapaLvl2Min "Minimum value of the flying capa level 2 voltage of the power path 2 seen since the last message sent";
CM_ SG_ 2147488454 VPath2FlgCapaLvl1Max "Maximum value of the flying capa level 1 voltage of the power path 2 seen since the last message sent";
CM_ SG_ 2147488454 VPath2FlgCapaLvl1Min "Minimum value of the flying capa level 1 voltage of the power path 2 seen since the last message sent";
CM_ BO_ 2147488774 "Values of port B1";
CM_ SG_ 2147488774 NPortB1OverloadCount "Counter indicating the number of times an overload is detected on port B1";
CM_ SG_ 2147488774 IPortB1Average "Average value of the port B1 current";
CM_ SG_ 2147488774 VPortB1Average "Average value of the port B1 voltage";
CM_ SG_ 2147488774 VPortB1Max "Maximum value of the  port B1 voltage seen since the last message sent";
CM_ SG_ 2147488774 VPortB1Min "Minimum value of the port B1 voltage seen since the last message sent";
CM_ BO_ 2147487878 "Values of port A1 ";
CM_ SG_ 2147487878 NMultiplexer "Multiplexer ID";
CM_ SG_ 2147487878 IqPhAPortA1RMS "RMS value of the Iq on phase A";
CM_ SG_ 2147487878 IqPortA1RMS "RMS value of the Iq on Port";
CM_ SG_ 2147487878 NFrequencyPortA1 "Frequency of the AC network";
CM_ SG_ 2147487878 IqPhCPortA1RMS "RMS value of the Iq on phase C";
CM_ SG_ 2147487878 IdPhAPortA1RMS "RMS value of the Id on phase A";
CM_ SG_ 2147487878 IdPortA1RMS "RMS value of the Id on Port";
CM_ SG_ 2147487878 VphCPortA1Peak "Peak value of the voltage on phase C";
CM_ SG_ 2147487878 IdPhCPortA1RMS "RMS value of the Id on phase C";
CM_ SG_ 2147487878 IphCPortA1Peak "Peak value of the current on phase C";
CM_ SG_ 2147487878 VqPortA1RMS "RMS value of the Vq";
CM_ SG_ 2147487878 VphBPortA1Peak "Peak value of the voltage on phase B";
CM_ SG_ 2147487878 IqPhBPortA1RMS "RMS value of the Iq on phase B";
CM_ SG_ 2147487878 IphBPortA1Peak "Peak value of the current on phase B";
CM_ SG_ 2147487878 VdPortA1RMS "RMS value of the Vd";
CM_ SG_ 2147487878 VphAPortA1Peak "Peak value of the voltage on phase A";
CM_ SG_ 2147487878 IphAPortA1Peak "Peak value of the current on phase A";
CM_ SG_ 2147487878 IdPhBPortA1RMS "RMS value of the Id on phase B";
CM_ BO_ 2147487942 "Values of port A2 ";
CM_ SG_ 2147487942 NMultiplexer "Multiplexer ID";
CM_ SG_ 2147487942 NPortA2OverloadCount "Counter indicating the number of times an overload is detected on port A2";
CM_ SG_ 2147487942 IPortA2Average "Average value of the port A2 current";
CM_ SG_ 2147487942 VPortA2Average "Average value of the port A2 voltage";
CM_ SG_ 2147487942 VPortA2Max "Maximum value of the  port A2 voltage seen since the last message sent";
CM_ SG_ 2147487942 VPortA2Min "Minimum value of the port A2 voltage seen since the last message sent";
CM_ BO_ 2147489478 "Value of all parameters of the configuration and settings";
CM_ SG_ 2147489478 NParameterValue "Value of the 16bits word";
CM_ SG_ 2147489478 NParameterIndex "Index at which the word is read in the selected zone";
CM_ SG_ 2147489478 NReadZoneSelect "Zone in which to read the parameters";
BA_DEF_  "Baudrate" INT 0 1000000;
BA_DEF_  "Bootloader Range Address" STRING ;
BA_DEF_  "Application Range Address" STRING ;
BA_DEF_ BO_  "CanDootDecode" ENUM  "No","Yes";
BA_DEF_ BO_  "CanDootDecodeBus" INT 0 6;
BA_DEF_ BO_  "CanDootPaused" ENUM  "No","Yes";
BA_DEF_ BO_  "CanDootSimulateCycleTime" INT 0 50000;
BA_DEF_ BO_  "CG_RX_TX" ENUM  "RX","TX","NONE";
BA_DEF_ SG_  "CanDootHidden" ENUM  "No","Yes";
BA_DEF_ SG_  "CanDootBroadcast" ENUM  "No","Yes";
BA_DEF_ SG_  "CG_VarType" ENUM  "bool","uint8_t","int8_t","uint16_t","int16_t","uint32_t","int32_t","uin64_t","int64_t","float","double";
BA_DEF_  "MultiplexExtEnabled" ENUM  "No","Yes";
BA_DEF_DEF_  "Baudrate" 500000;
BA_DEF_DEF_  "Bootloader Range Address" "";
BA_DEF_DEF_  "Application Range Address" "";
BA_DEF_DEF_  "CanDootDecode" "Yes";
BA_DEF_DEF_  "CanDootDecodeBus" 1;
BA_DEF_DEF_  "CanDootPaused" "Yes";
BA_DEF_DEF_  "CanDootSimulateCycleTime" 100;
BA_DEF_DEF_  "CG_RX_TX" "RX";
BA_DEF_DEF_  "CanDootHidden" "No";
BA_DEF_DEF_  "CanDootBroadcast" "No";
BA_DEF_DEF_  "CG_VarType" "uint8_t";
BA_DEF_DEF_  "MultiplexExtEnabled" "Yes";
BA_ "Bootloader Range Address" "0x0FFFF000";
BA_ "Application Range Address" "0x00001000";
BA_ "CanDootDecode" BO_ 2147487747 0;
BA_ "CanDootPaused" BO_ 2147487747 0;
BA_ "CanDootDecode" BO_ 2147489411 0;
BA_ "CanDootPaused" BO_ 2147489411 0;
BA_ "CanDootDecode" BO_ 2147489347 0;
BA_ "CanDootPaused" BO_ 2147489347 0;
BA_ "CanDootDecode" BO_ 2147488771 0;
BA_ "CanDootPaused" BO_ 2147488771 0;
BA_ "CanDootDecode" BO_ 2147487875 0;
BA_ "CanDootPaused" BO_ 2147487875 0;
BA_ "CanDootDecode" BO_ 2147487939 0;
BA_ "CanDootPaused" BO_ 2147487939 0;
BA_ "CanDootDecode" BO_ 2147488387 0;
BA_ "CanDootDecode" BO_ 2147488451 0;
BA_ "CanDootDecode" BO_ 2147487811 0;
BA_ "CanDootDecode" BO_ 2147489475 0;
BA_ "CanDootDecode" BO_ 2147489410 0;
BA_ "CanDootPaused" BO_ 2147489410 0;
BA_ "CanDootDecode" BO_ 2147489346 0;
BA_ "CanDootPaused" BO_ 2147489346 0;
BA_ "CanDootDecode" BO_ 2147488450 0;
BA_ "CanDootDecode" BO_ 2147488770 0;
BA_ "CanDootPaused" BO_ 2147488770 0;
BA_ "CanDootPaused" BO_ 2147488127 0;
BA_ "CanDootPaused" BO_ 2147488063 0;
BA_ "CanDootPaused" BO_ 2147487999 0;
BA_ "CanDootPaused" BO_ 2147488191 0;
BA_ "CanDootPaused" BO_ 2147488255 0;
BA_ "CanDootDecode" BO_ 2147487938 0;
BA_ "CanDootPaused" BO_ 2147487938 0;
BA_ "CanDootDecode" BO_ 2147489474 0;
BA_ "CanDootDecode" BO_ 2147487810 0;
BA_ "CanDootDecode" BO_ 2147487746 0;
BA_ "CanDootPaused" BO_ 2147487746 0;
BA_ "CanDootPaused" BO_ 2147487935 0;
BA_ "CanDootPaused" BO_ 2147487749 0;
BA_ "CanDootPaused" BO_ 2147489413 0;
BA_ "CanDootPaused" BO_ 2147489349 0;
BA_ "CanDootPaused" BO_ 2147488773 0;
BA_ "CanDootPaused" BO_ 2147487877 0;
BA_ "CanDootPaused" BO_ 2147487941 0;
BA_ "CanDootPaused" BO_ 2147489412 0;
BA_ "CanDootPaused" BO_ 2147489348 0;
BA_ "CanDootPaused" BO_ 2147488772 0;
BA_ "CanDootPaused" BO_ 2147487876 0;
BA_ "CanDootPaused" BO_ 2147487940 0;
BA_ "CanDootPaused" BO_ 2147487748 0;
BA_ "CanDootPaused" BO_ 2147487751 0;
BA_ "CanDootPaused" BO_ 2147489415 0;
BA_ "CanDootPaused" BO_ 2147489351 0;
BA_ "CanDootPaused" BO_ 2147488775 0;
BA_ "CanDootPaused" BO_ 2147487879 0;
BA_ "CanDootPaused" BO_ 2147487943 0;
BA_ "CanDootPaused" BO_ 2147489414 0;
BA_ "CanDootPaused" BO_ 2147489350 0;
BA_ "CanDootPaused" BO_ 2147488774 0;
BA_ "CanDootPaused" BO_ 2147487878 0;
BA_ "CanDootPaused" BO_ 2147487942 0;
BA_ "CanDootHidden" SG_ 2147487747 NMultiplexer 1;
BA_ "CanDootHidden" SG_ 2147489411 NMultiplexer 1;
BA_ "CanDootHidden" SG_ 2147489347 NMultiplexer 1;
BA_ "CanDootHidden" SG_ 2147487875 NMultiplexer 1;
BA_ "CanDootHidden" SG_ 2147487939 NMultiplexer 1;
BA_ "CanDootHidden" SG_ 2147487811 NConfigCrc 1;
BA_ "CanDootHidden" SG_ 2147487811 NSettingsCrc 1;
BA_ "CanDootHidden" SG_ 2147487811 NMultiplexer 1;
BA_ "CanDootHidden" SG_ 2147489410 NMultiplexer 1;
BA_ "CanDootHidden" SG_ 2147489346 NMultiplexer 1;
BA_ "CanDootHidden" SG_ 2147488127 NCrc 1;
BA_ "CanDootHidden" SG_ 2147488063 NCrc 1;
BA_ "CanDootHidden" SG_ 2147488063 NModuleSelect 1;
BA_ "CanDootHidden" SG_ 2147487999 NCrc 1;
BA_ "CanDootHidden" SG_ 2147487999 NModuleSelect 1;
BA_ "CanDootHidden" SG_ 2147487999 BL1_NMultiplexer 1;
BA_ "CanDootHidden" SG_ 2147487999 BL2_NMultiplexer 1;
BA_ "CanDootHidden" SG_ 2147487999 BL3_NMultiplexer 1;
BA_ "CanDootHidden" SG_ 2147487999 BL4_NMultiplexer 1;
BA_ "CanDootHidden" SG_ 2147488191 NCrc 1;
BA_ "CanDootHidden" SG_ 2147488191 NModuleSelect 1;
BA_ "CanDootHidden" SG_ 2147488191 BL1_NMultiplexer 1;
BA_ "CanDootHidden" SG_ 2147488191 BL2_NMultiplexer 1;
BA_ "CanDootHidden" SG_ 2147488191 BL3_NMultiplexer 1;
BA_ "CanDootHidden" SG_ 2147488191 BL4_NMultiplexer 1;
BA_ "CanDootHidden" SG_ 2147488255 NCrc 1;
BA_ "CanDootHidden" SG_ 2147488255 NModuleSelect 1;
BA_ "CanDootHidden" SG_ 2147488255 BL1_NMultiplexer 1;
BA_ "CanDootHidden" SG_ 2147488255 BL2_NMultiplexer 1;
BA_ "CanDootHidden" SG_ 2147488255 BL3_NMultiplexer 1;
BA_ "CanDootHidden" SG_ 2147488255 BL4_NMultiplexer 1;
BA_ "CanDootHidden" SG_ 2147487938 NMultiplexer 1;
BA_ "CanDootHidden" SG_ 2147487810 NConfigCrc 1;
BA_ "CanDootHidden" SG_ 2147487810 NSettingsCrc 1;
BA_ "CanDootHidden" SG_ 2147487810 NMultiplexer 1;
BA_ "CanDootHidden" SG_ 2147487746 NMultiplexer 1;
BA_ "CanDootHidden" SG_ 2147487935 NCrc 1;
BA_ "CanDootHidden" SG_ 2147487935 NModuleSelect 1;
BA_ "CanDootHidden" SG_ 2147487935 BL1_NMultiplexer 1;
BA_ "CanDootHidden" SG_ 2147487935 BL2_NMultiplexer 1;
BA_ "CanDootHidden" SG_ 2147487935 BL3_NMultiplexer 1;
BA_ "CanDootHidden" SG_ 2147487935 BL4_NMultiplexer 1;
BA_ "CanDootHidden" SG_ 2147487807 NCrc 1;
BA_ "CanDootHidden" SG_ 2147487807 NModuleSelect 1;
BA_ "CanDootHidden" SG_ 2147487749 NMultiplexer 1;
BA_ "CanDootHidden" SG_ 2147489413 NMultiplexer 1;
BA_ "CanDootHidden" SG_ 2147489349 NMultiplexer 1;
BA_ "CanDootHidden" SG_ 2147487877 NMultiplexer 1;
BA_ "CanDootHidden" SG_ 2147487941 NMultiplexer 1;
BA_ "CanDootHidden" SG_ 2147487813 NSettingsCrc 1;
BA_ "CanDootHidden" SG_ 2147487813 NConfigCrc 1;
BA_ "CanDootHidden" SG_ 2147487813 NMultiplexer 1;
BA_ "CanDootHidden" SG_ 2147489412 NMultiplexer 1;
BA_ "CanDootHidden" SG_ 2147489348 NMultiplexer 1;
BA_ "CanDootBroadcast" SG_ 2147488772 NPortB1OverloadCount 1;
BA_ "CanDootBroadcast" SG_ 2147488772 IPortB1Average 1;
BA_ "CanDootBroadcast" SG_ 2147488772 VPortB1Average 1;
BA_ "CanDootBroadcast" SG_ 2147488772 VPortB1Max 1;
BA_ "CanDootBroadcast" SG_ 2147488772 VPortB1Min 1;
BA_ "CanDootHidden" SG_ 2147487876 NMultiplexer 1;
BA_ "CanDootHidden" SG_ 2147487940 NMultiplexer 1;
BA_ "CanDootHidden" SG_ 2147487812 NSettingsCrc 1;
BA_ "CanDootHidden" SG_ 2147487812 NConfigCrc 1;
BA_ "CanDootHidden" SG_ 2147487812 NMultiplexer 1;
BA_ "CanDootHidden" SG_ 2147487748 NMultiplexer 1;
BA_ "CanDootHidden" SG_ 2147487751 NMultiplexer 1;
BA_ "CanDootHidden" SG_ 2147489415 NMultiplexer 1;
BA_ "CanDootHidden" SG_ 2147489351 NMultiplexer 1;
BA_ "CanDootHidden" SG_ 2147487879 NMultiplexer 1;
BA_ "CanDootHidden" SG_ 2147487943 NMultiplexer 1;
BA_ "CanDootHidden" SG_ 2147487815 NConfigCrc 1;
BA_ "CanDootHidden" SG_ 2147487815 NSettingsCrc 1;
BA_ "CanDootBroadcast" SG_ 2147487815 TCell1N1 1;
BA_ "CanDootHidden" SG_ 2147487815 NMultiplexer 1;
BA_ "CanDootHidden" SG_ 2147489414 NMultiplexer 1;
BA_ "CanDootHidden" SG_ 2147489350 NMultiplexer 1;
BA_ "CanDootHidden" SG_ 2147487878 NMultiplexer 1;
BA_ "CanDootHidden" SG_ 2147487942 NMultiplexer 1;
SIG_GROUP_ 2147487999 DcSetpoints2Write 1 : BL1_PPath2LimitHi BL1_PPath2LimitLo;
SIG_GROUP_ 2147487999 ACUHV_DcSetpoints2Write 1 : BL1_PPath2LimitHi BL1_PPath2LimitLo;
SIG_GROUP_ 2147488191 AcSetpoints1Write 1 : BL1_VDcPath1AcSetpoint BL1_VdPath1AcSetpoint BL1_VqPath1AcSetpoint BL1_NPath1AcFrequencySetpoint;
SIG_GROUP_ 2147488191 ACUHV_AcSetpoints1Write 1 : BL1_VDcPath1AcSetpoint BL1_VdPath1AcSetpoint BL1_VqPath1AcSetpoint BL1_NPath1AcFrequencySetpoint;
SIG_GROUP_ 2147488255 AcSetpoints2Write 1 : BL1_NPath1AcFunctionMode BL1_IdPath1AcLimitHi BL1_IdPath1AcSetpoint BL1_IdPath1AcLimitLo BL1_IqPath1AcSetpoint BL1_IqPath1AcLimitHi BL1_IqPath1AcLimitLo;
SIG_GROUP_ 2147488255 ACUHV_AcSetpoints2Write 1 : BL1_NPath1AcFunctionMode BL1_IdPath1AcLimitHi BL1_IdPath1AcSetpoint BL1_IdPath1AcLimitLo BL1_IqPath1AcSetpoint BL1_IqPath1AcLimitHi BL1_IqPath1AcLimitLo;
SIG_GROUP_ 2147487935 DcSetpoints1Write 1 : BL1_VPath2Setpoint BL1_IPath2LimitHi BL1_IPath2LimitLo BL1_NPath2VoltageSideSelect BL1_NPath2CurrentSideSelect;
SIG_GROUP_ 2147487935 ACUHV_DcSetpoints1Write 1 : BL1_VPath2Setpoint BL1_IPath2LimitHi BL1_IPath2LimitLo BL1_NPath2VoltageSideSelect BL1_NPath2CurrentSideSelect;
SIG_GROUP_ 2147487749 BL2_Node5Status_Global 1 : BXcpError NCellHwErrorFlags BSyncInputSignal BSyncRequested BInternalTemperatureError BConfigSettingsError BAuxSupplyError BCanTimeoutError BAuxIsoEnabled BSafetyDischargeEnabled BFaultSignal BEnableSignal BSafetyDischargeStatus BSyncStatus BReadConfigAndSettingsRequested BSwResetModuleRequested BSafetyDischargeRequested NModuleState;
SIG_GROUP_ 2147487749 BL2_Node5Status_Path2 1 : BPath2FlgCapaError BPath2ErrVAuxCell IPath2Unbalance BPath2RcpWarning BPath2OcpError BPath2OtpError BPath2SideBUvpError BPath2SideAUvpError BPath2SideBOvpError BPath2SideAOvpError BPath2Requested NPath2CurrentSideSelected NPath2VoltageSideSelected NPath2State;
SIG_GROUP_ 2147487749 BL2_Node5Status_Path1 1 : BPath1AcModeActivated BPath1AcUfpError BPath1AcOfpError NPath1AcFunctionMode BPath1FlgCapaError BPath1ErrVAuxCell IPath1Unbalance BPath1RcpWarning BPath1OcpError BPath1OtpError BPath1SideBUvpError BPath1SideAUvpError BPath1SideBOvpError BPath1SideAOvpError BPath1Requested NPath1CurrentSideSelected NPath1VoltageSideSelected NPath1State;
SIG_GROUP_ 2147487748 BL2_Node4Status_Global 1 : BXcpError NCellHwErrorFlags BSyncInputSignal BSyncRequested BInternalTemperatureError BConfigSettingsError BAuxSupplyError BCanTimeoutError BAuxIsoEnabled BSafetyDischargeEnabled BFaultSignal BEnableSignal BSafetyDischargeStatus BSyncStatus BReadConfigAndSettingsRequested BSwResetModuleRequested BSafetyDischargeRequested NModuleState;
SIG_GROUP_ 2147487748 BL2_Node4Status_Path2 1 : BPath2FlgCapaError BPath2ErrVAuxCell IPath2Unbalance BPath2RcpWarning BPath2OcpError BPath2OtpError BPath2SideBUvpError BPath2SideAUvpError BPath2SideBOvpError BPath2SideAOvpError BPath2Requested NPath2CurrentSideSelected NPath2VoltageSideSelected NPath2State;
SIG_GROUP_ 2147487748 BL2_Node4Status_Path1 1 : BPath1AcModeActivated BPath1AcUfpError BPath1AcOfpError NPath1AcFunctionMode BPath1FlgCapaError BPath1ErrVAuxCell IPath1Unbalance BPath1RcpWarning BPath1OcpError BPath1OtpError BPath1SideBUvpError BPath1SideAUvpError BPath1SideBOvpError BPath1SideAOvpError BPath1Requested NPath1CurrentSideSelected NPath1VoltageSideSelected NPath1State;

SG_MUL_VAL_ 2147487999 BL1_PPath2LimitLo BL1_NMultiplexer 2-2;
SG_MUL_VAL_ 2147487999 BL2_PPath2LimitLo BL2_NMultiplexer 2-2;
SG_MUL_VAL_ 2147487999 BL3_PPath2LimitLo BL3_NMultiplexer 2-2;
SG_MUL_VAL_ 2147487999 BL4_PPath2LimitLo BL4_NMultiplexer 2-2;
SG_MUL_VAL_ 2147487999 BL1_PPath2LimitHi BL1_NMultiplexer 2-2;
SG_MUL_VAL_ 2147487999 BL2_PPath2LimitHi BL2_NMultiplexer 2-2;
SG_MUL_VAL_ 2147487999 BL3_PPath2LimitHi BL3_NMultiplexer 2-2;
SG_MUL_VAL_ 2147487999 BL4_PPath2LimitHi BL4_NMultiplexer 2-2;
SG_MUL_VAL_ 2147487999 BL1_NMultiplexer NModuleSelect 1-1;
SG_MUL_VAL_ 2147487999 BL2_NMultiplexer NModuleSelect 2-2;
SG_MUL_VAL_ 2147487999 BL3_NMultiplexer NModuleSelect 3-3;
SG_MUL_VAL_ 2147487999 BL4_NMultiplexer NModuleSelect 4-4;
SG_MUL_VAL_ 2147488191 BL1_NPath1AcFrequencySetpoint BL1_NMultiplexer 1-1;
SG_MUL_VAL_ 2147488191 BL2_NPath1AcFrequencySetpoint BL2_NMultiplexer 1-1;
SG_MUL_VAL_ 2147488191 BL3_NPath1AcFrequencySetpoint BL3_NMultiplexer 1-1;
SG_MUL_VAL_ 2147488191 BL4_NPath1AcFrequencySetpoint BL4_NMultiplexer 1-1;
SG_MUL_VAL_ 2147488191 BL1_VqPath1AcSetpoint BL1_NMultiplexer 1-1;
SG_MUL_VAL_ 2147488191 BL2_VqPath1AcSetpoint BL2_NMultiplexer 1-1;
SG_MUL_VAL_ 2147488191 BL3_VqPath1AcSetpoint BL3_NMultiplexer 1-1;
SG_MUL_VAL_ 2147488191 BL4_VqPath1AcSetpoint BL4_NMultiplexer 1-1;
SG_MUL_VAL_ 2147488191 BL1_VdPath1AcSetpoint BL1_NMultiplexer 1-1;
SG_MUL_VAL_ 2147488191 BL2_VdPath1AcSetpoint BL2_NMultiplexer 1-1;
SG_MUL_VAL_ 2147488191 BL3_VdPath1AcSetpoint BL3_NMultiplexer 1-1;
SG_MUL_VAL_ 2147488191 BL4_VdPath1AcSetpoint BL4_NMultiplexer 1-1;
SG_MUL_VAL_ 2147488191 BL1_VDcPath1AcSetpoint BL1_NMultiplexer 1-1;
SG_MUL_VAL_ 2147488191 BL2_VDcPath1AcSetpoint BL2_NMultiplexer 1-1;
SG_MUL_VAL_ 2147488191 BL3_VDcPath1AcSetpoint BL3_NMultiplexer 1-1;
SG_MUL_VAL_ 2147488191 BL4_VDcPath1AcSetpoint BL4_NMultiplexer 1-1;
SG_MUL_VAL_ 2147488191 BL1_NMultiplexer NModuleSelect 1-1;
SG_MUL_VAL_ 2147488191 BL2_NMultiplexer NModuleSelect 2-2;
SG_MUL_VAL_ 2147488191 BL3_NMultiplexer NModuleSelect 3-3;
SG_MUL_VAL_ 2147488191 BL4_NMultiplexer NModuleSelect 4-4;
SG_MUL_VAL_ 2147488255 BL1_IqPath1AcLimitLo BL1_NMultiplexer 1-1;
SG_MUL_VAL_ 2147488255 BL2_IqPath1AcLimitLo BL2_NMultiplexer 1-1;
SG_MUL_VAL_ 2147488255 BL3_IqPath1AcLimitLo BL3_NMultiplexer 1-1;
SG_MUL_VAL_ 2147488255 BL4_IqPath1AcLimitLo BL4_NMultiplexer 1-1;
SG_MUL_VAL_ 2147488255 BL1_IqPath1AcLimitHi BL1_NMultiplexer 1-1;
SG_MUL_VAL_ 2147488255 BL2_IqPath1AcLimitHi BL2_NMultiplexer 1-1;
SG_MUL_VAL_ 2147488255 BL3_IqPath1AcLimitHi BL3_NMultiplexer 1-1;
SG_MUL_VAL_ 2147488255 BL4_IqPath1AcLimitHi BL4_NMultiplexer 1-1;
SG_MUL_VAL_ 2147488255 BL1_IqPath1AcSetpoint BL1_NMultiplexer 5-5;
SG_MUL_VAL_ 2147488255 BL1_IdPath1AcLimitLo BL1_NMultiplexer 1-1;
SG_MUL_VAL_ 2147488255 BL2_IdPath1AcLimitLo BL2_NMultiplexer 1-1;
SG_MUL_VAL_ 2147488255 BL2_IqPath1AcSetpoint BL2_NMultiplexer 5-5;
SG_MUL_VAL_ 2147488255 BL3_IqPath1AcSetpoint BL3_NMultiplexer 5-5;
SG_MUL_VAL_ 2147488255 BL3_IdPath1AcLimitLo BL3_NMultiplexer 1-1;
SG_MUL_VAL_ 2147488255 BL4_IqPath1AcSetpoint BL4_NMultiplexer 5-5;
SG_MUL_VAL_ 2147488255 BL4_IdPath1AcLimitLo BL4_NMultiplexer 1-1;
SG_MUL_VAL_ 2147488255 BL1_IdPath1AcSetpoint BL1_NMultiplexer 5-5;
SG_MUL_VAL_ 2147488255 BL1_IdPath1AcLimitHi BL1_NMultiplexer 1-1;
SG_MUL_VAL_ 2147488255 BL2_IdPath1AcLimitHi BL2_NMultiplexer 1-1;
SG_MUL_VAL_ 2147488255 BL2_IdPath1AcSetpoint BL2_NMultiplexer 5-5;
SG_MUL_VAL_ 2147488255 BL3_IdPath1AcSetpoint BL3_NMultiplexer 5-5;
SG_MUL_VAL_ 2147488255 BL3_IdPath1AcLimitHi BL3_NMultiplexer 1-1;
SG_MUL_VAL_ 2147488255 BL4_IdPath1AcSetpoint BL4_NMultiplexer 5-5;
SG_MUL_VAL_ 2147488255 BL4_IdPath1AcLimitHi BL4_NMultiplexer 1-1;
SG_MUL_VAL_ 2147488255 BL1_NPath1AcFunctionMode BL1_NMultiplexer 1-1;
SG_MUL_VAL_ 2147488255 BL2_NPath1AcFunctionMode BL2_NMultiplexer 1-1;
SG_MUL_VAL_ 2147488255 BL3_NPath1AcFunctionMode BL3_NMultiplexer 1-1;
SG_MUL_VAL_ 2147488255 BL4_NPath1AcFunctionMode BL4_NMultiplexer 1-1;
SG_MUL_VAL_ 2147488255 BL1_NMultiplexer NModuleSelect 1-1;
SG_MUL_VAL_ 2147488255 BL2_NMultiplexer NModuleSelect 2-2;
SG_MUL_VAL_ 2147488255 BL3_NMultiplexer NModuleSelect 3-3;
SG_MUL_VAL_ 2147488255 BL4_NMultiplexer NModuleSelect 4-4;
SG_MUL_VAL_ 2147487935 BL1_NPath2CurrentSideSelect BL1_NMultiplexer 2-2;
SG_MUL_VAL_ 2147487935 BL2_NPath2CurrentSideSelect BL2_NMultiplexer 2-2;
SG_MUL_VAL_ 2147487935 BL3_NPath2CurrentSideSelect BL3_NMultiplexer 2-2;
SG_MUL_VAL_ 2147487935 BL4_NPath2CurrentSideSelect BL4_NMultiplexer 2-2;
SG_MUL_VAL_ 2147487935 BL1_NPath2VoltageSideSelect BL1_NMultiplexer 2-2;
SG_MUL_VAL_ 2147487935 BL2_NPath2VoltageSideSelect BL2_NMultiplexer 2-2;
SG_MUL_VAL_ 2147487935 BL3_NPath2VoltageSideSelect BL3_NMultiplexer 2-2;
SG_MUL_VAL_ 2147487935 BL4_NPath2VoltageSideSelect BL4_NMultiplexer 2-2;
SG_MUL_VAL_ 2147487935 BL1_IPath2LimitLo BL1_NMultiplexer 2-2;
SG_MUL_VAL_ 2147487935 BL2_IPath2LimitLo BL2_NMultiplexer 2-2;
SG_MUL_VAL_ 2147487935 BL3_IPath2LimitLo BL3_NMultiplexer 2-2;
SG_MUL_VAL_ 2147487935 BL4_IPath2LimitLo BL4_NMultiplexer 2-2;
SG_MUL_VAL_ 2147487935 BL1_IPath2LimitHi BL1_NMultiplexer 2-2;
SG_MUL_VAL_ 2147487935 BL2_IPath2LimitHi BL2_NMultiplexer 2-2;
SG_MUL_VAL_ 2147487935 BL3_IPath2LimitHi BL3_NMultiplexer 2-2;
SG_MUL_VAL_ 2147487935 BL4_IPath2LimitHi BL4_NMultiplexer 2-2;
SG_MUL_VAL_ 2147487935 BL1_VPath2Setpoint BL1_NMultiplexer 2-2;
SG_MUL_VAL_ 2147487935 BL2_VPath2Setpoint BL2_NMultiplexer 2-2;
SG_MUL_VAL_ 2147487935 BL3_VPath2Setpoint BL3_NMultiplexer 2-2;
SG_MUL_VAL_ 2147487935 BL4_VPath2Setpoint BL4_NMultiplexer 2-2;
SG_MUL_VAL_ 2147487935 BL1_NMultiplexer NModuleSelect 1-1;
SG_MUL_VAL_ 2147487935 BL2_NMultiplexer NModuleSelect 2-2;
SG_MUL_VAL_ 2147487935 BL3_NMultiplexer NModuleSelect 3-3;
SG_MUL_VAL_ 2147487935 BL4_NMultiplexer NModuleSelect 4-4;
